VERSION ""

NS_ :

BS_:

BU_: MDC PAS

BO_ 773 Mdc_Sensor_Version: 8 MDC
 SG_ sensorVersion : 2|8@0+ (1,0) [0|8] "bit"  PAS

BO_ 1694 P2_ZPY2_CANFD_14: 64 PAS
 SG_ P2_ZPY2_CANFD_14 : 7|512@0+ (1,0) [0|0] ""  MDC

BO_ 1693 P2_ZPY2_CANFD_13: 64 PAS
 SG_ P2_ZPY2_CANFD_13 : 7|512@0+ (1,0) [0|0] ""  MDC

BO_ 1692 P2_ZPY2_CANFD_12: 64 PAS
 SG_ P2_ZPY2_CANFD_12 : 7|512@0+ (1,0) [0|0] ""  MDC

BO_ 1691 P2_ZPY2_CANFD_11: 64 PAS
 SG_ P2_ZPY2_CANFD_11 : 7|512@0+ (1,0) [0|0] ""  MDC

BO_ 1690 P2_ZPY2_CANFD_10: 64 PAS
 SG_ P2_ZPY2_CANFD_10 : 7|512@0+ (1,0) [0|0] ""  MDC

BO_ 1689 P2_ZPY2_CANFD_9: 64 PAS
 SG_ P2_ZPY2_CANFD_9 : 7|512@0+ (1,0) [0|0] ""  MDC

BO_ 1688 P2_ZPY2_CANFD_8: 64 PAS
 SG_ P2_ZPY2_CANFD_8 : 7|512@0+ (1,0) [0|0] ""  MDC

BO_ 1687 P2_ZPY2_CANFD_7: 64 PAS
 SG_ P2_ZPY2_CANFD_7 : 7|512@0+ (1,0) [0|0] ""  MDC

BO_ 1686 P2_ZPY2_CANFD_6: 64 PAS
 SG_ P2_ZPY2_CANFD_6 : 7|512@0+ (1,0) [0|0] ""  MDC

BO_ 1685 P2_ZPY2_CANFD_5: 64 PAS
 SG_ P2_ZPY2_CANFD_5 : 7|512@0+ (1,0) [0|0] ""  MDC

BO_ 1684 P2_ZPY2_CANFD_4: 64 PAS
 SG_ P2_ZPY2_CANFD_4 : 7|512@0+ (1,0) [0|0] ""  MDC

BO_ 1683 P2_ZPY2_CANFD_3: 64 PAS
 SG_ P2_ZPY2_CANFD_3 : 7|512@0+ (1,0) [0|0] ""  MDC

BO_ 1682 P2_ZPY2_CANFD_2: 64 PAS
 SG_ P2_ZPY2_CANFD_2 : 7|512@0+ (1,0) [0|0] ""  MDC

BO_ 1681 P2_ZPY2_CANFD_1: 64 PAS
 SG_ P2_ZPY2_CANFD_1 : 7|512@0+ (1,0) [0|0] ""  MDC

BO_ 1680 P2_ZPY2_CANFD_0: 64 PAS
 SG_ P2_ZPY2_CANFD_0 : 7|512@0+ (1,0) [0|0] ""  MDC

BO_ 2024 Diag_PDC_RES: 8 PAS
 SG_ Diag_PDC_RES : 7|64@0+ (1,0) [0|0] ""  MDC

BO_ 2016 Diag_PDC_REQ: 8 MDC
 SG_ Diag_PDC_REQ : 7|64@0+ (1,0) [0|0] ""  PAS

BO_ 2015 DIAG_OBD_REQ_Broadcast: 8 MDC
 SG_ Diag_Functional_REQ : 7|64@0+ (1,0) [0|0] ""  PAS

BO_ 513 PAS_Distance_Front: 64 PAS
 SG_ PAS_sonar1_DISTANCE : 455|10@0+ (1,0) [0|1023] "cm"  MDC
 SG_ PASsonar1DISTANCETime : 263|12@0+ (0.5,0) [0|1000] "ms"  MDC
 SG_ PAS_sonar1_Blind : 35|4@0+ (1,0) [0|1] "bit"  MDC
 SG_ PAS_sonar1_crossDistanceLeft : 3|10@0+ (1,0) [0|1023] "cm"  MDC
 SG_ PAS_sonar1_crossDistanceRight : 9|10@0+ (1,0) [0|1023] "cm"  MDC
 SG_ PASsonar1crossDistanceLeftTime : 267|12@0+ (0.5,0) [0|1000] "ms"  MDC
 SG_ PASsonar1crossDistanceRightTime : 287|12@0+ (0.5,0) [0|1000] "ms"  MDC
 SG_ PAS_sonar1_confidence : 31|8@0+ (1,0) [0|100] "%"  MDC
 SG_ Msg201_PAS_sonar1_Counter : 39|4@0+ (1,0) [0|15] "bit"  MDC
 SG_ PAS_sonar2_DISTANCE : 461|10@0+ (1,0) [0|1023] "cm"  MDC
 SG_ PASsonar2DISTANCETime : 291|12@0+ (0.5,0) [0|1000] "ms"  MDC
 SG_ PAS_sonar2_Blind : 75|4@0+ (1,0) [0|1] "bit"  MDC
 SG_ PAS_sonar2_crossDistanceLeft : 43|10@0+ (1,0) [0|1023] "cm"  MDC
 SG_ PAS_sonar2_crossDistanceRight : 49|10@0+ (1,0) [0|1023] "cm"  MDC
 SG_ PASsonar2crossDistanceLeftTime : 311|12@0+ (0.5,0) [0|1000] "ms"  MDC
 SG_ PASsonar2crossDistanceRightTime : 315|12@0+ (0.5,0) [0|1000] "ms"  MDC
 SG_ PAS_sonar2_confidence : 71|8@0+ (1,0) [0|100] "%"  MDC
 SG_ Msg201_PAS_sonar2_Counter : 79|4@0+ (1,0) [0|15] "bit"  MDC
 SG_ PAS_sonar3_DISTANCE : 467|10@0+ (1,0) [0|1023] "cm"  MDC
 SG_ PASsonar3DISTANCETime : 335|12@0+ (0.5,0) [0|1000] "ms"  MDC
 SG_ PAS_sonar3_Blind : 115|4@0+ (1,0) [0|1] "bit"  MDC
 SG_ PAS_sonar3_crossDistanceLeft : 83|10@0+ (1,0) [0|1023] "cm"  MDC
 SG_ PAS_sonar3_crossDistanceRight : 89|10@0+ (1,0) [0|1023] "cm"  MDC
 SG_ PASsonar3crossDistanceLeftTime : 339|12@0+ (0.5,0) [0|1000] "ms"  MDC
 SG_ PASsonar3crossDistanceRightTime : 359|12@0+ (0.5,0) [0|1000] "ms"  MDC
 SG_ PAS_sonar3_confidence : 111|8@0+ (1,0) [0|100] "%"  MDC
 SG_ Msg201_PAS_sonar3_Counter : 119|4@0+ (1,0) [0|15] "bit"  MDC
 SG_ PAS_sonar4_DISTANCE : 473|10@0+ (1,0) [0|1023] "cm"  MDC
 SG_ PASsonar4DISTANCETime : 363|12@0+ (0.5,0) [0|1000] "ms"  MDC
 SG_ PAS_sonar4_Blind : 155|4@0+ (1,0) [0|1] "bit"  MDC
 SG_ PAS_sonar4_crossDistanceLeft : 123|10@0+ (1,0) [0|1023] "cm"  MDC
 SG_ PAS_sonar4_crossDistanceRight : 129|10@0+ (1,0) [0|1023] "cm"  MDC
 SG_ PASsonar4crossDistanceLeftTime : 383|12@0+ (0.5,0) [0|1000] "ms"  MDC
 SG_ PASsonar4crossDistanceRightTime : 387|12@0+ (0.5,0) [0|1000] "ms"  MDC
 SG_ PAS_sonar4_confidence : 151|8@0+ (1,0) [0|100] "%"  MDC
 SG_ Msg201_PAS_sonar4_Counter : 159|4@0+ (1,0) [0|15] "bit"  MDC
 SG_ PAS_sonar0_DISTANCE : 167|10@0+ (1,0) [0|1023] "cm"  MDC
 SG_ PASsonar0DISTANCETime : 407|12@0+ (0.5,0) [0|1000] "ms"  MDC
 SG_ PAS_sonar0_Blind : 235|4@0+ (1,0) [0|1] "bit"  MDC
 SG_ PAS_sonar0_crossDistanceLeft : 173|10@0+ (1,0) [0|1023] "cm"  MDC
 SG_ PAS_sonar0_crossDistanceRight : 179|10@0+ (1,0) [0|1023] "cm"  MDC
 SG_ PASsonar0crossDistanceRightTime : 411|12@0+ (0.5,0) [0|1000] "ms"  MDC
 SG_ PAS_sonar0_confidence : 231|8@0+ (1,0) [0|100] "%"  MDC
 SG_ Msg201_PAS_sonar0_Counter : 239|4@0+ (1,0) [0|15] "bit"  MDC
 SG_ PAS_sonar5_DISTANCE : 185|10@0+ (1,0) [0|1023] "cm"  MDC
 SG_ PASsonar5DISTANCETime : 431|12@0+ (0.5,0) [0|1000] "ms"  MDC
 SG_ PAS_sonar5_Blind : 251|4@0+ (1,0) [0|1] "bit"  MDC
 SG_ PAS_sonar5_crossDistanceLeft : 207|10@0+ (1,0) [0|1023] "cm"  MDC
 SG_ PAS_sonar5_crossDistanceRight : 213|10@0+ (1,0) [0|1023] "cm"  MDC
 SG_ PASsonar5crossDistanceLeftTime : 435|12@0+ (0.5,0) [0|1000] "ms"  MDC
 SG_ PAS_sonar5_confidence : 247|8@0+ (1,0) [0|100] "%"  MDC
 SG_ Msg201_PAS_sonar5_Counter : 255|4@0+ (1,0) [0|15] "bit"  MDC
 SG_ PASDistanceFrontRollingCounter : 511|4@0+ (1,0) [0|14] "bit"  MDC
 SG_ PAS_Distance_Front_Checksum : 503|8@0+ (1,0) [0|255] "bit"  MDC
 SG_ MSG201_Fill4bit : 507|4@0+ (1,0) [0|15] "bit"  MDC

BO_ 514 PAS_Distance_Rear: 64 PAS
 SG_ PAS_sonar7_DISTANCE : 455|10@0+ (1,0) [0|1023] "cm"  MDC
 SG_ PASsonar7DISTANCETime : 263|12@0+ (0.5,0) [0|1000] "ms"  MDC
 SG_ PAS_sonar7_Blind : 35|4@0+ (1,0) [0|1] "bit"  MDC
 SG_ PAS_sonar7_crossDistanceLeft : 3|10@0+ (1,0) [0|1023] "cm"  MDC
 SG_ PAS_sonar7_crossDistanceRight : 9|10@0+ (1,0) [0|1023] "cm"  MDC
 SG_ PASsonar7crossDistanceLeftTime : 267|12@0+ (0.5,0) [0|1000] "ms"  MDC
 SG_ PASsonar7crossDistanceRightTime : 287|12@0+ (0.5,0) [0|1000] "ms"  MDC
 SG_ PAS_sonar7_confidence : 31|8@0+ (1,0) [0|100] "%"  MDC
 SG_ Msg202_PAS_sonar7_Counter : 39|4@0+ (1,0) [0|15] "bit"  MDC
 SG_ PAS_sonar8_DISTANCE : 461|10@0+ (1,0) [0|1023] "cm"  MDC
 SG_ PASsonar8DISTANCETime : 291|12@0+ (0.5,0) [0|1000] "ms"  MDC
 SG_ PAS_sonar8_Blind : 75|4@0+ (1,0) [0|1] "bit"  MDC
 SG_ PAS_sonar8_crossDistanceLeft : 43|10@0+ (1,0) [0|1023] "cm"  MDC
 SG_ PAS_sonar8_crossDistanceRight : 49|10@0+ (1,0) [0|1023] "cm"  MDC
 SG_ PASsonar8crossDistanceLeftTime : 311|12@0+ (0.5,0) [0|1000] "ms"  MDC
 SG_ PASsonar8crossDistanceRightTime : 315|12@0+ (0.5,0) [0|1000] "ms"  MDC
 SG_ PAS_sonar8_confidence : 71|8@0+ (1,0) [0|100] "%"  MDC
 SG_ Msg202_PAS_sonar8_Counter : 79|4@0+ (1,0) [0|15] "bit"  MDC
 SG_ PAS_sonar9_DISTANCE : 467|10@0+ (1,0) [0|1023] "cm"  MDC
 SG_ PASsonar9DISTANCETime : 335|12@0+ (0.5,0) [0|1000] "ms"  MDC
 SG_ PAS_sonar9_Blind : 115|4@0+ (1,0) [0|1] "bit"  MDC
 SG_ PAS_sonar9_crossDistanceLeft : 83|10@0+ (1,0) [0|1023] "cm"  MDC
 SG_ PAS_sonar9_crossDistanceRight : 89|10@0+ (1,0) [0|1023] "cm"  MDC
 SG_ PASsonar9crossDistanceLeftTime : 339|12@0+ (0.5,0) [0|1000] "ms"  MDC
 SG_ PASsonar9crossDistanceRightTime : 359|12@0+ (0.5,0) [0|1000] "ms"  MDC
 SG_ PAS_sonar9_confidence : 111|8@0+ (1,0) [0|100] "%"  MDC
 SG_ Msg202_PAS_sonar9_Counter : 119|4@0+ (1,0) [0|15] "bit"  MDC
 SG_ PAS_sonar10_DISTANCE : 473|10@0+ (1,0) [0|1023] "cm"  MDC
 SG_ PASsonar10DISTANCETime : 363|12@0+ (0.5,0) [0|1000] "ms"  MDC
 SG_ PAS_sonar10_Blind : 155|4@0+ (1,0) [0|1] "bit"  MDC
 SG_ PAS_sonar10_crossDistanceLeft : 123|10@0+ (1,0) [0|1023] "cm"  MDC
 SG_ PAS_sonar10_crossDistanceRight : 129|10@0+ (1,0) [0|1023] "cm"  MDC
 SG_ PASsonar10crossDistanceLeftTime : 383|12@0+ (0.5,0) [0|1000] "ms"  MDC
 SG_ PASsonar10crossDistanceRightTime : 387|12@0+ (0.5,0) [0|1000] "ms"  MDC
 SG_ PAS_sonar10_confidence : 151|8@0+ (1,0) [0|100] "%"  MDC
 SG_ Msg202_PAS_sonar10_Counter : 159|4@0+ (1,0) [0|15] "bit"  MDC
 SG_ PAS_sonar6_DISTANCE : 167|10@0+ (1,0) [0|1023] "cm"  MDC
 SG_ PASsonar6DISTANCETime : 407|12@0+ (0.5,0) [0|1000] "ms"  MDC
 SG_ PAS_sonar6_Blind : 235|4@0+ (1,0) [0|1] "bit"  MDC
 SG_ PAS_sonar6_crossDistanceLeft : 173|10@0+ (1,0) [0|1023] "cm"  MDC
 SG_ PAS_sonar6_crossDistanceRight : 179|10@0+ (1,0) [0|1023] "cm"  MDC
 SG_ PASsonar6crossDistanceRightTime : 411|12@0+ (0.5,0) [0|1000] "ms"  MDC
 SG_ PAS_sonar6_confidence : 231|8@0+ (1,0) [0|100] "%"  MDC
 SG_ Msg202_PAS_sonar6_Counter : 239|4@0+ (1,0) [0|15] "bit"  MDC
 SG_ PAS_sonar11_DISTANCE : 185|10@0+ (1,0) [0|1023] "cm"  MDC
 SG_ PASsonar11DISTANCETime : 431|12@0+ (0.5,0) [0|1000] "ms"  MDC
 SG_ PAS_sonar11_Blind : 251|4@0+ (1,0) [0|1] "bit"  MDC
 SG_ PAS_sonar11_crossDistanceLeft : 207|10@0+ (1,0) [0|1023] "cm"  MDC
 SG_ PAS_sonar11_crossDistanceRight : 213|10@0+ (1,0) [0|1023] "cm"  MDC
 SG_ PASsonar11crossDistanceLeftTime : 435|12@0+ (0.5,0) [0|1000] "ms"  MDC
 SG_ PAS_sonar11_confidence : 247|8@0+ (1,0) [0|100] "%"  MDC
 SG_ Msg202_PAS_sonar11_Counter : 255|4@0+ (1,0) [0|15] "bit"  MDC
 SG_ PAS_Distance_Rear_RollingCounter : 511|4@0+ (1,0) [0|14] "bit"  MDC
 SG_ PAS_Distance_Rear_Checksum : 503|8@0+ (1,0) [0|255] "bit"  MDC
 SG_ MSG202_Fill4bit : 507|4@0+ (1,0) [0|15] "bit"  MDC

BO_ 515 PAS_SonarInfo_Front: 64 PAS
 SG_ PAS_Sonar0_Echo_TOF1 : 7|16@0+ (1,0) [0|65535] "us"  MDC
 SG_ PAS_Sonar0_Echo_Width1 : 23|8@0+ (16,0) [0|4080] "us"  MDC
 SG_ PAS_Sonar0_Echo_TOF2 : 31|16@0+ (1,0) [0|65535] "us"  MDC
 SG_ PAS_Sonar0_Echo_Width2 : 47|8@0+ (16,0) [0|4080] "us"  MDC
 SG_ PAS_Sonar0_Echo_Peak1 : 391|6@0+ (1,0) [0|63] ""  MDC
 SG_ PAS_Sonar0_Echo_Peak2 : 385|6@0+ (1,0) [0|63] ""  MDC
 SG_ PAS_Sonar0_Emit : 457|2@0+ (1,0) [0|2] "bit"  MDC
 SG_ PAS_Sonar0_RingingTime : 55|16@0+ (0.0412,300) [300|3000] "us"  MDC
 SG_ Msg203_PAS_Sonar0_Counter : 471|4@0+ (1,0) [0|15] "bit"  MDC
 SG_ PAS_Sonar1_Echo_TOF1 : 71|16@0+ (1,0) [0|65535] "us"  MDC
 SG_ PAS_Sonar1_Echo_Width1 : 87|8@0+ (16,0) [0|4080] "us"  MDC
 SG_ PAS_Sonar1_Echo_TOF2 : 95|16@0+ (1,0) [0|65535] "us"  MDC
 SG_ PAS_Sonar1_Echo_Width2 : 111|8@0+ (16,0) [0|4080] "us"  MDC
 SG_ PAS_Sonar1_Echo_Peak1 : 395|6@0+ (1,0) [0|63] ""  MDC
 SG_ PAS_Sonar1_Echo_Peak2 : 405|6@0+ (1,0) [0|63] ""  MDC
 SG_ PAS_Sonar1_Emit : 459|2@0+ (1,0) [0|2] "bit"  MDC
 SG_ PAS_Sonar1_RingingTime : 119|16@0+ (0.0412,300) [300|3000] "us"  MDC
 SG_ Msg203_PAS_Sonar1_Counter : 475|4@0+ (1,0) [0|15] "bit"  MDC
 SG_ PAS_Sonar2_Echo_TOF1 : 135|16@0+ (1,0) [0|65535] "us"  MDC
 SG_ PAS_Sonar2_Echo_Width1 : 151|8@0+ (16,0) [0|4080] "us"  MDC
 SG_ PAS_Sonar2_Echo_TOF2 : 159|16@0+ (1,0) [0|65535] "us"  MDC
 SG_ PAS_Sonar2_Echo_Width2 : 175|8@0+ (16,0) [0|4080] "us"  MDC
 SG_ PAS_Sonar2_Echo_Peak1 : 415|6@0+ (1,0) [0|63] ""  MDC
 SG_ PAS_Sonar2_Echo_Peak2 : 409|6@0+ (1,0) [0|63] ""  MDC
 SG_ PAS_Sonar2_Emit : 461|2@0+ (1,0) [0|2] "bit"  MDC
 SG_ PAS_Sonar2_RingingTime : 183|16@0+ (0.0412,300) [300|3000] "us"  MDC
 SG_ Msg203_PAS_Sonar2_Counter : 479|4@0+ (1,0) [0|15] "bit"  MDC
 SG_ PAS_Sonar3_Echo_TOF1 : 199|16@0+ (1,0) [0|65535] "us"  MDC
 SG_ PAS_Sonar3_Echo_Width1 : 215|8@0+ (16,0) [0|4080] "us"  MDC
 SG_ PAS_Sonar3_Echo_TOF2 : 223|16@0+ (1,0) [0|65535] "us"  MDC
 SG_ PAS_Sonar3_Echo_Width2 : 239|8@0+ (16,0) [0|4080] "us"  MDC
 SG_ PAS_Sonar3_Echo_Peak1 : 419|6@0+ (1,0) [0|63] ""  MDC
 SG_ PAS_Sonar3_Echo_Peak2 : 429|6@0+ (1,0) [0|63] ""  MDC
 SG_ PAS_Sonar3_Emit : 463|2@0+ (1,0) [0|2] "bit"  MDC
 SG_ PAS_Sonar3_RingingTime : 247|16@0+ (0.0412,300) [300|3000] "us"  MDC
 SG_ Msg203_PAS_Sonar3_Counter : 483|4@0+ (1,0) [0|15] "bit"  MDC
 SG_ PAS_Sonar4_Echo_TOF1 : 263|16@0+ (1,0) [0|65535] "us"  MDC
 SG_ PAS_Sonar4_Echo_Width1 : 279|8@0+ (16,0) [0|4080] "us"  MDC
 SG_ PAS_Sonar4_Echo_TOF2 : 287|16@0+ (1,0) [0|65535] "us"  MDC
 SG_ PAS_Sonar4_Echo_Width2 : 303|8@0+ (16,0) [0|4080] "us"  MDC
 SG_ PAS_Sonar4_Echo_Peak1 : 439|6@0+ (1,0) [0|63] ""  MDC
 SG_ PAS_Sonar4_Echo_Peak2 : 433|6@0+ (1,0) [0|63] ""  MDC
 SG_ PAS_Sonar4_Emit : 465|2@0+ (1,0) [0|2] "bit"  MDC
 SG_ PAS_Sonar4_RingingTime : 311|16@0+ (0.0412,300) [300|3000] "us"  MDC
 SG_ Msg203_PAS_Sonar4_Counter : 487|4@0+ (1,0) [0|15] "bit"  MDC
 SG_ PAS_Sonar5_Echo_TOF1 : 327|16@0+ (1,0) [0|65535] "us"  MDC
 SG_ PAS_Sonar5_Echo_Width1 : 343|8@0+ (16,0) [0|4080] "us"  MDC
 SG_ PAS_Sonar5_Echo_TOF2 : 351|16@0+ (1,0) [0|65535] "us"  MDC
 SG_ PAS_Sonar5_Echo_Width2 : 367|8@0+ (16,0) [0|4080] "us"  MDC
 SG_ PAS_Sonar5_Echo_Peak1 : 443|6@0+ (1,0) [0|63] ""  MDC
 SG_ PAS_Sonar5_Echo_Peak2 : 453|6@0+ (1,0) [0|63] ""  MDC
 SG_ PAS_Sonar5_Emit : 467|2@0+ (1,0) [0|2] "bit"  MDC
 SG_ PAS_Sonar5_RingingTime : 375|16@0+ (0.0412,300) [300|3000] "us"  MDC
 SG_ Msg203_PAS_Sonar5_Counter : 491|4@0+ (1,0) [0|15] "bit"  MDC
 SG_ PASSonarInfoFrontRollingCounter : 507|4@0+ (1,0) [0|14] "bit"  MDC
 SG_ PAS_SonarInfo_Front_Checksum : 503|8@0+ (1,0) [0|255] "bit"  MDC
 SG_ MSG203_Fill4bit : 511|4@0+ (1,0) [0|15] "bit"  MDC

BO_ 517 PAS_SonarInfo_Rear: 64 PAS
 SG_ PAS_Sonar6_Echo_TOF1 : 7|16@0+ (1,0) [0|65535] "us"  MDC
 SG_ PAS_Sonar6_Echo_Width1 : 23|8@0+ (16,0) [0|4080] "us"  MDC
 SG_ PAS_Sonar6_Echo_TOF2 : 31|16@0+ (1,0) [0|65535] "us"  MDC
 SG_ PAS_Sonar6_Echo_Width2 : 47|8@0+ (16,0) [0|4080] "us"  MDC
 SG_ PAS_Sonar6_Echo_Peak1 : 391|6@0+ (1,0) [0|63] ""  MDC
 SG_ PAS_Sonar6_Echo_Peak2 : 385|6@0+ (1,0) [0|63] ""  MDC
 SG_ PAS_Sonar6_Emit : 457|2@0+ (1,0) [0|2] "bit"  MDC
 SG_ PAS_Sonar6_RingingTime : 55|16@0+ (0.0412,300) [300|3000] "us"  MDC
 SG_ Msg205_PAS_Sonar6_Counter : 471|4@0+ (1,0) [0|15] "bit"  MDC
 SG_ PAS_Sonar7_Echo_TOF1 : 71|16@0+ (1,0) [0|65535] "us"  MDC
 SG_ PAS_Sonar7_Echo_Width1 : 87|8@0+ (16,0) [0|4080] "us"  MDC
 SG_ PAS_Sonar7_Echo_TOF2 : 95|16@0+ (1,0) [0|65535] "us"  MDC
 SG_ PAS_Sonar7_Echo_Width2 : 111|8@0+ (16,0) [0|4080] "us"  MDC
 SG_ PAS_Sonar7_Echo_Peak1 : 395|6@0+ (1,0) [0|63] ""  MDC
 SG_ PAS_Sonar7_Echo_Peak2 : 405|6@0+ (1,0) [0|63] ""  MDC
 SG_ PAS_Sonar7_Emit : 459|2@0+ (1,0) [0|2] "bit"  MDC
 SG_ PAS_Sonar7_RingingTime : 119|16@0+ (0.0412,300) [300|3000] "us"  MDC
 SG_ Msg205_PAS_Sonar7_Counter : 475|4@0+ (1,0) [0|15] "bit"  MDC
 SG_ PAS_Sonar8_Echo_TOF1 : 135|16@0+ (1,0) [0|65535] "us"  MDC
 SG_ PAS_Sonar8_Echo_Width1 : 151|8@0+ (16,0) [0|4080] "us"  MDC
 SG_ PAS_Sonar8_Echo_TOF2 : 159|16@0+ (1,0) [0|65535] "us"  MDC
 SG_ PAS_Sonar8_Echo_Width2 : 175|8@0+ (16,0) [0|4080] "us"  MDC
 SG_ PAS_Sonar8_Echo_Peak1 : 415|6@0+ (1,0) [0|63] ""  MDC
 SG_ PAS_Sonar8_Echo_Peak2 : 409|6@0+ (1,0) [0|63] ""  MDC
 SG_ PAS_Sonar8_Emit : 461|2@0+ (1,0) [0|2] "bit"  MDC
 SG_ PAS_Sonar8_RingingTime : 183|16@0+ (0.0412,300) [300|3000] "us"  MDC
 SG_ Msg205_PAS_Sonar8_Counter : 479|4@0+ (1,0) [0|15] "bit"  MDC
 SG_ PAS_Sonar9_Echo_TOF1 : 199|16@0+ (1,0) [0|65535] "us"  MDC
 SG_ PAS_Sonar9_Echo_Width1 : 215|8@0+ (16,0) [0|4080] "us"  MDC
 SG_ PAS_Sonar9_Echo_TOF2 : 223|16@0+ (1,0) [0|65535] "us"  MDC
 SG_ PAS_Sonar9_Echo_Width2 : 239|8@0+ (16,0) [0|4080] "us"  MDC
 SG_ PAS_Sonar9_Echo_Peak1 : 419|6@0+ (1,0) [0|63] ""  MDC
 SG_ PAS_Sonar9_Echo_Peak2 : 429|6@0+ (1,0) [0|63] ""  MDC
 SG_ PAS_Sonar9_Emit : 463|2@0+ (1,0) [0|2] "bit"  MDC
 SG_ PAS_Sonar9_RingingTime : 247|16@0+ (0.0412,300) [300|3000] "us"  MDC
 SG_ Msg205_PAS_Sonar9_Counter : 483|4@0+ (1,0) [0|15] "bit"  MDC
 SG_ PAS_Sonar10_Echo_TOF1 : 263|16@0+ (1,0) [0|65535] "us"  MDC
 SG_ PAS_Sonar10_Echo_Width1 : 279|8@0+ (16,0) [0|4080] "us"  MDC
 SG_ PAS_Sonar10_Echo_TOF2 : 287|16@0+ (1,0) [0|65535] "us"  MDC
 SG_ PAS_Sonar10_Echo_Width2 : 303|8@0+ (16,0) [0|4080] "us"  MDC
 SG_ PAS_Sonar10_Echo_Peak1 : 439|6@0+ (1,0) [0|63] ""  MDC
 SG_ PAS_Sonar10_Echo_Peak2 : 433|6@0+ (1,0) [0|63] ""  MDC
 SG_ PAS_Sonar10_Emit : 465|2@0+ (1,0) [0|2] "bit"  MDC
 SG_ PAS_Sonar10_RingingTime : 311|16@0+ (0.0412,300) [300|3000] "us"  MDC
 SG_ Msg205_PAS_Sonar10_Counter : 487|4@0+ (1,0) [0|15] "bit"  MDC
 SG_ PAS_Sonar11_Echo_TOF1 : 327|16@0+ (1,0) [0|65535] "us"  MDC
 SG_ PAS_Sonar11_Echo_Width1 : 343|8@0+ (16,0) [0|4080] "us"  MDC
 SG_ PAS_Sonar11_Echo_TOF2 : 351|16@0+ (1,0) [0|65535] "us"  MDC
 SG_ PAS_Sonar11_Echo_Width2 : 367|8@0+ (16,0) [0|4080] "us"  MDC
 SG_ PAS_Sonar11_Echo_Peak1 : 443|6@0+ (1,0) [0|63] ""  MDC
 SG_ PAS_Sonar11_Echo_Peak2 : 453|6@0+ (1,0) [0|63] ""  MDC
 SG_ PAS_Sonar11_Emit : 467|2@0+ (1,0) [0|2] "bit"  MDC
 SG_ PAS_Sonar11_RingingTime : 375|16@0+ (0.0412,300) [300|3000] "us"  MDC
 SG_ MSG205_PAS_Sonar11_Counter : 491|4@0+ (1,0) [0|15] "bit"  MDC
 SG_ PASSonarInfoRearRollingCounter : 507|4@0+ (1,0) [0|14] "bit"  MDC
 SG_ PAS_SonarInfo_Rear_Checksum : 503|8@0+ (1,0) [0|255] "bit"  MDC
 SG_ MSG205_Fill4bit : 511|4@0+ (1,0) [0|15] "bit"  MDC

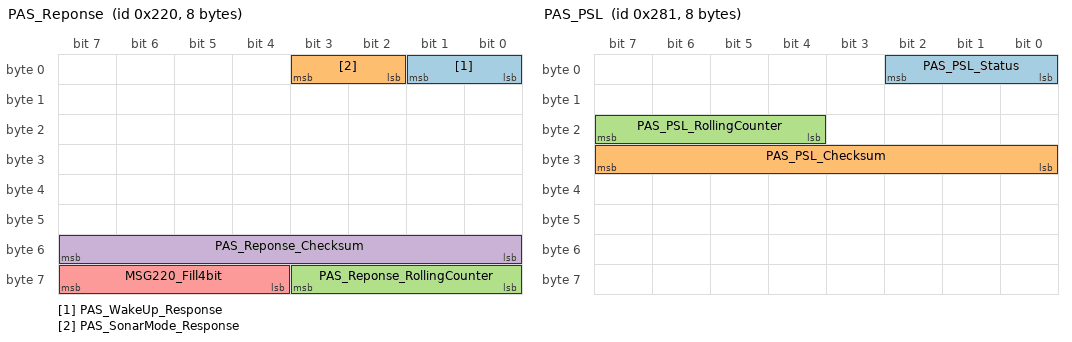
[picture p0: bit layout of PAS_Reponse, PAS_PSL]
BO_ 544 PAS_Reponse: 8 PAS
 SG_ PAS_WakeUp_Response : 1|2@0+ (1,0) [0|1] "bit"  MDC
 SG_ PAS_SonarMode_Response : 3|2@0+ (1,0) [0|1] "bit"  MDC
 SG_ PAS_Reponse_RollingCounter : 59|4@0+ (1,0) [0|14] "bit"  MDC
 SG_ PAS_Reponse_Checksum : 55|8@0+ (1,0) [0|255] "bit"  MDC
 SG_ MSG220_Fill4bit : 63|4@0+ (1,0) [0|15] "bit"  MDC

BO_ 560 PAS_SensorStatus: 8 PAS
 SG_ sensorVersion_Status : 33|2@0+ (1,0) [0|1] "bit"  MDC
 SG_ PAS_SensorStsLR_FLS : 1|2@0+ (1,0) [0|1] "bit"  MDC
 SG_ PAS_SensorStsLR_FRS : 3|2@0+ (1,0) [0|1] "bit"  MDC
 SG_ PAS_SensorStsSR_FL : 5|2@0+ (1,0) [0|1] "bit"  MDC
 SG_ PAS_SensorStsSR_FML : 7|2@0+ (1,0) [0|1] "bit"  MDC
 SG_ PAS_SensorStsSR_FMR : 9|2@0+ (1,0) [0|1] "bit"  MDC
 SG_ PAS_SensorStsSR_FR : 11|2@0+ (1,0) [0|1] "bit"  MDC
 SG_ PAS_SensorStsLR_RLS : 13|2@0+ (1,0) [0|1] "bit"  MDC
 SG_ PAS_SensorStsLR_RRS : 15|2@0+ (1,0) [0|1] "bit"  MDC
 SG_ PAS_SensorStsSR_RL : 17|2@0+ (1,0) [0|1] "bit"  MDC
 SG_ PAS_SensorStsSR_RML : 19|2@0+ (1,0) [0|1] "bit"  MDC
 SG_ PAS_SensorStsSR_RMR : 21|2@0+ (1,0) [0|1] "bit"  MDC
 SG_ PAS_SensorStsSR_RR : 23|2@0+ (1,0) [0|1] "bit"  MDC
 SG_ PAS_ECU_Status : 25|2@0+ (1,0) [0|1] "bit"  MDC
 SG_ PAS_ECU_VehStatus_Reponse : 27|2@0+ (1,0) [0|1] "bit"  MDC
 SG_ PAS_SensorStatus_RollingCounter : 59|4@0+ (1,0) [0|14] "bit"  MDC
 SG_ PAS_SensorStatus_Checksum : 55|8@0+ (1,0) [0|255] "bit"  MDC
 SG_ MSG230_Fill4bit : 63|4@0+ (1,0) [0|15] "bit"  MDC

BO_ 576 PAS_ECU_Version: 12 PAS
 SG_ PAS_ECU_Information_Ver_Hard : 7|8@0+ (1,0) [0|255] "bit"  MDC
 SG_ PAS_ECU_Information_Ver_Soft : 15|8@0+ (1,0) [0|255] "bit"  MDC
 SG_ PAS_ECU_Information_Ver_Boot : 23|8@0+ (1,0) [0|255] "bit"  MDC
 SG_ PAS_ECU_Information_Date_Year : 31|16@0+ (1,0) [0|65535] "bit"  MDC
 SG_ PAS_ECU_Information_Date_Month : 47|8@0+ (1,0) [0|255] "bit"  MDC
 SG_ PAS_ECU_Information_Date_Day : 55|8@0+ (1,0) [0|255] "bit"  MDC
 SG_ PAS_ECU_Version_Checksum : 87|8@0+ (1,0) [0|255] "bit"  MDC
 SG_ PAS_ECUInfo_RollingCounter : 91|4@0+ (1,0) [0|14] "bit"  MDC
 SG_ MSG240_Fill4bit : 95|4@0+ (1,0) [0|15] "bit"  MDC

BO_ 592 PAS_RptAlarm: 12 PAS
 SG_ Rpt_Alarm_Id : 7|8@0+ (1,0) [0|64] "bit"  MDC
 SG_ Rpt_Alarm_State : 8|1@0+ (1,0) [0|1] "bit"  MDC
 SG_ Rpt_Alarm_Level : 11|2@0+ (1,0) [0|2] "bit"  MDC
 SG_ Rpt_Transaction_Id : 15|4@0+ (1,0) [0|15] "bit"  MDC
 SG_ Rpt_Alarm_Para1 : 23|16@0+ (1,0) [0|65535] "bit"  MDC
 SG_ Rpt_Alarm_Para2 : 39|16@0+ (1,0) [0|65535] "bit"  MDC
 SG_ Rpt_Alarm_Para3 : 55|16@0+ (1,0) [0|65535] "bit"  MDC
 SG_ Rpt_Alarm_Checksum : 87|8@0+ (1,0) [0|255] "bit"  MDC
 SG_ Rpt_Alarm_RollingCounter : 91|4@0+ (1,0) [0|14] "bit"  MDC
 SG_ MSG250_Fill4bit : 95|4@0+ (1,0) [0|15] "bit"  MDC

BO_ 593 PAS_DiagnosisInfo: 16 PAS
 SG_ USS_Front_ShortToGND : 61|1@0+ (1,0) [0|1] "bit"  MDC
 SG_ USS_Front_ShortToUbat : 62|1@0+ (1,0) [0|1] "bit"  MDC
 SG_ USS_Rear_ShortToGND : 63|1@0+ (1,0) [0|1] "bit"  MDC
 SG_ USS_Rear_ShortToUbat : 69|1@0+ (1,0) [0|1] "bit"  MDC
 SG_ VHM_Error : 70|1@0+ (1,0) [0|1] "bit"  MDC
 SG_ Sensor_Version_Fail : 71|1@0+ (1,0) [0|1] "bit"  MDC
 SG_ PAS_Sonar0_Internal_failure : 29|1@0+ (1,0) [0|1] "bit"  MDC
 SG_ PAS_Sonar1_Internal_failure : 30|1@0+ (1,0) [0|1] "bit"  MDC
 SG_ PAS_Sonar2_Internal_failure : 31|1@0+ (1,0) [0|1] "bit"  MDC
 SG_ PAS_Sonar3_Internal_failure : 37|1@0+ (1,0) [0|1] "bit"  MDC
 SG_ PAS_Sonar4_Internal_failure : 38|1@0+ (1,0) [0|1] "bit"  MDC
 SG_ PAS_Sonar5_Internal_failure : 39|1@0+ (1,0) [0|1] "bit"  MDC
 SG_ PAS_Sonar6_Internal_failure : 45|1@0+ (1,0) [0|1] "bit"  MDC
 SG_ PAS_Sonar7_Internal_failure : 46|1@0+ (1,0) [0|1] "bit"  MDC
 SG_ PAS_Sonar8_Internal_failure : 47|1@0+ (1,0) [0|1] "bit"  MDC
 SG_ PAS_Sonar9_Internal_failure : 53|1@0+ (1,0) [0|1] "bit"  MDC
 SG_ PAS_Sonar10_Internal_failure : 54|1@0+ (1,0) [0|1] "bit"  MDC
 SG_ PAS_Sonar11_Internal_failure : 55|1@0+ (1,0) [0|1] "bit"  MDC
 SG_ PAS_AUTHEN_ERROR : 108|1@0+ (1,0) [0|1] "bit"  MDC
 SG_ PAS_KEYLEARN_ERROR : 107|1@0+ (1,0) [0|1] "bit"  MDC
 SG_ PAS_TIMESYNC_ERROR : 106|1@0+ (1,0) [0|1] "bit"  MDC
 SG_ PAS_ECU_INTERNAL_ERROR : 105|1@0+ (1,0) [0|1] "bit"  MDC
 SG_ PAS_MDCSIGNAL_ERROR : 109|1@0+ (1,0) [0|1] "bit"  MDC
 SG_ PAS_Sonar1_ControlBusFailure : 0|1@0+ (1,0) [0|1] "bit"  MDC
 SG_ PAS_Sonar1_RingingTimeFailure : 1|1@0+ (1,0) [0|1] "bit"  MDC
 SG_ PAS_Sonar1_ShortToGND : 2|1@0+ (1,0) [0|1] "bit"  MDC
 SG_ PAS_Sonar1_ShortToPositivePole : 3|1@0+ (1,0) [0|1] "bit"  MDC
 SG_ PAS_Sonar1_TypeMismatch : 4|1@0+ (1,0) [0|1] "bit"  MDC
 SG_ PAS_Sonar2_ControlBusFailure : 8|1@0+ (1,0) [0|1] "bit"  MDC
 SG_ PAS_Sonar2_RingingTimeFailure : 9|1@0+ (1,0) [0|1] "bit"  MDC
 SG_ PAS_Sonar2_ShortToGND : 10|1@0+ (1,0) [0|1] "bit"  MDC
 SG_ PAS_Sonar2_ShortToPositivePole : 11|1@0+ (1,0) [0|1] "bit"  MDC
 SG_ PAS_Sonar2_TypeMismatch : 12|1@0+ (1,0) [0|1] "bit"  MDC
 SG_ PAS_Sonar3_ControlBusFailure : 16|1@0+ (1,0) [0|1] "bit"  MDC
 SG_ PAS_Sonar3_RingingTimeFailure : 17|1@0+ (1,0) [0|1] "bit"  MDC
 SG_ PAS_Sonar3_ShortToGND : 18|1@0+ (1,0) [0|1] "bit"  MDC
 SG_ PAS_Sonar3_ShortToPositivePole : 19|1@0+ (1,0) [0|1] "bit"  MDC
 SG_ PAS_Sonar3_TypeMismatch : 20|1@0+ (1,0) [0|1] "bit"  MDC
 SG_ PAS_Sonar3_PowerVoltage_Low : 21|1@0+ (1,0) [0|1] "bit"  MDC
 SG_ PAS_Sonar3_PowerVoltage_High : 22|1@0+ (1,0) [0|1] "bit"  MDC
 SG_ PAS_Sonar4_ControlBusFailure : 24|1@0+ (1,0) [0|1] "bit"  MDC
 SG_ PAS_Sonar4_RingingTimeFailure : 25|1@0+ (1,0) [0|1] "bit"  MDC
 SG_ PAS_Sonar4_ShortToGND : 26|1@0+ (1,0) [0|1] "bit"  MDC
 SG_ PAS_Sonar4_ShortToPositivePole : 27|1@0+ (1,0) [0|1] "bit"  MDC
 SG_ PAS_Sonar4_TypeMismatch : 28|1@0+ (1,0) [0|1] "bit"  MDC
 SG_ PAS_Sonar7_ControlBusFailure : 32|1@0+ (1,0) [0|1] "bit"  MDC
 SG_ PAS_Sonar7_RingingTimeFailure : 33|1@0+ (1,0) [0|1] "bit"  MDC
 SG_ PAS_Sonar7_ShortToGND : 34|1@0+ (1,0) [0|1] "bit"  MDC
 SG_ PAS_Sonar7_ShortToPositivePole : 35|1@0+ (1,0) [0|1] "bit"  MDC
 SG_ PAS_Sonar7_TypeMismatch : 36|1@0+ (1,0) [0|1] "bit"  MDC
 SG_ PAS_Sonar8_ControlBusFailure : 40|1@0+ (1,0) [0|1] "bit"  MDC
 SG_ PAS_Sonar8_RingingTimeFailure : 41|1@0+ (1,0) [0|1] "bit"  MDC
 SG_ PAS_Sonar8_ShortToGND : 42|1@0+ (1,0) [0|1] "bit"  MDC
 SG_ PAS_Sonar8_ShortToPositivePole : 43|1@0+ (1,0) [0|1] "bit"  MDC
 SG_ PAS_Sonar8_TypeMismatch : 44|1@0+ (1,0) [0|1] "bit"  MDC
 SG_ PAS_Sonar9_ControlBusFailure : 48|1@0+ (1,0) [0|1] "bit"  MDC
 SG_ PAS_Sonar9_RingingTimeFailure : 49|1@0+ (1,0) [0|1] "bit"  MDC
 SG_ PAS_Sonar9_ShortToGND : 50|1@0+ (1,0) [0|1] "bit"  MDC
 SG_ PAS_Sonar9_ShortToPositivePole : 51|1@0+ (1,0) [0|1] "bit"  MDC
 SG_ PAS_Sonar9_TypeMismatch : 52|1@0+ (1,0) [0|1] "bit"  MDC
 SG_ PAS_Sonar10_ControlBusFailure : 56|1@0+ (1,0) [0|1] "bit"  MDC
 SG_ PAS_Sonar10_RingingTimeFailure : 57|1@0+ (1,0) [0|1] "bit"  MDC
 SG_ PAS_Sonar10_ShortToGND : 58|1@0+ (1,0) [0|1] "bit"  MDC
 SG_ PAS_Sonar10_ShortToPositivePole : 59|1@0+ (1,0) [0|1] "bit"  MDC
 SG_ PAS_Sonar10_TypeMismatch : 60|1@0+ (1,0) [0|1] "bit"  MDC
 SG_ PAS_Sonar0_ControlBusFailure : 64|1@0+ (1,0) [0|1] "bit"  MDC
 SG_ PAS_Sonar0_RingingTimeFailure : 65|1@0+ (1,0) [0|1] "bit"  MDC
 SG_ PAS_Sonar0_ShortToGND : 66|1@0+ (1,0) [0|1] "bit"  MDC
 SG_ PAS_Sonar0_ShortToPositivePole : 67|1@0+ (1,0) [0|1] "bit"  MDC
 SG_ PAS_Sonar0_TypeMismatch : 68|1@0+ (1,0) [0|1] "bit"  MDC
 SG_ PAS_Sonar5_ControlBusFailure : 72|1@0+ (1,0) [0|1] "bit"  MDC
 SG_ PAS_Sonar5_RingingTimeFailure : 73|1@0+ (1,0) [0|1] "bit"  MDC
 SG_ PAS_Sonar5_ShortToGND : 74|1@0+ (1,0) [0|1] "bit"  MDC
 SG_ PAS_Sonar5_ShortToPositivePole : 75|1@0+ (1,0) [0|1] "bit"  MDC
 SG_ PAS_Sonar5_TypeMismatch : 76|1@0+ (1,0) [0|1] "bit"  MDC
 SG_ PAS_Sonar6_ControlBusFailure : 80|1@0+ (1,0) [0|1] "bit"  MDC
 SG_ PAS_Sonar6_RingingTimeFailure : 81|1@0+ (1,0) [0|1] "bit"  MDC
 SG_ PAS_Sonar6_ShortToGND : 82|1@0+ (1,0) [0|1] "bit"  MDC
 SG_ PAS_Sonar6_ShortToPositivePole : 83|1@0+ (1,0) [0|1] "bit"  MDC
 SG_ PAS_Sonar6_TypeMismatch : 84|1@0+ (1,0) [0|1] "bit"  MDC
 SG_ PAS_Sonar11_ControlBusFailure : 88|1@0+ (1,0) [0|1] "bit"  MDC
 SG_ PAS_Sonar11_RingingTimeFailure : 89|1@0+ (1,0) [0|1] "bit"  MDC
 SG_ PAS_Sonar11_ShortToGND : 90|1@0+ (1,0) [0|1] "bit"  MDC
 SG_ PAS_Sonar11_ShortToPositivePole : 91|1@0+ (1,0) [0|1] "bit"  MDC
 SG_ PAS_Sonar11_TypeMismatch : 92|1@0+ (1,0) [0|1] "bit"  MDC
 SG_ PAS_ECU_OverVoltage : 96|1@0+ (1,0) [0|1] "bit"  MDC
 SG_ PAS_ECU_UnderVoltage : 97|1@0+ (1,0) [0|1] "bit"  MDC
 SG_ PAS_ECU_BusOff_ERROR : 98|1@0+ (1,0) [0|1] "bit"  MDC
 SG_ PAS_MDC_COMMU_ERROR : 99|1@0+ (1,0) [0|1] "bit"  MDC
 SG_ PAS_ECU_EEPROM_ERROR : 100|1@0+ (1,0) [0|1] "bit"  MDC
 SG_ PAS_DiagnosisInfo_RollingCounter : 123|4@0+ (1,0) [0|14] "bit"  MDC
 SG_ PAS_DiagnosisInfo_Checksum : 119|8@0+ (1,0) [0|255] "bit"  MDC
 SG_ MSG251_Fill4bit : 127|4@0+ (1,0) [0|15] "bit"  MDC

BO_ 672 PAS_DeviceVertifyReq: 8 PAS
 SG_ PAS_Device_Vertify_Times : 7|8@0+ (1,0) [0|255] ""  MDC
 SG_ PAS_Device_Vertify_Status : 15|8@0+ (1,0) [0|0] ""  MDC

BO_ 673 PAS_Challenge_K1: 12 PAS
 SG_ PAS_RandomByte1 : 7|8@0+ (1,0) [0|255] "bit"  MDC
 SG_ PAS_RandomByte2 : 15|8@0+ (1,0) [0|255] "bit"  MDC
 SG_ PAS_RandomByte3 : 23|8@0+ (1,0) [0|255] "bit"  MDC
 SG_ PAS_RandomByte4 : 31|8@0+ (1,0) [0|255] "bit"  MDC
 SG_ PAS_RandomByte5 : 39|8@0+ (1,0) [0|255] "bit"  MDC
 SG_ PAS_RandomByte6 : 47|8@0+ (1,0) [0|255] "bit"  MDC
 SG_ PAS_RandomByte7 : 55|8@0+ (1,0) [0|255] "bit"  MDC
 SG_ PAS_RandomByte8 : 63|8@0+ (1,0) [0|255] "bit"  MDC
 SG_ PAS_SessionID : 71|8@0+ (1,0) [0|255] "bit"  MDC

BO_ 674 PAS_Response_K2: 12 PAS
 SG_ PAS_Verification_Result : 2|3@0+ (1,0) [0|1] ""  MDC
 SG_ PAS_SessionID : 15|8@0+ (1,0) [0|255] ""  MDC
 SG_ PAS_CMACByte1 : 23|8@0+ (1,0) [0|255] "bit"  MDC
 SG_ PAS_CMACByte2 : 31|8@0+ (1,0) [0|255] "bit"  MDC
 SG_ PAS_CMACByte3 : 39|8@0+ (1,0) [0|255] "bit"  MDC
 SG_ PAS_CMACByte4 : 47|8@0+ (1,0) [0|255] "bit"  MDC
 SG_ PAS_CMACByte5 : 55|8@0+ (1,0) [0|255] "bit"  MDC
 SG_ PAS_CMACByte6 : 63|8@0+ (1,0) [0|255] "bit"  MDC
 SG_ PAS_CMACByte7 : 71|8@0+ (1,0) [0|255] "bit"  MDC
 SG_ PAS_CMACByte8 : 79|8@0+ (1,0) [0|255] "bit"  MDC

BO_ 706 PAS_Key_Learn_Status: 64 PAS
 SG_ PAS_Key_Learn_SubID : 7|8@0+ (1,0) [0|7] ""  MDC
 SG_ PAS_Key_Learn_Numbers : 15|8@0+ (1,0) [1|12] ""  MDC
 SG_ PAS_SKID1 : 23|8@0+ (1,0) [1|12] ""  MDC
 SG_ PAS_SK_Learn_Status1 : 31|8@0+ (1,0) [0|1] ""  MDC
 SG_ PAS_SKID2 : 39|8@0+ (1,0) [1|12] ""  MDC
 SG_ PAS_SK_Learn_Status2 : 47|8@0+ (1,0) [0|1] ""  MDC
 SG_ PAS_SKID3 : 55|8@0+ (1,0) [1|12] ""  MDC
 SG_ PAS_SK_Learn_Status3 : 63|8@0+ (1,0) [0|1] ""  MDC
 SG_ PAS_SKID4 : 71|8@0+ (1,0) [1|12] ""  MDC
 SG_ PAS_SK_Learn_Status4 : 79|8@0+ (1,0) [0|1] ""  MDC
 SG_ PAS_SKID5 : 87|8@0+ (1,0) [1|12] ""  MDC
 SG_ PAS_SK_Learn_Status5 : 95|8@0+ (1,0) [0|1] ""  MDC
 SG_ PAS_SKID6 : 103|8@0+ (1,0) [1|12] ""  MDC
 SG_ PAS_SK_Learn_Status6 : 111|8@0+ (1,0) [0|1] ""  MDC
 SG_ PAS_SKID7 : 119|8@0+ (1,0) [1|12] ""  MDC
 SG_ PAS_SK_Learn_Status7 : 127|8@0+ (1,0) [0|1] ""  MDC
 SG_ PAS_SKID8 : 135|8@0+ (1,0) [1|12] ""  MDC
 SG_ PAS_SK_Learn_Status8 : 143|8@0+ (1,0) [0|1] ""  MDC
 SG_ PAS_SKID9 : 151|8@0+ (1,0) [1|12] ""  MDC
 SG_ PAS_SK_Learn_Status9 : 159|8@0+ (1,0) [0|1] ""  MDC
 SG_ PAS_SKID10 : 167|8@0+ (1,0) [1|12] ""  MDC
 SG_ PAS_SK_Learn_Status10 : 175|8@0+ (1,0) [0|1] ""  MDC
 SG_ PAS_SKID11 : 183|8@0+ (1,0) [1|12] ""  MDC
 SG_ PAS_SK_Learn_Status11 : 191|8@0+ (1,0) [0|1] ""  MDC
 SG_ PAS_SKID12 : 199|8@0+ (1,0) [1|12] ""  MDC
 SG_ PAS_SK_Learn_Status12 : 207|8@0+ (1,0) [0|1] ""  MDC

BO_ 708 PAS_SK_Setting_Status: 64 PAS
 SG_ PASKeyLearnSubIDSettingResponse : 7|8@0+ (1,0) [0|7] ""  MDC
 SG_ PAS_SK_Setting_Response : 15|8@0+ (1,0) [1|12] ""  MDC
 SG_ PAS_SK_Setting_Status : 23|8@0+ (1,0) [0|1] ""  MDC

BO_ 707 PAS_SK_Verify_Result: 64 PAS
 SG_ PAS_VerifySubID : 7|8@0+ (1,0) [0|6] ""  MDC
 SG_ PAS_Verify_SKID : 15|8@0+ (1,0) [1|12] ""  MDC
 SG_ PAS_Verify_AES_Result : 23|32@0+ (1,0) [0|255] ""  MDC
 SG_ PAS_Verify_MACbyte1 : 55|8@0+ (1,0) [0|255] ""  MDC
 SG_ PAS_Verify_MACbyte2 : 63|8@0+ (1,0) [0|255] ""  MDC
 SG_ PAS_Verify_MACbyte3 : 71|8@0+ (1,0) [0|255] ""  MDC
 SG_ PAS_Verify_MACbyte4 : 79|8@0+ (1,0) [0|255] ""  MDC
 SG_ PAS_Verify_MACbyte5 : 87|8@0+ (1,0) [0|255] ""  MDC
 SG_ PAS_Verify_MACbyte6 : 95|8@0+ (1,0) [0|255] ""  MDC
 SG_ PAS_Verify_MACbyte7 : 103|8@0+ (1,0) [0|255] ""  MDC
 SG_ PAS_Verify_MACbyte8 : 111|8@0+ (1,0) [0|255] ""  MDC
 SG_ PAS_Verify_MACbyte9 : 119|8@0+ (1,0) [0|255] ""  MDC
 SG_ PAS_Verify_MACbyte10 : 127|8@0+ (1,0) [0|255] ""  MDC
 SG_ PAS_Verify_MACbyte11 : 135|8@0+ (1,0) [0|255] ""  MDC
 SG_ PAS_Verify_MACbyte12 : 143|8@0+ (1,0) [0|255] ""  MDC
 SG_ PAS_Verify_MACbyte13 : 151|8@0+ (1,0) [0|255] ""  MDC
 SG_ PAS_Verify_MACbyte14 : 159|8@0+ (1,0) [0|255] ""  MDC
 SG_ PAS_Verify_MACbyte15 : 167|8@0+ (1,0) [0|255] ""  MDC
 SG_ PAS_Verify_MACbyte16 : 175|8@0+ (1,0) [0|255] ""  MDC
 SG_ PAS_Verify_IVByte1 : 183|8@0+ (1,0) [0|255] ""  MDC
 SG_ PAS_Verify_IVByte2 : 191|8@0+ (1,0) [0|255] ""  MDC
 SG_ PAS_Verify_IVByte3 : 199|8@0+ (1,0) [0|255] ""  MDC
 SG_ PAS_Verify_IVByte4 : 207|8@0+ (1,0) [0|255] ""  MDC
 SG_ PAS_Verify_IVByte5 : 215|8@0+ (1,0) [0|255] ""  MDC
 SG_ PAS_Verify_IVByte6 : 223|8@0+ (1,0) [0|255] ""  MDC
 SG_ PAS_Verify_IVByte7 : 231|8@0+ (1,0) [0|255] ""  MDC
 SG_ PAS_Verify_IVByte8 : 239|8@0+ (1,0) [0|255] ""  MDC
 SG_ PAS_Verify_IVByte9 : 247|8@0+ (1,0) [0|255] ""  MDC
 SG_ PAS_Verify_IVByte10 : 255|8@0+ (1,0) [0|255] ""  MDC
 SG_ PAS_Verify_IVByte11 : 263|8@0+ (1,0) [0|255] ""  MDC
 SG_ PAS_Verify_IVByte12 : 271|8@0+ (1,0) [0|255] ""  MDC

BO_ 640 UPC_VehiclePosition: 24 PAS
 SG_ UPC_VehiclePosition_X : 7|16@0+ (0.01,-327.68) [-327.68|327.67] "m"  MDC
 SG_ UPC_VehiclePosition_Y : 23|16@0+ (0.01,-327.68) [-327.68|327.67] "m"  MDC
 SG_ UPCVehiclePositionUpdateTime : 39|12@0+ (0.5,0) [0|1000] "ms"  MDC
 SG_ UPC_VehiclePosition_Curvature : 43|17@0+ (6.103515625E-005,-2) [-2|2] "1/m"  MDC
 SG_ UPC_VehiclePosition_YawAngle : 71|16@0+ (0.000244140625,-3.1415926536) [-3.1415926536|3.1415926536] "rad"  MDC
 SG_ UPCVehiclePositionDriveDistance : 87|16@0+ (0.01,-327.68) [-327.68|327.67] "m"  MDC
 SG_ PAS_VehPos_Checksum : 175|8@0+ (1,0) [0|255] "bit"  MDC
 SG_ PAS_VehPos_RollingCounter : 167|4@0+ (1,0) [0|14] "bit"  MDC

BO_ 641 PAS_PSL: 8 PAS
 SG_ PAS_PSL_Status : 2|3@0+ (1,0) [0|7] ""  MDC
 SG_ PAS_PSL_Checksum : 31|8@0+ (1,0) [0|255] "bit"  MDC
 SG_ PAS_PSL_RollingCounter : 23|4@0+ (1,0) [0|14] "bit"  MDC

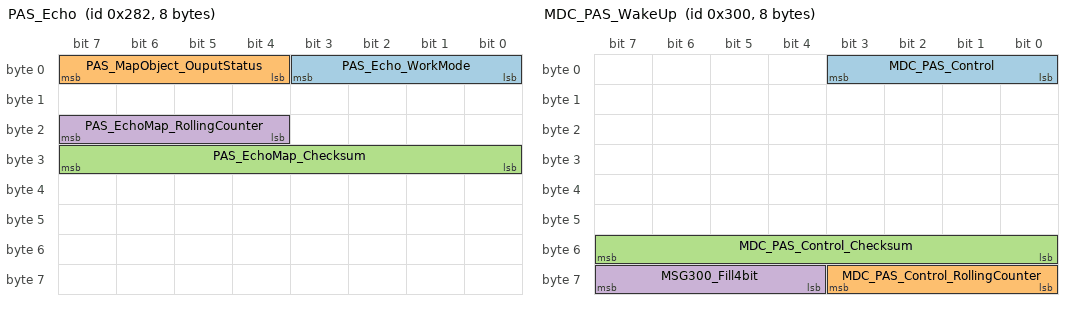
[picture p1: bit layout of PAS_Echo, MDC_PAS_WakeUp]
BO_ 642 PAS_Echo: 8 PAS
 SG_ PAS_Echo_WorkMode : 3|4@0+ (1,0) [0|15] ""  MDC
 SG_ PAS_MapObject_OuputStatus : 7|4@0+ (1,0) [0|15] ""  MDC
 SG_ PAS_EchoMap_Checksum : 31|8@0+ (1,0) [0|255] "bit"  MDC
 SG_ PAS_EchoMap_RollingCounter : 23|4@0+ (1,0) [0|14] "bit"  MDC

BO_ 768 MDC_PAS_WakeUp: 8 MDC
 SG_ MDC_PAS_Control : 3|4@0+ (1,0) [0|3] ""  PAS
 SG_ MDC_PAS_Control_RollingCounter : 59|4@0+ (1,0) [0|15] ""  PAS
 SG_ MDC_PAS_Control_Checksum : 55|8@0+ (1,0) [0|255] "bit"  PAS
 SG_ MSG300_Fill4bit : 63|4@0+ (1,0) [0|15] "bit"  PAS

BO_ 769 MDC_VehStatus: 48 MDC
 SG_ MDC_ESC_VehicleSpeed : 87|14@0+ (0.1,-100) [-100|500] "KPH"  PAS
 SG_ MDC_ESC_VehicleSpeed_Valid : 108|1@0+ (1,0) [0|1] "bit"  PAS
 SG_ MDC_SAS_SteerWheelAngle : 55|16@0+ (0.1,-780) [-780|780] "°"  PAS
 SG_ MDC_SAS_SteerWheelAngle_Valid : 106|1@0+ (1,0) [0|1] "bit"  PAS
 SG_ MDC_BCM_OutTemp : 71|16@0+ (1,-45) [-45|80] "℃"  PAS
 SG_ MDC_BCM_OutTemp_Valid : 107|1@0+ (1,0) [0|1] "bit"  PAS
 SG_ MDC_VCU_GearStatus : 119|4@0+ (1,0) [0|3] "bit"  PAS
 SG_ MDC_VCU_GearStatus_Valid : 120|1@0+ (1,0) [0|1] "bit"  PAS
 SG_ MDC_ESC_FLWheelSpeedRC : 7|12@0+ (1,0) [0|4095] "bit"  PAS
 SG_ MDC_ESC_FLWheelSpeedRC_Valid : 102|1@0+ (1,0) [0|1] "bit"  PAS
 SG_ MDC_ESC_FRWheelSpeedRC : 11|12@0+ (1,0) [0|4095] "bit"  PAS
 SG_ MDC_ESC_FRWheelSpeedRC_Valid : 103|1@0+ (1,0) [0|1] "bit"  PAS
 SG_ MDC_ESC_RLWheelSpeedRC : 31|12@0+ (1,0) [0|4095] "bit"  PAS
 SG_ MDC_ESC_RLWheelSpeedRC_Valid : 104|1@0+ (1,0) [0|1] "bit"  PAS
 SG_ MDC_ESC_RRWheelSpeedRC : 35|12@0+ (1,0) [0|4095] "bit"  PAS
 SG_ MDC_ESC_RRWheelSpeedRC_Valid : 105|1@0+ (1,0) [0|1] "bit"  PAS
 SG_ MDC_ESC_FLWheelDirection : 89|2@0+ (1,0) [0|3] "bit"  PAS
 SG_ MDC_ESC_FLWheelDirection_Valid : 109|1@0+ (1,0) [0|1] "bit"  PAS
 SG_ MDC_ESC_FRWheelDirection : 97|2@0+ (1,0) [0|3] "bit"  PAS
 SG_ MDC_ESC_FRWheelDirection_Valid : 110|1@0+ (1,0) [0|1] "bit"  PAS
 SG_ MDC_ESC_RLWheelDirection : 99|2@0+ (1,0) [0|3] "bit"  PAS
 SG_ MDC_ESC_RLWheelDirection_Valid : 111|1@0+ (1,0) [0|1] "bit"  PAS
 SG_ MDC_ESC_RRWheelDirection : 101|2@0+ (1,0) [0|3] "bit"  PAS
 SG_ MDC_ESC_RRWheelDirection_Valid : 121|1@0+ (1,0) [0|1] "bit"  PAS
 SG_ MDC_VehStatus_RollingCounter : 155|4@0+ (1,0) [0|15] ""  PAS
 SG_ MDC_VehStatus_Checksum : 151|8@0+ (1,0) [0|255] "bit"  PAS
 SG_ YawRate : 135|16@0+ (0.01,-300) [-300|300] "°/s"  PAS
 SG_ YawRateSensor_St : 122|1@0+ (1,0) [0|1] ""  PAS
 SG_ wheelspeedValid : 167|1@0+ (1,0) [0|1] ""  PAS
 SG_ wheelspeedFl : 166|15@0+ (0.01,-100) [-100|100] "m/s"  PAS
 SG_ wheelspeedFr : 182|15@0+ (0.01,-100) [-100|100] "m/s"  PAS
 SG_ wheelspeedRr : 198|15@0+ (0.01,-100) [-100|100] "m/s"  PAS
 SG_ wheelspeedRl : 214|15@0+ (0.01,-100) [-100|100] "m/s"  PAS
 SG_ ecasVehiclePositionState : 226|3@0+ (1,0) [0|7] "bit" PAS
 SG_ ecasVehicleUpDownState : 230|3@0+ (1,0) [0|7] "bit" PAS
 SG_ VehiclePositionStateValid : 227|1@0+ (1,0) [0|1] "bit" PAS
 SG_ VehicleUpDownStateValid : 231|1@0+ (1,0) [0|1] "bit" PAS

BO_ 770 PAS_SonarMode_Req: 12 MDC
 SG_ PAS_Sonar1_Req : 7|2@0+ (1,0) [0|2] ""  PAS
 SG_ PAS_Sonar1_Req_counter : 5|4@0+ (1,0) [0|15] ""  PAS
 SG_ PAS_Sonar2_Req : 1|2@0+ (1,0) [0|2] ""  PAS
 SG_ PAS_Sonar2_Req_counter : 15|4@0+ (1,0) [0|15] ""  PAS
 SG_ PAS_Sonar3_Req : 11|2@0+ (1,0) [0|2] ""  PAS
 SG_ PAS_Sonar3_Req_counter : 9|4@0+ (1,0) [0|15] ""  PAS
 SG_ PAS_Sonar4_Req : 21|2@0+ (1,0) [0|2] ""  PAS
 SG_ PAS_Sonar4_Req_counter : 19|4@0+ (1,0) [0|15] ""  PAS
 SG_ PAS_Sonar7_Req : 31|2@0+ (1,0) [0|2] ""  PAS
 SG_ PAS_Sonar7_Req_counter : 29|4@0+ (1,0) [0|15] ""  PAS
 SG_ PAS_Sonar8_Req : 25|2@0+ (1,0) [0|2] ""  PAS
 SG_ PAS_Sonar8_Req_counter : 39|4@0+ (1,0) [0|15] ""  PAS
 SG_ PAS_Sonar9_Req : 35|2@0+ (1,0) [0|2] ""  PAS
 SG_ PAS_Sonar9_Req_counter : 33|4@0+ (1,0) [0|15] ""  PAS
 SG_ PAS_Sonar10_Req : 45|2@0+ (1,0) [0|2] ""  PAS
 SG_ PAS_Sonar10_Req_counter : 43|4@0+ (1,0) [0|15] ""  PAS
 SG_ PAS_Sonar0_Req : 55|2@0+ (1,0) [0|2] ""  PAS
 SG_ PAS_Sonar0_Req_counter : 53|4@0+ (1,0) [0|15] ""  PAS
 SG_ PAS_Sonar5_Req : 49|2@0+ (1,0) [0|2] ""  PAS
 SG_ PAS_Sonar5_Req_counter : 63|4@0+ (1,0) [0|15] ""  PAS
 SG_ PAS_Sonar6_Req : 59|2@0+ (1,0) [0|2] ""  PAS
 SG_ PAS_Sonar6_Req_counter : 57|4@0+ (1,0) [0|15] ""  PAS
 SG_ PAS_Sonar11_Req : 69|2@0+ (1,0) [0|2] ""  PAS
 SG_ PAS_Sonar11_Req_counter : 67|4@0+ (1,0) [0|15] ""  PAS
 SG_ Sonar_Req_RollingCounter : 91|4@0+ (1,0) [0|15] ""  PAS
 SG_ Sonar_Req_Checksum : 87|8@0+ (1,0) [0|255] "bit"  PAS
 SG_ MSG302_Fill4bit : 95|4@0+ (1,0) [0|15] "bit"  PAS
 SG_ PAS_Function_Req : 74|3@0+ (1,0) [0|7] "bit"  PAS

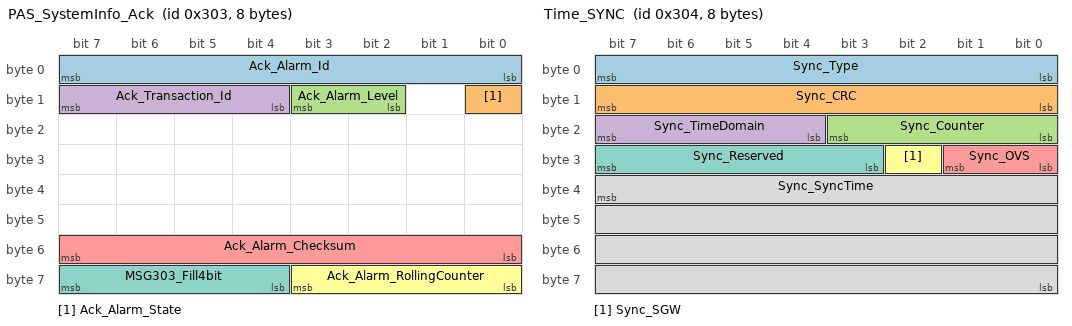
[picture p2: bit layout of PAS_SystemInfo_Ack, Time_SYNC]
BO_ 771 PAS_SystemInfo_Ack: 8 MDC
 SG_ Ack_Alarm_Id : 7|8@0+ (1,0) [0|255] "bit"  PAS
 SG_ Ack_Alarm_State : 8|1@0+ (1,0) [0|1] "bit"  PAS
 SG_ Ack_Alarm_Level : 11|2@0+ (1,0) [0|2] "bit"  PAS
 SG_ Ack_Transaction_Id : 15|4@0+ (1,0) [0|15] "bit"  PAS
 SG_ Ack_Alarm_Checksum : 55|8@0+ (1,0) [0|255] "bit"  PAS
 SG_ Ack_Alarm_RollingCounter : 59|4@0+ (1,0) [0|15] "bit"  PAS
 SG_ MSG303_Fill4bit : 63|4@0+ (1,0) [0|15] "bit"  PAS

BO_ 772 Time_SYNC: 8 MDC
 SG_ Sync_Type : 7|8@0+ (1,0) [0|255] ""  PAS
 SG_ Sync_CRC : 15|8@0+ (1,0) [0|255] ""  PAS
 SG_ Sync_Counter : 19|4@0+ (1,0) [0|15] ""  PAS
 SG_ Sync_TimeDomain : 23|4@0+ (1,0) [0|15] ""  PAS
 SG_ Sync_OVS : 25|2@0+ (1,0) [0|3] ""  PAS
 SG_ Sync_SGW : 26|1@0+ (1,0) [0|1] ""  PAS
 SG_ Sync_Reserved : 31|5@0+ (1,0) [0|31] ""  PAS
 SG_ Sync_SyncTime : 39|32@0+ (1,0) [0|4294967295] ""  PAS

BO_ 928 MDC_Challenge_M1: 12 MDC
 SG_ MDC_RandomByte1 : 7|8@0+ (1,0) [0|255] ""  PAS
 SG_ MDC_RandomByte2 : 15|8@0+ (1,0) [0|255] ""  PAS
 SG_ MDC_RandomByte3 : 23|8@0+ (1,0) [0|255] ""  PAS
 SG_ MDC_RandomByte4 : 31|8@0+ (1,0) [0|255] ""  PAS
 SG_ MDC_RandomByte5 : 39|8@0+ (1,0) [0|255] ""  PAS
 SG_ MDC_RandomByte6 : 47|8@0+ (1,0) [0|255] ""  PAS
 SG_ MDC_RandomByte7 : 55|8@0+ (1,0) [0|255] ""  PAS
 SG_ MDC_RandomByte8 : 63|8@0+ (1,0) [0|255] ""  PAS
 SG_ MDC_SessionID : 71|8@0+ (1,0) [0|255] ""  PAS

BO_ 929 MDC_Response_CMAC_M2: 12 MDC
 SG_ MDC_Response_Result : 2|3@0+ (1,0) [0|1] ""  PAS
 SG_ MDC_Response_SessionID : 15|8@0+ (1,0) [0|255] ""  PAS
 SG_ MDC_Response_CMACByte1 : 23|8@0+ (1,0) [0|255] ""  PAS
 SG_ MDC_Response_CMACByte2 : 31|8@0+ (1,0) [0|255] ""  PAS
 SG_ MDC_Response_CMACByte3 : 39|8@0+ (1,0) [0|255] ""  PAS
 SG_ MDC_Response_CMACByte4 : 47|8@0+ (1,0) [0|255] ""  PAS
 SG_ MDC_Response_CMACByte5 : 55|8@0+ (1,0) [0|255] ""  PAS
 SG_ MDC_Response_CMACByte6 : 63|8@0+ (1,0) [0|255] ""  PAS
 SG_ MDC_Response_CMACByte7 : 71|8@0+ (1,0) [0|255] ""  PAS
 SG_ MDC_Response_CMACByte8 : 79|8@0+ (1,0) [0|255] ""  PAS

BO_ 960 Mdc_KeyLearn_Status: 64 MDC
 SG_ Mdc_KeyLearnSubID : 7|8@0+ (1,0) [0|7] ""  PAS
 SG_ Mdc_KeyLearn_Numbers : 15|8@0+ (1,0) [1|12] ""  PAS
 SG_ Mdc_KeyLearn_SKID1 : 23|8@0+ (1,0) [1|12] ""  PAS
 SG_ Mdc_KeyLearn_SKID2 : 31|8@0+ (1,0) [1|12] ""  PAS
 SG_ Mdc_KeyLearn_SKID3 : 39|8@0+ (1,0) [1|12] ""  PAS
 SG_ Mdc_KeyLearn_SKID4 : 47|8@0+ (1,0) [1|12] ""  PAS
 SG_ Mdc_KeyLearn_SKID5 : 55|8@0+ (1,0) [1|12] ""  PAS
 SG_ Mdc_KeyLearn_SKID6 : 63|8@0+ (1,0) [1|12] ""  PAS
 SG_ Mdc_KeyLearn_SKID7 : 71|8@0+ (1,0) [1|12] ""  PAS
 SG_ Mdc_KeyLearn_SKID8 : 79|8@0+ (1,0) [1|12] ""  PAS
 SG_ Mdc_KeyLearn_SKID9 : 87|8@0+ (1,0) [1|12] ""  PAS
 SG_ Mdc_KeyLearn_SKID10 : 95|8@0+ (1,0) [1|12] ""  PAS
 SG_ Mdc_KeyLearn_SKID11 : 103|8@0+ (1,0) [1|12] ""  PAS
 SG_ Mdc_KeyLearn_SKID12 : 111|8@0+ (1,0) [1|12] ""  PAS

BO_ 962 Mdc_KeyLearn_SendSKCSC: 64 MDC
 SG_ Mdc_KeyLearnSubID_Send : 7|8@0+ (1,0) [0|7] ""  PAS
 SG_ Mdc_KeyLearn_transmit_SKID : 15|8@0+ (1,0) [1|12] ""  PAS
 SG_ Mdc_KeyLearn_update_SKID : 23|8@0+ (1,0) [1|12] ""  PAS
 SG_ Mdc_KeyLearn_SKCByte1 : 31|8@0+ (1,0) [0|255] ""  PAS
 SG_ Mdc_KeyLearn_SKCByte2 : 39|8@0+ (1,0) [0|255] ""  PAS
 SG_ Mdc_KeyLearn_SKCByte3 : 47|8@0+ (1,0) [0|255] ""  PAS
 SG_ Mdc_KeyLearn_SKCByte4 : 55|8@0+ (1,0) [0|255] ""  PAS
 SG_ Mdc_KeyLearn_SKCByte5 : 63|8@0+ (1,0) [0|255] ""  PAS
 SG_ Mdc_KeyLearn_SKCByte6 : 71|8@0+ (1,0) [0|255] ""  PAS
 SG_ Mdc_KeyLearn_SKCByte7 : 79|8@0+ (1,0) [0|255] ""  PAS
 SG_ Mdc_KeyLearn_SKCByte8 : 87|8@0+ (1,0) [0|255] ""  PAS
 SG_ Mdc_KeyLearn_SKCByte9 : 95|8@0+ (1,0) [0|255] ""  PAS
 SG_ Mdc_KeyLearn_SKCByte10 : 103|8@0+ (1,0) [0|255] ""  PAS
 SG_ Mdc_KeyLearn_SKCByte11 : 111|8@0+ (1,0) [0|255] ""  PAS
 SG_ Mdc_KeyLearn_SKCByte12 : 119|8@0+ (1,0) [0|255] ""  PAS
 SG_ Mdc_KeyLearn_SKCByte13 : 127|8@0+ (1,0) [0|255] ""  PAS
 SG_ Mdc_KeyLearn_SKCByte14 : 135|8@0+ (1,0) [0|255] ""  PAS
 SG_ Mdc_KeyLearn_SKCByte15 : 143|8@0+ (1,0) [0|255] ""  PAS
 SG_ Mdc_KeyLearn_SKCByte16 : 151|8@0+ (1,0) [0|255] ""  PAS
 SG_ Mdc_KeyLearn_MACByte1 : 159|8@0+ (1,0) [0|255] ""  PAS
 SG_ Mdc_KeyLearn_MACByte2 : 167|8@0+ (1,0) [0|255] ""  PAS
 SG_ Mdc_KeyLearn_MACByte3 : 175|8@0+ (1,0) [0|255] ""  PAS
 SG_ Mdc_KeyLearn_MACByte4 : 183|8@0+ (1,0) [0|255] ""  PAS
 SG_ Mdc_KeyLearn_MACByte5 : 191|8@0+ (1,0) [0|255] ""  PAS
 SG_ Mdc_KeyLearn_MACByte6 : 199|8@0+ (1,0) [0|255] ""  PAS
 SG_ Mdc_KeyLearn_MACByte7 : 207|8@0+ (1,0) [0|255] ""  PAS
 SG_ Mdc_KeyLearn_MACByte8 : 215|8@0+ (1,0) [0|255] ""  PAS
 SG_ Mdc_KeyLearn_MACByte9 : 223|8@0+ (1,0) [0|255] ""  PAS
 SG_ Mdc_KeyLearn_MACByte10 : 231|8@0+ (1,0) [0|255] ""  PAS
 SG_ Mdc_KeyLearn_MACByte11 : 239|8@0+ (1,0) [0|255] ""  PAS
 SG_ Mdc_KeyLearn_MACByte12 : 247|8@0+ (1,0) [0|255] ""  PAS
 SG_ Mdc_KeyLearn_MACByte13 : 255|8@0+ (1,0) [0|255] ""  PAS
 SG_ Mdc_KeyLearn_MACByte14 : 263|8@0+ (1,0) [0|255] ""  PAS
 SG_ Mdc_KeyLearn_MACByte15 : 271|8@0+ (1,0) [0|255] ""  PAS
 SG_ Mdc_KeyLearn_MACByte16 : 279|8@0+ (1,0) [0|255] ""  PAS
 SG_ Mdc_KeyLearn_IVByte1 : 287|8@0+ (1,0) [0|255] ""  PAS
 SG_ Mdc_KeyLearn_IVByte2 : 295|8@0+ (1,0) [0|255] ""  PAS
 SG_ Mdc_KeyLearn_IVByte3 : 303|8@0+ (1,0) [0|255] ""  PAS
 SG_ Mdc_KeyLearn_IVByte4 : 311|8@0+ (1,0) [0|255] ""  PAS
 SG_ Mdc_KeyLearn_IVByte5 : 319|8@0+ (1,0) [0|255] ""  PAS
 SG_ Mdc_KeyLearn_IVByte6 : 327|8@0+ (1,0) [0|255] ""  PAS
 SG_ Mdc_KeyLearn_IVByte7 : 335|8@0+ (1,0) [0|255] ""  PAS
 SG_ Mdc_KeyLearn_IVByte8 : 343|8@0+ (1,0) [0|255] ""  PAS
 SG_ Mdc_KeyLearn_IVByte9 : 351|8@0+ (1,0) [0|255] ""  PAS
 SG_ Mdc_KeyLearn_IVByte10 : 359|8@0+ (1,0) [0|255] ""  PAS
 SG_ Mdc_KeyLearn_IVByte11 : 367|8@0+ (1,0) [0|255] ""  PAS
 SG_ Mdc_KeyLearn_IVByte12 : 375|8@0+ (1,0) [0|255] ""  PAS
 SG_ Mdc_KeyLearn_SC : 383|24@0+ (1,0) [0|16777215] ""  PAS

BO_ 963 Mdc_KeyLearn_SKSetting: 64 MDC
 SG_ Mdc_KeyLearnSubID_SKSetting : 7|8@0+ (1,0) [0|7] ""  PAS
 SG_ Mdc_KeyLearn_SKID : 15|8@0+ (1,0) [1|12] ""  PAS

BO_ 964 Mdc_KeyLearn_Clean: 64 MDC
 SG_ Mdc_KeyLearnSubID_CleanID : 7|8@0+ (1,0) [0|7] ""  PAS
 SG_ Mdc_KeyLearn_Clean_SKID : 15|8@0+ (1,0) [1|12] ""  PAS
 SG_ Mdc_KeyLearn_Clean_SCByte1 : 23|8@0+ (1,0) [0|255] ""  PAS
 SG_ Mdc_KeyLearn_Clean_SCByte2 : 31|8@0+ (1,0) [0|255] ""  PAS
 SG_ Mdc_KeyLearn_Clean_SCByte3 : 39|8@0+ (1,0) [0|255] ""  PAS
 SG_ Mdc_KeyLearn_Clean_SCByte4 : 47|8@0+ (1,0) [0|255] ""  PAS
 SG_ Mdc_KeyLearn_Clean_SCByte5 : 55|8@0+ (1,0) [0|255] ""  PAS
 SG_ Mdc_KeyLearn_Clean_SCByte6 : 63|8@0+ (1,0) [0|255] ""  PAS
 SG_ Mdc_KeyLearn_Clean_SCByte7 : 71|8@0+ (1,0) [0|255] ""  PAS
 SG_ Mdc_KeyLearn_Clean_SCByte8 : 79|8@0+ (1,0) [0|255] ""  PAS
 SG_ Mdc_KeyLearn_Clean_SCByte9 : 87|8@0+ (1,0) [0|255] ""  PAS
 SG_ Mdc_KeyLearn_Clean_SCByte10 : 95|8@0+ (1,0) [0|255] ""  PAS
 SG_ Mdc_KeyLearn_Clean_SCByte11 : 103|8@0+ (1,0) [0|255] ""  PAS
 SG_ Mdc_KeyLearn_Clean_SCByte12 : 111|8@0+ (1,0) [0|255] ""  PAS
 SG_ Mdc_KeyLearn_Clean_SCByte13 : 119|8@0+ (1,0) [0|255] ""  PAS
 SG_ Mdc_KeyLearn_Clean_SCByte14 : 127|8@0+ (1,0) [0|255] ""  PAS
 SG_ Mdc_KeyLearn_Clean_SCByte15 : 135|8@0+ (1,0) [0|255] ""  PAS
 SG_ Mdc_KeyLearn_Clean_SCByte16 : 143|8@0+ (1,0) [0|255] ""  PAS
 SG_ Mdc_KeyLearn_Clean_MACByte1 : 151|8@0+ (1,0) [0|255] ""  PAS
 SG_ Mdc_KeyLearn_Clean_MACByte2 : 159|8@0+ (1,0) [0|255] ""  PAS
 SG_ Mdc_KeyLearn_Clean_MACByte3 : 167|8@0+ (1,0) [0|255] ""  PAS
 SG_ Mdc_KeyLearn_Clean_MACByte4 : 175|8@0+ (1,0) [0|255] ""  PAS
 SG_ Mdc_KeyLearn_Clean_MACByte5 : 183|8@0+ (1,0) [0|255] ""  PAS
 SG_ Mdc_KeyLearn_Clean_MACByte6 : 191|8@0+ (1,0) [0|255] ""  PAS
 SG_ Mdc_KeyLearn_Clean_MACByte7 : 199|8@0+ (1,0) [0|255] ""  PAS
 SG_ Mdc_KeyLearn_Clean_MACByte8 : 207|8@0+ (1,0) [0|255] ""  PAS
 SG_ Mdc_KeyLearn_Clean_MACByte9 : 215|8@0+ (1,0) [0|255] ""  PAS
 SG_ Mdc_KeyLearn_Clean_MACByte10 : 223|8@0+ (1,0) [0|255] ""  PAS
 SG_ Mdc_KeyLearn_Clean_MACByte11 : 231|8@0+ (1,0) [0|255] ""  PAS
 SG_ Mdc_KeyLearn_Clean_MACByte12 : 239|8@0+ (1,0) [0|255] ""  PAS
 SG_ Mdc_KeyLearn_Clean_MACByte13 : 247|8@0+ (1,0) [0|255] ""  PAS
 SG_ Mdc_KeyLearn_Clean_MACByte14 : 255|8@0+ (1,0) [0|255] ""  PAS
 SG_ Mdc_KeyLearn_Clean_MACByte15 : 263|8@0+ (1,0) [0|255] ""  PAS
 SG_ Mdc_KeyLearn_Clean_MACByte16 : 271|8@0+ (1,0) [0|255] ""  PAS
 SG_ Mdc_KeyLearn_Clean_IVByte1 : 279|8@0+ (1,0) [0|255] ""  PAS
 SG_ Mdc_KeyLearn_Clean_IVByte2 : 287|8@0+ (1,0) [0|255] ""  PAS
 SG_ Mdc_KeyLearn_Clean_IVByte3 : 295|8@0+ (1,0) [0|255] ""  PAS
 SG_ Mdc_KeyLearn_Clean_IVByte4 : 303|8@0+ (1,0) [0|255] ""  PAS
 SG_ Mdc_KeyLearn_Clean_IVByte5 : 311|8@0+ (1,0) [0|255] ""  PAS
 SG_ Mdc_KeyLearn_Clean_IVByte6 : 319|8@0+ (1,0) [0|255] ""  PAS
 SG_ Mdc_KeyLearn_Clean_IVByte7 : 327|8@0+ (1,0) [0|255] ""  PAS
 SG_ Mdc_KeyLearn_Clean_IVByte8 : 335|8@0+ (1,0) [0|255] ""  PAS
 SG_ Mdc_KeyLearn_Clean_IVByte9 : 343|8@0+ (1,0) [0|255] ""  PAS
 SG_ Mdc_KeyLearn_Clean_IVByte10 : 351|8@0+ (1,0) [0|255] ""  PAS
 SG_ Mdc_KeyLearn_Clean_IVByte11 : 359|8@0+ (1,0) [0|255] ""  PAS
 SG_ Mdc_KeyLearn_Clean_IVByte12 : 367|8@0+ (1,0) [0|255] ""  PAS

BO_ 961 Mdc_Verify_Random: 64 MDC
 SG_ Mdc_VerifySubID_Random : 7|8@0+ (1,0) [0|2] ""  PAS
 SG_ Mdc_Verify_SKID : 15|8@0+ (1,0) [1|12] ""  PAS
 SG_ Mdc_Verify_Random : 23|32@0+ (1,0) [0|4294967295] ""  PAS

BO_ 965 Mdc_Verify_Result: 64 MDC
 SG_ Mdc_Verify_ResultID : 7|8@0+ (1,0) [0|2] ""  PAS
 SG_ Mdc_Verify_Result_SKID : 15|8@0+ (1,0) [1|12] ""  PAS
 SG_ Mdc_Verify_Result_Status : 23|8@0+ (1,0) [0|1] ""  PAS

BO_ 656 PDC_Priv_0_6_Point: 64 PAS
 SG_ Point_Priv_0_6_Timestamp : 455|12@0+ (0.5,0) [0|1000] "ms"  MDC
 SG_ Point_00_ID : 7|8@0+ (1,0) [0|255] ""  MDC
 SG_ Point_00_Valid : 456|1@0+ (1,0) [0|1] ""  MDC
 SG_ Point_00_X : 15|12@0+ (1,-2000) [-2000|2000] "cm"  MDC
 SG_ Point_00_Y : 19|12@0+ (1,-2000) [-2000|2000] "cm"  MDC
 SG_ Point_00_ErrorA : 39|8@0+ (1,0) [0|254] "cm"  MDC
 SG_ Point_00_ErrorB : 47|8@0+ (1,0) [0|254] "cm"  MDC
 SG_ Point_00_ErrorTheta : 55|8@0+ (1.412,-180) [-180|180] "°"  MDC
 SG_ Point_00_High : 479|2@0+ (1,0) [0|1] ""  MDC
 SG_ Point_00_ExistProbability : 63|7@0+ (1,0) [0|100] "%"  MDC
 SG_ Point_01_ID : 71|8@0+ (1,0) [0|255] ""  MDC
 SG_ Point_01_Valid : 457|1@0+ (1,0) [0|1] ""  MDC
 SG_ Point_01_X : 79|12@0+ (1,-2000) [-2000|2000] "cm"  MDC
 SG_ Point_01_Y : 83|12@0+ (1,-2000) [-2000|2000] "cm"  MDC
 SG_ Point_01_ErrorA : 103|8@0+ (1,0) [0|254] "cm"  MDC
 SG_ Point_01_ErrorB : 111|8@0+ (1,0) [0|254] "cm"  MDC
 SG_ Point_01_ErrorTheta : 119|8@0+ (1.412,-180) [-180|180] "°"  MDC
 SG_ Point_01_High : 477|2@0+ (1,0) [0|1] ""  MDC
 SG_ Point_01_ExistProbability : 127|7@0+ (1,0) [0|100] "%"  MDC
 SG_ Point_02_ID : 135|8@0+ (1,0) [0|255] ""  MDC
 SG_ Point_02_Valid : 458|1@0+ (1,0) [0|1] ""  MDC
 SG_ Point_02_X : 143|12@0+ (1,-2000) [-2000|2000] "cm"  MDC
 SG_ Point_02_Y : 147|12@0+ (1,-2000) [-2000|2000] "cm"  MDC
 SG_ Point_02_ErrorA : 167|8@0+ (1,0) [0|254] "cm"  MDC
 SG_ Point_02_ErrorB : 175|8@0+ (1,0) [0|254] "cm"  MDC
 SG_ Point_02_ErrorTheta : 183|8@0+ (1.412,-180) [-180|180] "°"  MDC
 SG_ Point_02_High : 475|2@0+ (1,0) [0|1] ""  MDC
 SG_ Point_02_ExistProbability : 191|7@0+ (1,0) [0|100] "%"  MDC
 SG_ Point_03_ID : 199|8@0+ (1,0) [0|255] ""  MDC
 SG_ Point_03_Valid : 459|1@0+ (1,0) [0|1] ""  MDC
 SG_ Point_03_X : 207|12@0+ (1,-2000) [-2000|2000] "cm"  MDC
 SG_ Point_03_Y : 211|12@0+ (1,-2000) [-2000|2000] "cm"  MDC
 SG_ Point_03_ErrorA : 231|8@0+ (1,0) [0|254] "cm"  MDC
 SG_ Point_03_ErrorB : 239|8@0+ (1,0) [0|254] "cm"  MDC
 SG_ Point_03_ErrorTheta : 247|8@0+ (1.412,-180) [-180|180] "°"  MDC
 SG_ Point_03_High : 473|2@0+ (1,0) [0|1] ""  MDC
 SG_ Point_03_ExistProbability : 255|7@0+ (1,0) [0|100] "%"  MDC
 SG_ Point_04_ID : 263|8@0+ (1,0) [0|255] ""  MDC
 SG_ Point_04_Valid : 469|1@0+ (1,0) [0|1] ""  MDC
 SG_ Point_04_X : 271|12@0+ (1,-2000) [-2000|2000] "cm"  MDC
 SG_ Point_04_Y : 275|12@0+ (1,-2000) [-2000|2000] "cm"  MDC
 SG_ Point_04_ErrorA : 295|8@0+ (1,0) [0|254] "cm"  MDC
 SG_ Point_04_ErrorB : 303|8@0+ (1,0) [0|254] "cm"  MDC
 SG_ Point_04_ErrorTheta : 311|8@0+ (1.412,-180) [-180|180] "°"  MDC
 SG_ Point_04_High : 487|2@0+ (1,0) [0|1] ""  MDC
 SG_ Point_04_ExistProbability : 319|7@0+ (1,0) [0|100] "%"  MDC
 SG_ Point_05_ID : 327|8@0+ (1,0) [0|255] ""  MDC
 SG_ Point_05_Valid : 470|1@0+ (1,0) [0|1] ""  MDC
 SG_ Point_05_X : 335|12@0+ (1,-2000) [-2000|2000] "cm"  MDC
 SG_ Point_05_Y : 339|12@0+ (1,-2000) [-2000|2000] "cm"  MDC
 SG_ Point_05_ErrorA : 359|8@0+ (1,0) [0|254] "cm"  MDC
 SG_ Point_05_ErrorB : 367|8@0+ (1,0) [0|254] "cm"  MDC
 SG_ Point_05_ErrorTheta : 375|8@0+ (1.412,-180) [-180|180] "°"  MDC
 SG_ Point_05_High : 485|2@0+ (1,0) [0|1] ""  MDC
 SG_ Point_05_ExistProbability : 383|7@0+ (1,0) [0|100] "%"  MDC
 SG_ Point_06_ID : 391|8@0+ (1,0) [0|255] ""  MDC
 SG_ Point_06_Valid : 471|1@0+ (1,0) [0|1] ""  MDC
 SG_ Point_06_X : 399|12@0+ (1,-2000) [-2000|2000] "cm"  MDC
 SG_ Point_06_Y : 403|12@0+ (1,-2000) [-2000|2000] "cm"  MDC
 SG_ Point_06_ErrorA : 423|8@0+ (1,0) [0|254] "cm"  MDC
 SG_ Point_06_ErrorB : 431|8@0+ (1,0) [0|254] "cm"  MDC
 SG_ Point_06_ErrorTheta : 439|8@0+ (1.412,-180) [-180|180] "°"  MDC
 SG_ Point_06_High : 483|2@0+ (1,0) [0|1] ""  MDC
 SG_ Point_06_ExistProbability : 447|7@0+ (1,0) [0|100] "%"  MDC

BO_ 657 PDC_Priv_7_13_Point: 64 PAS
 SG_ Point_Priv_7_13_Timestamp : 455|12@0+ (0.5,0) [0|1000] "ms"  MDC
 SG_ Point_07_ID : 7|8@0+ (1,0) [0|255] ""  MDC
 SG_ Point_07_Valid : 456|1@0+ (1,0) [0|1] ""  MDC
 SG_ Point_07_X : 15|12@0+ (1,-2000) [-2000|2000] "cm"  MDC
 SG_ Point_07_Y : 19|12@0+ (1,-2000) [-2000|2000] "cm"  MDC
 SG_ Point_07_ErrorA : 39|8@0+ (1,0) [0|254] "cm"  MDC
 SG_ Point_07_ErrorB : 47|8@0+ (1,0) [0|254] "cm"  MDC
 SG_ Point_07_ErrorTheta : 55|8@0+ (1.412,-180) [-180|180] "°"  MDC
 SG_ Point_07_High : 479|2@0+ (1,0) [0|1] ""  MDC
 SG_ Point_07_ExistProbability : 63|7@0+ (1,0) [0|100] "%"  MDC
 SG_ Point_08_ID : 71|8@0+ (1,0) [0|255] ""  MDC
 SG_ Point_08_Valid : 457|1@0+ (1,0) [0|1] ""  MDC
 SG_ Point_08_X : 79|12@0+ (1,-2000) [-2000|2000] "cm"  MDC
 SG_ Point_08_Y : 83|12@0+ (1,-2000) [-2000|2000] "cm"  MDC
 SG_ Point_08_ErrorA : 103|8@0+ (1,0) [0|254] "cm"  MDC
 SG_ Point_08_ErrorB : 111|8@0+ (1,0) [0|254] "cm"  MDC
 SG_ Point_08_ErrorTheta : 119|8@0+ (1.412,-180) [-180|180] "°"  MDC
 SG_ Point_08_High : 477|2@0+ (1,0) [0|1] ""  MDC
 SG_ Point_08_ExistProbability : 127|7@0+ (1,0) [0|100] "%"  MDC
 SG_ Point_09_ID : 135|8@0+ (1,0) [0|255] ""  MDC
 SG_ Point_09_Valid : 458|1@0+ (1,0) [0|1] ""  MDC
 SG_ Point_09_X : 143|12@0+ (1,-2000) [-2000|2000] "cm"  MDC
 SG_ Point_09_Y : 147|12@0+ (1,-2000) [-2000|2000] "cm"  MDC
 SG_ Point_09_ErrorA : 167|8@0+ (1,0) [0|254] "cm"  MDC
 SG_ Point_09_ErrorB : 175|8@0+ (1,0) [0|254] "cm"  MDC
 SG_ Point_09_ErrorTheta : 183|8@0+ (1.412,-180) [-180|180] "°"  MDC
 SG_ Point_09_High : 475|2@0+ (1,0) [0|1] ""  MDC
 SG_ Point_09_ExistProbability : 191|7@0+ (1,0) [0|100] "%"  MDC
 SG_ Point_10_ID : 199|8@0+ (1,0) [0|255] ""  MDC
 SG_ Point_10_Valid : 459|1@0+ (1,0) [0|1] ""  MDC
 SG_ Point_10_X : 207|12@0+ (1,-2000) [-2000|2000] "cm"  MDC
 SG_ Point_10_Y : 211|12@0+ (1,-2000) [-2000|2000] "cm"  MDC
 SG_ Point_10_ErrorA : 231|8@0+ (1,0) [0|254] "cm"  MDC
 SG_ Point_10_ErrorB : 239|8@0+ (1,0) [0|254] "cm"  MDC
 SG_ Point_10_ErrorTheta : 247|8@0+ (1.412,-180) [-180|180] "°"  MDC
 SG_ Point_10_High : 473|2@0+ (1,0) [0|1] ""  MDC
 SG_ Point_10_ExistProbability : 255|7@0+ (1,0) [0|100] "%"  MDC
 SG_ Point_11_ID : 263|8@0+ (1,0) [0|255] ""  MDC
 SG_ Point_11_Valid : 469|1@0+ (1,0) [0|1] ""  MDC
 SG_ Point_11_X : 271|12@0+ (1,-2000) [-2000|2000] "cm"  MDC
 SG_ Point_11_Y : 275|12@0+ (1,-2000) [-2000|2000] "cm"  MDC
 SG_ Point_11_ErrorA : 295|8@0+ (1,0) [0|254] "cm"  MDC
 SG_ Point_11_ErrorB : 303|8@0+ (1,0) [0|254] "cm"  MDC
 SG_ Point_11_ErrorTheta : 311|8@0+ (1.412,-180) [-180|180] "°"  MDC
 SG_ Point_11_High : 487|2@0+ (1,0) [0|1] ""  MDC
 SG_ Point_11_ExistProbability : 319|7@0+ (1,0) [0|100] "%"  MDC
 SG_ Point_12_ID : 327|8@0+ (1,0) [0|255] ""  MDC
 SG_ Point_12_Valid : 470|1@0+ (1,0) [0|1] ""  MDC
 SG_ Point_12_X : 335|12@0+ (1,-2000) [-2000|2000] "cm"  MDC
 SG_ Point_12_Y : 339|12@0+ (1,-2000) [-2000|2000] "cm"  MDC
 SG_ Point_12_ErrorA : 359|8@0+ (1,0) [0|254] "cm"  MDC
 SG_ Point_12_ErrorB : 367|8@0+ (1,0) [0|254] "cm"  MDC
 SG_ Point_12_ErrorTheta : 375|8@0+ (1.412,-180) [-180|180] "°"  MDC
 SG_ Point_12_High : 485|2@0+ (1,0) [0|1] ""  MDC
 SG_ Point_12_ExistProbability : 383|7@0+ (1,0) [0|100] "%"  MDC
 SG_ Point_13_ID : 391|8@0+ (1,0) [0|255] ""  MDC
 SG_ Point_13_Valid : 471|1@0+ (1,0) [0|1] ""  MDC
 SG_ Point_13_X : 399|12@0+ (1,-2000) [-2000|2000] "cm"  MDC
 SG_ Point_13_Y : 403|12@0+ (1,-2000) [-2000|2000] "cm"  MDC
 SG_ Point_13_ErrorA : 423|8@0+ (1,0) [0|254] "cm"  MDC
 SG_ Point_13_ErrorB : 431|8@0+ (1,0) [0|254] "cm"  MDC
 SG_ Point_13_ErrorTheta : 439|8@0+ (1.412,-180) [-180|180] "°"  MDC
 SG_ Point_13_High : 483|2@0+ (1,0) [0|1] ""  MDC
 SG_ Point_13_ExistProbability : 447|7@0+ (1,0) [0|100] "%"  MDC

BO_ 658 PDC_Priv_14_20_Point: 64 PAS
 SG_ Point_Priv_14_20_Timestamp : 455|12@0+ (0.5,0) [0|1000] "ms"  MDC
 SG_ Point_14_ID : 7|8@0+ (1,0) [0|255] ""  MDC
 SG_ Point_14_Valid : 456|1@0+ (1,0) [0|1] ""  MDC
 SG_ Point_14_X : 15|12@0+ (1,-2000) [-2000|2000] "cm"  MDC
 SG_ Point_14_Y : 19|12@0+ (1,-2000) [-2000|2000] "cm"  MDC
 SG_ Point_14_ErrorA : 39|8@0+ (1,0) [0|254] "cm"  MDC
 SG_ Point_14_ErrorB : 47|8@0+ (1,0) [0|254] "cm"  MDC
 SG_ Point_14_ErrorTheta : 55|8@0+ (1.412,-180) [-180|180] "°"  MDC
 SG_ Point_14_High : 479|2@0+ (1,0) [0|1] ""  MDC
 SG_ Point_14_ExistProbability : 63|7@0+ (1,0) [0|100] "%"  MDC
 SG_ Point_15_ID : 71|8@0+ (1,0) [0|255] ""  MDC
 SG_ Point_15_Valid : 457|1@0+ (1,0) [0|1] ""  MDC
 SG_ Point_15_X : 79|12@0+ (1,-2000) [-2000|2000] "cm"  MDC
 SG_ Point_15_Y : 83|12@0+ (1,-2000) [-2000|2000] "cm"  MDC
 SG_ Point_15_ErrorA : 103|8@0+ (1,0) [0|254] "cm"  MDC
 SG_ Point_15_ErrorB : 111|8@0+ (1,0) [0|254] "cm"  MDC
 SG_ Point_15_ErrorTheta : 119|8@0+ (1.412,-180) [-180|180] "°"  MDC
 SG_ Point_15_High : 477|2@0+ (1,0) [0|1] ""  MDC
 SG_ Point_15_ExistProbability : 127|7@0+ (1,0) [0|100] "%"  MDC
 SG_ Point_16_ID : 135|8@0+ (1,0) [0|255] ""  MDC
 SG_ Point_16_Valid : 458|1@0+ (1,0) [0|1] ""  MDC
 SG_ Point_16_X : 143|12@0+ (1,-2000) [-2000|2000] "cm"  MDC
 SG_ Point_16_Y : 147|12@0+ (1,-2000) [-2000|2000] "cm"  MDC
 SG_ Point_16_ErrorA : 167|8@0+ (1,0) [0|254] "cm"  MDC
 SG_ Point_16_ErrorB : 175|8@0+ (1,0) [0|254] "cm"  MDC
 SG_ Point_16_ErrorTheta : 183|8@0+ (1.412,-180) [-180|180] "°"  MDC
 SG_ Point_16_High : 475|2@0+ (1,0) [0|1] ""  MDC
 SG_ Point_16_ExistProbability : 191|7@0+ (1,0) [0|100] "%"  MDC
 SG_ Point_17_ID : 199|8@0+ (1,0) [0|255] ""  MDC
 SG_ Point_17_Valid : 459|1@0+ (1,0) [0|1] ""  MDC
 SG_ Point_17_X : 207|12@0+ (1,-2000) [-2000|2000] "cm"  MDC
 SG_ Point_17_Y : 211|12@0+ (1,-2000) [-2000|2000] "cm"  MDC
 SG_ Point_17_ErrorA : 231|8@0+ (1,0) [0|254] "cm"  MDC
 SG_ Point_17_ErrorB : 239|8@0+ (1,0) [0|254] "cm"  MDC
 SG_ Point_17_ErrorTheta : 247|8@0+ (1.412,-180) [-180|180] "°"  MDC
 SG_ Point_17_High : 473|2@0+ (1,0) [0|1] ""  MDC
 SG_ Point_17_ExistProbability : 255|7@0+ (1,0) [0|100] "%"  MDC
 SG_ Point_18_ID : 263|8@0+ (1,0) [0|255] ""  MDC
 SG_ Point_18_Valid : 469|1@0+ (1,0) [0|1] ""  MDC
 SG_ Point_18_X : 271|12@0+ (1,-2000) [-2000|2000] "cm"  MDC
 SG_ Point_18_Y : 275|12@0+ (1,-2000) [-2000|2000] "cm"  MDC
 SG_ Point_18_ErrorA : 295|8@0+ (1,0) [0|254] "cm"  MDC
 SG_ Point_18_ErrorB : 303|8@0+ (1,0) [0|254] "cm"  MDC
 SG_ Point_18_ErrorTheta : 311|8@0+ (1.412,-180) [-180|180] "°"  MDC
 SG_ Point_18_High : 487|2@0+ (1,0) [0|1] ""  MDC
 SG_ Point_18_ExistProbability : 319|7@0+ (1,0) [0|100] "%"  MDC
 SG_ Point_19_ID : 327|8@0+ (1,0) [0|255] ""  MDC
 SG_ Point_19_Valid : 470|1@0+ (1,0) [0|1] ""  MDC
 SG_ Point_19_X : 335|12@0+ (1,-2000) [-2000|2000] "cm"  MDC
 SG_ Point_19_Y : 339|12@0+ (1,-2000) [-2000|2000] "cm"  MDC
 SG_ Point_19_ErrorA : 359|8@0+ (1,0) [0|254] "cm"  MDC
 SG_ Point_19_ErrorB : 367|8@0+ (1,0) [0|254] "cm"  MDC
 SG_ Point_19_ErrorTheta : 375|8@0+ (1.412,-180) [-180|180] "°"  MDC
 SG_ Point_19_High : 485|2@0+ (1,0) [0|1] ""  MDC
 SG_ Point_19_ExistProbability : 383|7@0+ (1,0) [0|100] "%"  MDC
 SG_ Point_20_ID : 391|8@0+ (1,0) [0|255] ""  MDC
 SG_ Point_20_Valid : 471|1@0+ (1,0) [0|1] ""  MDC
 SG_ Point_20_X : 399|12@0+ (1,-2000) [-2000|2000] "cm"  MDC
 SG_ Point_20_Y : 403|12@0+ (1,-2000) [-2000|2000] "cm"  MDC
 SG_ Point_20_ErrorA : 423|8@0+ (1,0) [0|254] "cm"  MDC
 SG_ Point_20_ErrorB : 431|8@0+ (1,0) [0|254] "cm"  MDC
 SG_ Point_20_ErrorTheta : 439|8@0+ (1.412,-180) [-180|180] "°"  MDC
 SG_ Point_20_High : 483|2@0+ (1,0) [0|1] ""  MDC
 SG_ Point_20_ExistProbability : 447|7@0+ (1,0) [0|100] "%"  MDC

CM_ SG_ 773 sensorVersion "sensor version";
CM_ SG_ 513 PAS_sonar1_DISTANCE "距离";
CM_ SG_ 513 PASsonar1DISTANCETime "1号雷达发波时间戳";
CM_ SG_ 513 PAS_sonar1_Blind "盲区";
CM_ SG_ 513 PAS_sonar1_crossDistanceLeft "1号雷达发、0号雷达收的间接回波的距离";
CM_ SG_ 513 PAS_sonar1_crossDistanceRight "1号雷达发、2号雷达收的间接回波的距离";
CM_ SG_ 513 PASsonar1crossDistanceLeftTime "1号雷达发、0号雷达收的间接回波的距离时间戳——发波时间戳";
CM_ SG_ 513 PASsonar1crossDistanceRightTime "1号雷达发、2号雷达收的间接回波的距离时间戳——发波时间戳";
CM_ SG_ 513 PAS_sonar1_confidence "置信度";
CM_ SG_ 513 Msg201_PAS_sonar1_Counter "探头发波计数器";
CM_ SG_ 513 PAS_sonar2_DISTANCE "距离";
CM_ SG_ 513 PASsonar2DISTANCETime "2号雷达收到直接回波的时间戳发波时间戳";
CM_ SG_ 513 PAS_sonar2_Blind "盲区";
CM_ SG_ 513 PAS_sonar2_crossDistanceLeft "2号雷达发、1号雷达收的间接回波的距离";
CM_ SG_ 513 PAS_sonar2_crossDistanceRight "2号雷达发、3号雷达收的间接回波的距离";
CM_ SG_ 513 PASsonar2crossDistanceLeftTime "2号雷达发、1号雷达收的间接回波的距离时间戳——发波时间戳";
CM_ SG_ 513 PASsonar2crossDistanceRightTime "2号雷达发、3号雷达收的间接回波的距离时间戳——发波时间戳";
CM_ SG_ 513 PAS_sonar2_confidence "置信度";
CM_ SG_ 513 Msg201_PAS_sonar2_Counter "探头发波计数器";
CM_ SG_ 513 PAS_sonar3_DISTANCE "距离";
CM_ SG_ 513 PASsonar3DISTANCETime "3号雷达收到直接回波的时间戳——发波时间戳";
CM_ SG_ 513 PAS_sonar3_Blind "盲区";
CM_ SG_ 513 PAS_sonar3_crossDistanceLeft "3号雷达发、2号雷达收的间接回波的距离";
CM_ SG_ 513 PAS_sonar3_crossDistanceRight "3号雷达发、4号雷达收的间接回波的距离";
CM_ SG_ 513 PASsonar3crossDistanceLeftTime "3号雷达发、2号雷达收的间接回波的距离时间戳——发波时间戳";
CM_ SG_ 513 PASsonar3crossDistanceRightTime "3号雷达发、4号雷达收的间接回波的距离时间戳——发波时间戳";
CM_ SG_ 513 PAS_sonar3_confidence "置信度";
CM_ SG_ 513 Msg201_PAS_sonar3_Counter "探头发波计数器";
CM_ SG_ 513 PAS_sonar4_DISTANCE "距离";
CM_ SG_ 513 PASsonar4DISTANCETime "4号雷达收到直接回波的时间戳——发波时间戳";
CM_ SG_ 513 PAS_sonar4_Blind "盲区";
CM_ SG_ 513 PAS_sonar4_crossDistanceLeft "4号雷达发、3号雷达收的间接回波的距离";
CM_ SG_ 513 PAS_sonar4_crossDistanceRight "4号雷达发、5号雷达收的间接回波的距离";
CM_ SG_ 513 PASsonar4crossDistanceLeftTime "4号雷达发、3号雷达收的间接回波的距离时间戳——发波时间戳";
CM_ SG_ 513 PASsonar4crossDistanceRightTime "4号雷达发、5号雷达收的间接回波的距离时间戳——发波时间戳";
CM_ SG_ 513 PAS_sonar4_confidence "置信度";
CM_ SG_ 513 Msg201_PAS_sonar4_Counter "探头发波计数器";
CM_ SG_ 513 PAS_sonar0_DISTANCE "距离";
CM_ SG_ 513 PASsonar0DISTANCETime "0号雷达收到直接回波的时间戳——发波时间戳";
CM_ SG_ 513 PAS_sonar0_Blind "盲区";
CM_ SG_ 513 PAS_sonar0_crossDistanceLeft "左侧交叉距离";
CM_ SG_ 513 PAS_sonar0_crossDistanceRight "0号雷达发、1号雷达收的间接回波的距离——发波时间戳";
CM_ SG_ 513 PASsonar0crossDistanceRightTime "0号雷达发、1号雷达收的间接回波的距离时间戳——发波时间戳";
CM_ SG_ 513 PAS_sonar0_confidence "置信度";
CM_ SG_ 513 Msg201_PAS_sonar0_Counter "探头发波计数器";
CM_ SG_ 513 PAS_sonar5_DISTANCE "距离";
CM_ SG_ 513 PASsonar5DISTANCETime "5号雷达收到直接回波的时间戳——发波时间戳";
CM_ SG_ 513 PAS_sonar5_Blind "盲区";
CM_ SG_ 513 PAS_sonar5_crossDistanceLeft "左侧交叉距离";
CM_ SG_ 513 PAS_sonar5_crossDistanceRight "右侧交叉距离";
CM_ SG_ 513 PASsonar5crossDistanceLeftTime "5号雷达发、4号雷达收的间接回波的距离时间戳——发波时间戳";
CM_ SG_ 513 PAS_sonar5_confidence "置信度";
CM_ SG_ 513 Msg201_PAS_sonar5_Counter "探头发波计数器";
CM_ SG_ 513 PASDistanceFrontRollingCounter "消息计数器";
CM_ SG_ 513 PAS_Distance_Front_Checksum "校验码";
CM_ SG_ 513 MSG201_Fill4bit "填充位";
CM_ SG_ 514 PAS_sonar7_DISTANCE "距离";
CM_ SG_ 514 PASsonar7DISTANCETime "7号雷达收到直接回波的时间戳——发波时间戳";
CM_ SG_ 514 PAS_sonar7_Blind "盲区";
CM_ SG_ 514 PAS_sonar7_crossDistanceLeft "7号雷达发、6号雷达收的间接回波的距离";
CM_ SG_ 514 PAS_sonar7_crossDistanceRight "7号雷达发、8号雷达收的间接回波的距离";
CM_ SG_ 514 PASsonar7crossDistanceLeftTime "7号雷达发、6号雷达收的间接回波的距离时间戳——发波时间戳";
CM_ SG_ 514 PASsonar7crossDistanceRightTime "7号雷达发、8号雷达收的间接回波的距离时间戳——发波时间戳";
CM_ SG_ 514 PAS_sonar7_confidence "置信度";
CM_ SG_ 514 Msg202_PAS_sonar7_Counter "探头发波计数器";
CM_ SG_ 514 PAS_sonar8_DISTANCE "距离";
CM_ SG_ 514 PASsonar8DISTANCETime "8号雷达收到直接回波的时间戳——发波时间戳";
CM_ SG_ 514 PAS_sonar8_Blind "盲区";
CM_ SG_ 514 PAS_sonar8_crossDistanceLeft "8号雷达发、7号雷达收的间接回波的距离";
CM_ SG_ 514 PAS_sonar8_crossDistanceRight "8号雷达发、9号雷达收的间接回波的距离";
CM_ SG_ 514 PASsonar8crossDistanceLeftTime "8号雷达发、7号雷达收的间接回波的距离时间戳——发波时间戳";
CM_ SG_ 514 PASsonar8crossDistanceRightTime "8号雷达发、9号雷达收的间接回波的距离时间戳——发波时间戳";
CM_ SG_ 514 PAS_sonar8_confidence "置信度";
CM_ SG_ 514 Msg202_PAS_sonar8_Counter "探头发波计数器";
CM_ SG_ 514 PAS_sonar9_DISTANCE "距离";
CM_ SG_ 514 PASsonar9DISTANCETime "9号雷达收到直接回波的时间戳——发波时间戳";
CM_ SG_ 514 PAS_sonar9_Blind "盲区";
CM_ SG_ 514 PAS_sonar9_crossDistanceLeft "9号雷达发、8号雷达收的间接回波的距离";
CM_ SG_ 514 PAS_sonar9_crossDistanceRight "9号雷达发、10号雷达收的间接回波的距离";
CM_ SG_ 514 PASsonar9crossDistanceLeftTime "9号雷达发、8号雷达收的间接回波的距离时间戳——发波时间戳";
CM_ SG_ 514 PASsonar9crossDistanceRightTime "9号雷达发、10号雷达收的间接回波的距离时间戳——发波时间戳";
CM_ SG_ 514 PAS_sonar9_confidence "置信度";
CM_ SG_ 514 Msg202_PAS_sonar9_Counter "探头发波计数器";
CM_ SG_ 514 PAS_sonar10_DISTANCE "距离";
CM_ SG_ 514 PASsonar10DISTANCETime "10号雷达收到直接回波的时间戳——发波时间戳";
CM_ SG_ 514 PAS_sonar10_Blind "盲区";
CM_ SG_ 514 PAS_sonar10_crossDistanceLeft "10号雷达发、9号雷达收的间接回波的距离";
CM_ SG_ 514 PAS_sonar10_crossDistanceRight "10号雷达发、11号雷达收的间接回波的距离";
CM_ SG_ 514 PASsonar10crossDistanceLeftTime "10号雷达发、9号雷达收的间接回波的距离时间戳——发波时间戳";
CM_ SG_ 514 PASsonar10crossDistanceRightTime "10号雷达发、11号雷达收的间接回波的距离时间戳——发波时间戳";
CM_ SG_ 514 PAS_sonar10_confidence "置信度";
CM_ SG_ 514 Msg202_PAS_sonar10_Counter "探头发波计数器";
CM_ SG_ 514 PAS_sonar6_DISTANCE "距离";
CM_ SG_ 514 PASsonar6DISTANCETime "6号雷达收到直接回波的时间戳——发波时间戳";
CM_ SG_ 514 PAS_sonar6_Blind "盲区";
CM_ SG_ 514 PAS_sonar6_crossDistanceLeft "左侧交叉距离";
CM_ SG_ 514 PAS_sonar6_crossDistanceRight "6号雷达发、7号雷达收的间接回波的距离——发波时间戳";
CM_ SG_ 514 PASsonar6crossDistanceRightTime "6号雷达发、7号雷达收的间接回波的距离时间戳——发波时间戳";
CM_ SG_ 514 PAS_sonar6_confidence "置信度";
CM_ SG_ 514 Msg202_PAS_sonar6_Counter "探头发波计数器";
CM_ SG_ 514 PAS_sonar11_DISTANCE "距离";
CM_ SG_ 514 PASsonar11DISTANCETime "11号雷达收到直接回波的时间戳——发波时间戳";
CM_ SG_ 514 PAS_sonar11_Blind "盲区";
CM_ SG_ 514 PAS_sonar11_crossDistanceLeft "11号雷达发、10号雷达收的间接回波的距离";
CM_ SG_ 514 PAS_sonar11_crossDistanceRight "右侧交叉距离";
CM_ SG_ 514 PASsonar11crossDistanceLeftTime "11号雷达发、10号雷达收的间接回波的距离时间戳——发波时间戳";
CM_ SG_ 514 PAS_sonar11_confidence "置信度";
CM_ SG_ 514 Msg202_PAS_sonar11_Counter "探头发波计数器";
CM_ SG_ 514 PAS_Distance_Rear_RollingCounter "消息计数器";
CM_ SG_ 514 PAS_Distance_Rear_Checksum "校验码";
CM_ SG_ 514 MSG202_Fill4bit "填充位";
CM_ SG_ 515 PAS_Sonar0_Echo_TOF1 "第一次回波时间";
CM_ SG_ 515 PAS_Sonar0_Echo_Width1 "第一次回波宽度";
CM_ SG_ 515 PAS_Sonar0_Echo_TOF2 "第二次回波时间";
CM_ SG_ 515 PAS_Sonar0_Echo_Width2 "第二次回波宽度";
CM_ SG_ 515 PAS_Sonar0_Echo_Peak1 "第一次回波高度";
CM_ SG_ 515 PAS_Sonar0_Echo_Peak2 "第二次回波高度";
CM_ SG_ 515 PAS_Sonar0_Emit "对应探头是否发波";
CM_ SG_ 515 PAS_Sonar0_RingingTime "余振时间";
CM_ SG_ 515 Msg203_PAS_Sonar0_Counter "探头工作计数器";
CM_ SG_ 515 PAS_Sonar1_Echo_TOF1 "第一次回波时间";
CM_ SG_ 515 PAS_Sonar1_Echo_Width1 "第一次回波宽度";
CM_ SG_ 515 PAS_Sonar1_Echo_TOF2 "第二次回波时间";
CM_ SG_ 515 PAS_Sonar1_Echo_Width2 "第二次回波宽度";
CM_ SG_ 515 PAS_Sonar1_Echo_Peak1 "第一次回波高度";
CM_ SG_ 515 PAS_Sonar1_Echo_Peak2 "第二次回波高度";
CM_ SG_ 515 PAS_Sonar1_Emit "对应探头是否发波";
CM_ SG_ 515 PAS_Sonar1_RingingTime "余振时间";
CM_ SG_ 515 Msg203_PAS_Sonar1_Counter "探头工作计数器";
CM_ SG_ 515 PAS_Sonar2_Echo_TOF1 "第一次回波时间";
CM_ SG_ 515 PAS_Sonar2_Echo_Width1 "第一次回波宽度";
CM_ SG_ 515 PAS_Sonar2_Echo_TOF2 "第二次回波时间";
CM_ SG_ 515 PAS_Sonar2_Echo_Width2 "第二次回波宽度";
CM_ SG_ 515 PAS_Sonar2_Echo_Peak1 "第一次回波高度";
CM_ SG_ 515 PAS_Sonar2_Echo_Peak2 "第二次回波高度";
CM_ SG_ 515 PAS_Sonar2_Emit "对应探头是否发波";
CM_ SG_ 515 PAS_Sonar2_RingingTime "余振时间";
CM_ SG_ 515 Msg203_PAS_Sonar2_Counter "探头工作计数器";
CM_ SG_ 515 PAS_Sonar3_Echo_TOF1 "第一次回波时间";
CM_ SG_ 515 PAS_Sonar3_Echo_Width1 "第一次回波宽度";
CM_ SG_ 515 PAS_Sonar3_Echo_TOF2 "第二次回波时间";
CM_ SG_ 515 PAS_Sonar3_Echo_Width2 "第二次回波宽度";
CM_ SG_ 515 PAS_Sonar3_Echo_Peak1 "第一次回波高度";
CM_ SG_ 515 PAS_Sonar3_Echo_Peak2 "第二次回波高度";
CM_ SG_ 515 PAS_Sonar3_Emit "对应探头是否发波";
CM_ SG_ 515 PAS_Sonar3_RingingTime "余振时间";
CM_ SG_ 515 Msg203_PAS_Sonar3_Counter "探头工作计数器";
CM_ SG_ 515 PAS_Sonar4_Echo_TOF1 "第一次回波时间";
CM_ SG_ 515 PAS_Sonar4_Echo_Width1 "第一次回波宽度";
CM_ SG_ 515 PAS_Sonar4_Echo_TOF2 "第二次回波时间";
CM_ SG_ 515 PAS_Sonar4_Echo_Width2 "第二次回波宽度";
CM_ SG_ 515 PAS_Sonar4_Echo_Peak1 "第一次回波高度";
CM_ SG_ 515 PAS_Sonar4_Echo_Peak2 "第二次回波高度";
CM_ SG_ 515 PAS_Sonar4_Emit "对应探头是否发波";
CM_ SG_ 515 PAS_Sonar4_RingingTime "余振时间";
CM_ SG_ 515 Msg203_PAS_Sonar4_Counter "探头工作计数器";
CM_ SG_ 515 PAS_Sonar5_Echo_TOF1 "第一次回波时间";
CM_ SG_ 515 PAS_Sonar5_Echo_Width1 "第一次回波宽度";
CM_ SG_ 515 PAS_Sonar5_Echo_TOF2 "第二次回波时间";
CM_ SG_ 515 PAS_Sonar5_Echo_Width2 "第二次回波宽度";
CM_ SG_ 515 PAS_Sonar5_Echo_Peak1 "第一次回波高度";
CM_ SG_ 515 PAS_Sonar5_Echo_Peak2 "第二次回波高度";
CM_ SG_ 515 PAS_Sonar5_Emit "对应探头是否发波";
CM_ SG_ 515 PAS_Sonar5_RingingTime "余振时间";
CM_ SG_ 515 Msg203_PAS_Sonar5_Counter "探头工作计数器";
CM_ SG_ 515 PASSonarInfoFrontRollingCounter "消息计数器";
CM_ SG_ 515 PAS_SonarInfo_Front_Checksum "校验码";
CM_ SG_ 515 MSG203_Fill4bit "填充位";
CM_ SG_ 517 PAS_Sonar6_Echo_TOF1 "第一次回波时间";
CM_ SG_ 517 PAS_Sonar6_Echo_Width1 "第一次回波宽度";
CM_ SG_ 517 PAS_Sonar6_Echo_TOF2 "第二次回波时间";
CM_ SG_ 517 PAS_Sonar6_Echo_Width2 "第二次回波宽度";
CM_ SG_ 517 PAS_Sonar6_Echo_Peak1 "第一次回波高度";
CM_ SG_ 517 PAS_Sonar6_Echo_Peak2 "第二次回波高度";
CM_ SG_ 517 PAS_Sonar6_Emit "对应探头是否发波";
CM_ SG_ 517 PAS_Sonar6_RingingTime "余振时间";
CM_ SG_ 517 Msg205_PAS_Sonar6_Counter "探头工作计数器";
CM_ SG_ 517 PAS_Sonar7_Echo_TOF1 "第一次回波时间";
CM_ SG_ 517 PAS_Sonar7_Echo_Width1 "第一次回波宽度";
CM_ SG_ 517 PAS_Sonar7_Echo_TOF2 "第二次回波时间";
CM_ SG_ 517 PAS_Sonar7_Echo_Width2 "第二次回波宽度";
CM_ SG_ 517 PAS_Sonar7_Echo_Peak1 "第一次回波高度";
CM_ SG_ 517 PAS_Sonar7_Echo_Peak2 "第二次回波高度";
CM_ SG_ 517 PAS_Sonar7_Emit "对应探头是否发波";
CM_ SG_ 517 PAS_Sonar7_RingingTime "余振时间";
CM_ SG_ 517 Msg205_PAS_Sonar7_Counter "探头工作计数器";
CM_ SG_ 517 PAS_Sonar8_Echo_TOF1 "第一次回波时间";
CM_ SG_ 517 PAS_Sonar8_Echo_Width1 "第一次回波宽度";
CM_ SG_ 517 PAS_Sonar8_Echo_TOF2 "第二次回波时间";
CM_ SG_ 517 PAS_Sonar8_Echo_Width2 "第二次回波宽度";
CM_ SG_ 517 PAS_Sonar8_Echo_Peak1 "第一次回波高度";
CM_ SG_ 517 PAS_Sonar8_Echo_Peak2 "第二次回波高度";
CM_ SG_ 517 PAS_Sonar8_Emit "对应探头是否发波";
CM_ SG_ 517 PAS_Sonar8_RingingTime "余振时间";
CM_ SG_ 517 Msg205_PAS_Sonar8_Counter "探头工作计数器";
CM_ SG_ 517 PAS_Sonar9_Echo_TOF1 "第一次回波时间";
CM_ SG_ 517 PAS_Sonar9_Echo_Width1 "第一次回波宽度";
CM_ SG_ 517 PAS_Sonar9_Echo_TOF2 "第二次回波时间";
CM_ SG_ 517 PAS_Sonar9_Echo_Width2 "第二次回波宽度";
CM_ SG_ 517 PAS_Sonar9_Echo_Peak1 "第一次回波高度";
CM_ SG_ 517 PAS_Sonar9_Echo_Peak2 "第二次回波高度";
CM_ SG_ 517 PAS_Sonar9_Emit "对应探头是否发波";
CM_ SG_ 517 PAS_Sonar9_RingingTime "余振时间";
CM_ SG_ 517 Msg205_PAS_Sonar9_Counter "探头工作计数器";
CM_ SG_ 517 PAS_Sonar10_Echo_TOF1 "第一次回波时间";
CM_ SG_ 517 PAS_Sonar10_Echo_Width1 "第一次回波宽度";
CM_ SG_ 517 PAS_Sonar10_Echo_TOF2 "第二次回波时间";
CM_ SG_ 517 PAS_Sonar10_Echo_Width2 "第二次回波宽度";
CM_ SG_ 517 PAS_Sonar10_Echo_Peak1 "第一次回波高度";
CM_ SG_ 517 PAS_Sonar10_Echo_Peak2 "第二次回波高度";
CM_ SG_ 517 PAS_Sonar10_Emit "对应探头是否发波";
CM_ SG_ 517 PAS_Sonar10_RingingTime "余振时间";
CM_ SG_ 517 Msg205_PAS_Sonar10_Counter "探头工作计数器";
CM_ SG_ 517 PAS_Sonar11_Echo_TOF1 "第一次回波时间";
CM_ SG_ 517 PAS_Sonar11_Echo_Width1 "第一次回波宽度";
CM_ SG_ 517 PAS_Sonar11_Echo_TOF2 "第二次回波时间";
CM_ SG_ 517 PAS_Sonar11_Echo_Width2 "第二次回波宽度";
CM_ SG_ 517 PAS_Sonar11_Echo_Peak1 "第一次回波高度";
CM_ SG_ 517 PAS_Sonar11_Echo_Peak2 "第二次回波高度";
CM_ SG_ 517 PAS_Sonar11_Emit "对应探头是否发波";
CM_ SG_ 517 PAS_Sonar11_RingingTime "余振时间";
CM_ SG_ 517 MSG205_PAS_Sonar11_Counter "探头工作计数器";
CM_ SG_ 517 PASSonarInfoRearRollingCounter "消息计数器";
CM_ SG_ 517 PAS_SonarInfo_Rear_Checksum "校验码";
CM_ SG_ 517 MSG205_Fill4bit "填充位";
CM_ SG_ 544 PAS_WakeUp_Response "反馈是否收到MDC的唤醒报文（0x300）";
CM_ SG_ 544 PAS_SonarMode_Response "反馈是否收到MDC的探头工作模式指令（0x302）";
CM_ SG_ 544 PAS_Reponse_RollingCounter "消息计数器";
CM_ SG_ 544 PAS_Reponse_Checksum "校验码";
CM_ SG_ 544 MSG220_Fill4bit "填充位";
CM_ SG_ 560 sensorVersion_Status "反馈是否收到传感器版本信息（0x305）";
CM_ SG_ 560 PAS_SensorStsLR_FLS "左前长距离传感器工作状态";
CM_ SG_ 560 PAS_SensorStsLR_FRS "右前长距离传感器工作状态";
CM_ SG_ 560 PAS_SensorStsSR_FL "左前短距离传感器工作状态";
CM_ SG_ 560 PAS_SensorStsSR_FML "左中前短距离传感器工作状态";
CM_ SG_ 560 PAS_SensorStsSR_FMR "右中前短距离传感器工作状态";
CM_ SG_ 560 PAS_SensorStsSR_FR "右前短距离传感器工作状态";
CM_ SG_ 560 PAS_SensorStsLR_RLS "左后长距离传感器工作状态";
CM_ SG_ 560 PAS_SensorStsLR_RRS "右后长距离传感器工作状态";
CM_ SG_ 560 PAS_SensorStsSR_RL "左后短距离传感器工作状态";
CM_ SG_ 560 PAS_SensorStsSR_RML "左中后短距离传感器工作状态";
CM_ SG_ 560 PAS_SensorStsSR_RMR "右中后短距离传感器工作状态";
CM_ SG_ 560 PAS_SensorStsSR_RR "右后短距离传感器工作状态";
CM_ SG_ 560 PAS_ECU_Status "ECU工作状态";
CM_ SG_ 560 PAS_ECU_VehStatus_Reponse "反馈是否接受的车辆状态信息";
CM_ SG_ 560 PAS_SensorStatus_RollingCounter "消息计数器";
CM_ SG_ 560 PAS_SensorStatus_Checksum "校验码";
CM_ SG_ 560 MSG230_Fill4bit "填充位";
CM_ SG_ 576 PAS_ECU_Information_Ver_Hard "ECU 硬件版本";
CM_ SG_ 576 PAS_ECU_Information_Ver_Soft "ECU 软件版本";
CM_ SG_ 576 PAS_ECU_Information_Ver_Boot "ECU Boot版本";
CM_ SG_ 576 PAS_ECU_Information_Date_Year "升级版本年";
CM_ SG_ 576 PAS_ECU_Information_Date_Month "升级版本月";
CM_ SG_ 576 PAS_ECU_Information_Date_Day "升级版本日";
CM_ SG_ 576 PAS_ECU_Version_Checksum "校验码";
CM_ SG_ 576 PAS_ECUInfo_RollingCounter "消息计数器";
CM_ SG_ 576 MSG240_Fill4bit "填充位";
CM_ SG_ 592 Rpt_Alarm_Id "告警Id";
CM_ SG_ 592 Rpt_Alarm_State "告警状态";
CM_ SG_ 592 Rpt_Alarm_Level "告警级别";
CM_ SG_ 592 Rpt_Transaction_Id "告警序列号";
CM_ SG_ 592 Rpt_Alarm_Para1 "告警描述参数1(电压值)";
CM_ SG_ 592 Rpt_Alarm_Para2 "告警描述参数2";
CM_ SG_ 592 Rpt_Alarm_Para3 "告警描述参数3";
CM_ SG_ 592 Rpt_Alarm_Checksum "校验码";
CM_ SG_ 592 Rpt_Alarm_RollingCounter "消息计数器";
CM_ SG_ 592 MSG250_Fill4bit "填充位";
CM_ SG_ 593 USS_Front_ShortToGND " 前部USS系统对地短路";
CM_ SG_ 593 USS_Front_ShortToUbat " 前部USS系统对电源短路";
CM_ SG_ 593 USS_Rear_ShortToGND " 后部USS系统对地短路";
CM_ SG_ 593 USS_Rear_ShortToUbat " 后部USS系统对电源短路";
CM_ SG_ 593 VHM_Error " 车辆模型错误";
CM_ SG_ 593 Sensor_Version_Fail " 配置失败故障";
CM_ SG_ 593 PAS_Sonar0_Internal_failure " Sonar0内部故障";
CM_ SG_ 593 PAS_Sonar1_Internal_failure " Sonar1内部故障";
CM_ SG_ 593 PAS_Sonar2_Internal_failure " Sonar2内部故障";
CM_ SG_ 593 PAS_Sonar3_Internal_failure " Sonar3内部故障";
CM_ SG_ 593 PAS_Sonar4_Internal_failure " Sonar4内部故障";
CM_ SG_ 593 PAS_Sonar5_Internal_failure " Sonar5内部故障";
CM_ SG_ 593 PAS_Sonar6_Internal_failure " Sonar6内部故障";
CM_ SG_ 593 PAS_Sonar7_Internal_failure " Sonar7内部故障";
CM_ SG_ 593 PAS_Sonar8_Internal_failure " Sonar8内部故障";
CM_ SG_ 593 PAS_Sonar9_Internal_failure " Sonar9内部故障";
CM_ SG_ 593 PAS_Sonar10_Internal_failure " Sonar10内部故障";
CM_ SG_ 593 PAS_Sonar11_Internal_failure " Sonar11内部故障";
CM_ SG_ 593 PAS_AUTHEN_ERROR "设备认证异常";
CM_ SG_ 593 PAS_KEYLEARN_ERROR "密钥学习异常";
CM_ SG_ 593 PAS_TIMESYNC_ERROR "时间同步异常";
CM_ SG_ 593 PAS_ECU_INTERNAL_ERROR "USS ECU 内部故障";
CM_ SG_ 593 PAS_MDCSIGNAL_ERROR "MDC信号无效";
CM_ SG_ 593 PAS_Sonar1_ControlBusFailure "控制器通信是否失败";
CM_ SG_ 593 PAS_Sonar1_RingingTimeFailure "余震时间是否正常";
CM_ SG_ 593 PAS_Sonar1_ShortToGND "是否对地短路或信号线断开";
CM_ SG_ 593 PAS_Sonar1_ShortToPositivePole "是否对Ubat短路或GND开路";
CM_ SG_ 593 PAS_Sonar1_TypeMismatch "探头类型不匹配";
CM_ SG_ 593 PAS_Sonar2_ControlBusFailure "控制器通信是否失败";
CM_ SG_ 593 PAS_Sonar2_RingingTimeFailure "余震时间是否正常";
CM_ SG_ 593 PAS_Sonar2_ShortToGND "是否对地短路或信号线断开";
CM_ SG_ 593 PAS_Sonar2_ShortToPositivePole "是否对Ubat短路或GND开路";
CM_ SG_ 593 PAS_Sonar2_TypeMismatch "探头类型不匹配";
CM_ SG_ 593 PAS_Sonar3_ControlBusFailure "控制器通信是否失败";
CM_ SG_ 593 PAS_Sonar3_RingingTimeFailure "余震时间是否正常";
CM_ SG_ 593 PAS_Sonar3_ShortToGND "是否对地短路或信号线断开";
CM_ SG_ 593 PAS_Sonar3_ShortToPositivePole "是否对Ubat短路或GND开路";
CM_ SG_ 593 PAS_Sonar3_TypeMismatch "探头类型不匹配";
CM_ SG_ 593 PAS_Sonar3_PowerVoltage_Low "供电电压过低";
CM_ SG_ 593 PAS_Sonar3_PowerVoltage_High "供电电压过高";
CM_ SG_ 593 PAS_Sonar4_ControlBusFailure "控制器通信是否失败";
CM_ SG_ 593 PAS_Sonar4_RingingTimeFailure "余震时间是否正常";
CM_ SG_ 593 PAS_Sonar4_ShortToGND "是否对地短路或信号线断开";
CM_ SG_ 593 PAS_Sonar4_ShortToPositivePole "是否对Ubat短路或GND开路";
CM_ SG_ 593 PAS_Sonar4_TypeMismatch "探头类型不匹配";
CM_ SG_ 593 PAS_Sonar7_ControlBusFailure "控制器通信是否失败";
CM_ SG_ 593 PAS_Sonar7_RingingTimeFailure "余震时间是否正常";
CM_ SG_ 593 PAS_Sonar7_ShortToGND "是否对地短路或信号线断开";
CM_ SG_ 593 PAS_Sonar7_ShortToPositivePole "是否对Ubat短路或GND开路";
CM_ SG_ 593 PAS_Sonar7_TypeMismatch "探头类型不匹配";
CM_ SG_ 593 PAS_Sonar8_ControlBusFailure "控制器通信是否失败";
CM_ SG_ 593 PAS_Sonar8_RingingTimeFailure "余震时间是否正常";
CM_ SG_ 593 PAS_Sonar8_ShortToGND "是否对地短路或信号线断开";
CM_ SG_ 593 PAS_Sonar8_ShortToPositivePole "是否对Ubat短路或GND开路";
CM_ SG_ 593 PAS_Sonar8_TypeMismatch "探头类型不匹配";
CM_ SG_ 593 PAS_Sonar9_ControlBusFailure "控制器通信是否失败";
CM_ SG_ 593 PAS_Sonar9_RingingTimeFailure "余震时间是否正常";
CM_ SG_ 593 PAS_Sonar9_ShortToGND "是否对地短路或信号线断开";
CM_ SG_ 593 PAS_Sonar9_ShortToPositivePole "是否对Ubat短路或GND开路";
CM_ SG_ 593 PAS_Sonar9_TypeMismatch "探头类型不匹配";
CM_ SG_ 593 PAS_Sonar10_ControlBusFailure "控制器通信是否失败";
CM_ SG_ 593 PAS_Sonar10_RingingTimeFailure "余震时间是否正常";
CM_ SG_ 593 PAS_Sonar10_ShortToGND "是否对地短路或信号线断开";
CM_ SG_ 593 PAS_Sonar10_ShortToPositivePole "是否对Ubat短路或GND开路";
CM_ SG_ 593 PAS_Sonar10_TypeMismatch "探头类型不匹配";
CM_ SG_ 593 PAS_Sonar0_ControlBusFailure "控制器通信是否失败";
CM_ SG_ 593 PAS_Sonar0_RingingTimeFailure "余震时间是否正常";
CM_ SG_ 593 PAS_Sonar0_ShortToGND "是否对地短路或信号线断开";
CM_ SG_ 593 PAS_Sonar0_ShortToPositivePole "是否对Ubat短路或GND开路";
CM_ SG_ 593 PAS_Sonar0_TypeMismatch "探头类型不匹配";
CM_ SG_ 593 PAS_Sonar5_ControlBusFailure "控制器通信是否失败";
CM_ SG_ 593 PAS_Sonar5_RingingTimeFailure "余震时间是否正常";
CM_ SG_ 593 PAS_Sonar5_ShortToGND "是否对地短路或信号线断开";
CM_ SG_ 593 PAS_Sonar5_ShortToPositivePole "是否对Ubat短路或GND开路";
CM_ SG_ 593 PAS_Sonar5_TypeMismatch "探头类型不匹配";
CM_ SG_ 593 PAS_Sonar6_ControlBusFailure "控制器通信是否失败";
CM_ SG_ 593 PAS_Sonar6_RingingTimeFailure "余震时间是否正常";
CM_ SG_ 593 PAS_Sonar6_ShortToGND "是否对地短路或信号线断开";
CM_ SG_ 593 PAS_Sonar6_ShortToPositivePole "是否对Ubat短路或GND开路";
CM_ SG_ 593 PAS_Sonar6_TypeMismatch "探头类型不匹配";
CM_ SG_ 593 PAS_Sonar11_ControlBusFailure "控制器通信是否失败";
CM_ SG_ 593 PAS_Sonar11_RingingTimeFailure "余震时间是否正常";
CM_ SG_ 593 PAS_Sonar11_ShortToGND "是否对地短路或信号线断开";
CM_ SG_ 593 PAS_Sonar11_ShortToPositivePole "是否对Ubat短路或GND开路";
CM_ SG_ 593 PAS_Sonar11_TypeMismatch "探头类型不匹配";
CM_ SG_ 593 PAS_ECU_OverVoltage "系统过压";
CM_ SG_ 593 PAS_ECU_UnderVoltage "系统欠压";
CM_ SG_ 593 PAS_ECU_BusOff_ERROR "ECU CAN Busoff错误";
CM_ SG_ 593 PAS_MDC_COMMU_ERROR "MDC通信丢失";
CM_ SG_ 593 PAS_ECU_EEPROM_ERROR "EEPROM错误";
CM_ SG_ 593 PAS_DiagnosisInfo_RollingCounter "消息计数器";
CM_ SG_ 593 PAS_DiagnosisInfo_Checksum "校验码";
CM_ SG_ 593 MSG251_Fill4bit "填充位";
CM_ SG_ 672 PAS_Device_Vertify_Times "设备认证次数";
CM_ SG_ 672 PAS_Device_Vertify_Status "当前设备认证状态";
CM_ SG_ 673 PAS_RandomByte1 "随机数_传感器";
CM_ SG_ 673 PAS_RandomByte2 "随机数_传感器";
CM_ SG_ 673 PAS_RandomByte3 "随机数_传感器";
CM_ SG_ 673 PAS_RandomByte4 "随机数_传感器";
CM_ SG_ 673 PAS_RandomByte5 "随机数_传感器";
CM_ SG_ 673 PAS_RandomByte6 "随机数_传感器";
CM_ SG_ 673 PAS_RandomByte7 "随机数_传感器";
CM_ SG_ 673 PAS_RandomByte8 "随机数_传感器";
CM_ SG_ 673 PAS_SessionID "当前挑战应答的会话ID";
CM_ SG_ 674 PAS_Verification_Result "传感器校验结果。如果传感器校验会话ID失败，或者校验CMAC值不一致，设置该值为失败，结束本次认证流程";
CM_ SG_ 674 PAS_SessionID "密钥协商会话ID";
CM_ SG_ 674 PAS_CMACByte1 "CMAC（随机数拼接会话ID）后，取结果的高64位";
CM_ SG_ 674 PAS_CMACByte2 "CMAC（随机数拼接会话ID）后，取结果的高64位";
CM_ SG_ 674 PAS_CMACByte3 "CMAC（随机数拼接会话ID）后，取结果的高64位";
CM_ SG_ 674 PAS_CMACByte4 "CMAC（随机数拼接会话ID）后，取结果的高64位";
CM_ SG_ 674 PAS_CMACByte5 "CMAC（随机数拼接会话ID）后，取结果的高64位";
CM_ SG_ 674 PAS_CMACByte6 "CMAC（随机数拼接会话ID）后，取结果的高64位";
CM_ SG_ 674 PAS_CMACByte7 "CMAC（随机数拼接会话ID）后，取结果的高64位";
CM_ SG_ 674 PAS_CMACByte8 "CMAC（随机数拼接会话ID）后，取结果的高64位";
CM_ SG_ 706 PAS_Key_Learn_SubID "传感器_KeyLearnSubID";
CM_ SG_ 706 PAS_Key_Learn_Numbers "反馈的密钥学习状态个数";
CM_ SG_ 706 PAS_SKID1 "密钥ID1";
CM_ SG_ 706 PAS_SK_Learn_Status1 "密钥学习状态1";
CM_ SG_ 706 PAS_SKID2 "密钥ID2";
CM_ SG_ 706 PAS_SK_Learn_Status2 "密钥学习状态2";
CM_ SG_ 706 PAS_SKID3 "密钥ID3";
CM_ SG_ 706 PAS_SK_Learn_Status3 "密钥学习状态3";
CM_ SG_ 706 PAS_SKID4 "密钥ID4";
CM_ SG_ 706 PAS_SK_Learn_Status4 "密钥学习状态4";
CM_ SG_ 706 PAS_SKID5 "密钥ID5";
CM_ SG_ 706 PAS_SK_Learn_Status5 "密钥学习状态5";
CM_ SG_ 706 PAS_SKID6 "密钥ID6";
CM_ SG_ 706 PAS_SK_Learn_Status6 "密钥学习状态6";
CM_ SG_ 706 PAS_SKID7 "密钥ID7";
CM_ SG_ 706 PAS_SK_Learn_Status7 "密钥学习状态7";
CM_ SG_ 706 PAS_SKID8 "密钥ID8";
CM_ SG_ 706 PAS_SK_Learn_Status8 "密钥学习状态8";
CM_ SG_ 706 PAS_SKID9 "密钥ID9";
CM_ SG_ 706 PAS_SK_Learn_Status9 "密钥学习状态9";
CM_ SG_ 706 PAS_SKID10 "密钥ID10";
CM_ SG_ 706 PAS_SK_Learn_Status10 "密钥学习状态10";
CM_ SG_ 706 PAS_SKID11 "密钥ID11";
CM_ SG_ 706 PAS_SK_Learn_Status11 "密钥学习状态11";
CM_ SG_ 706 PAS_SKID12 "密钥ID12";
CM_ SG_ 706 PAS_SK_Learn_Status12 "密钥学习状态12";
CM_ SG_ 708 PASKeyLearnSubIDSettingResponse "传感器_KeyLearnSubID";
CM_ SG_ 708 PAS_SK_Setting_Response "设置学习状态反馈的密钥ID";
CM_ SG_ 708 PAS_SK_Setting_Status "学习状态";
CM_ SG_ 707 PAS_VerifySubID "传感器反馈AES计算结果，此字段携带1";
CM_ SG_ 707 PAS_Verify_SKID "设置学习状态反馈的密钥ID";
CM_ SG_ 707 PAS_Verify_AES_Result "32bit的加密密文，AES128-GCM，none-padding";
CM_ SG_ 707 PAS_Verify_MACbyte1 "GCM计算的MAC，AES128-GCM，none-padding";
CM_ SG_ 707 PAS_Verify_MACbyte2 "GCM计算的MAC，AES128-GCM，none-padding";
CM_ SG_ 707 PAS_Verify_MACbyte3 "GCM计算的MAC，AES128-GCM，none-padding";
CM_ SG_ 707 PAS_Verify_MACbyte4 "GCM计算的MAC，AES128-GCM，none-padding";
CM_ SG_ 707 PAS_Verify_MACbyte5 "GCM计算的MAC，AES128-GCM，none-padding";
CM_ SG_ 707 PAS_Verify_MACbyte6 "GCM计算的MAC，AES128-GCM，none-padding";
CM_ SG_ 707 PAS_Verify_MACbyte7 "GCM计算的MAC，AES128-GCM，none-padding";
CM_ SG_ 707 PAS_Verify_MACbyte8 "GCM计算的MAC，AES128-GCM，none-padding";
CM_ SG_ 707 PAS_Verify_MACbyte9 "GCM计算的MAC，AES128-GCM，none-padding";
CM_ SG_ 707 PAS_Verify_MACbyte10 "GCM计算的MAC，AES128-GCM，none-padding";
CM_ SG_ 707 PAS_Verify_MACbyte11 "GCM计算的MAC，AES128-GCM，none-padding";
CM_ SG_ 707 PAS_Verify_MACbyte12 "GCM计算的MAC，AES128-GCM，none-padding";
CM_ SG_ 707 PAS_Verify_MACbyte13 "GCM计算的MAC，AES128-GCM，none-padding";
CM_ SG_ 707 PAS_Verify_MACbyte14 "GCM计算的MAC，AES128-GCM，none-padding";
CM_ SG_ 707 PAS_Verify_MACbyte15 "GCM计算的MAC，AES128-GCM，none-padding";
CM_ SG_ 707 PAS_Verify_MACbyte16 "GCM计算的MAC，AES128-GCM，none-padding";
CM_ SG_ 707 PAS_Verify_IVByte1 "96bit 的IV";
CM_ SG_ 707 PAS_Verify_IVByte2 "96bit 的IV";
CM_ SG_ 707 PAS_Verify_IVByte3 "96bit 的IV";
CM_ SG_ 707 PAS_Verify_IVByte4 "96bit 的IV";
CM_ SG_ 707 PAS_Verify_IVByte5 "96bit 的IV";
CM_ SG_ 707 PAS_Verify_IVByte6 "96bit 的IV";
CM_ SG_ 707 PAS_Verify_IVByte7 "96bit 的IV";
CM_ SG_ 707 PAS_Verify_IVByte8 "96bit 的IV";
CM_ SG_ 707 PAS_Verify_IVByte9 "96bit 的IV";
CM_ SG_ 707 PAS_Verify_IVByte10 "96bit 的IV";
CM_ SG_ 707 PAS_Verify_IVByte11 "96bit 的IV";
CM_ SG_ 707 PAS_Verify_IVByte12 "96bit 的IV";
CM_ SG_ 640 UPC_VehiclePosition_X "Vehicle position in X Coordinate
车辆的X坐标";
CM_ SG_ 640 UPC_VehiclePosition_Y "Vehicle position in Y Coordinate
车辆的Y坐标";
CM_ SG_ 640 UPCVehiclePositionUpdateTime "Time Stamp for the time when the vehicle position update
车辆坐标更新的时间戳";
CM_ SG_ 640 UPC_VehiclePosition_Curvature "Vehicle curvature
车辆的行驶曲率半径";
CM_ SG_ 640 UPC_VehiclePosition_YawAngle "Vehicle yawangle
车辆的横摆角";
CM_ SG_ 640 UPCVehiclePositionDriveDistance "Vehicle drive distance
车辆的行驶距离";
CM_ SG_ 640 PAS_VehPos_Checksum "Checksum";
CM_ SG_ 640 PAS_VehPos_RollingCounter "Message Rolling counter";
CM_ SG_ 641 PAS_PSL_Checksum "校验码";
CM_ SG_ 641 PAS_PSL_RollingCounter "消息计数器";
CM_ SG_ 642 PAS_EchoMap_Checksum "校验码";
CM_ SG_ 642 PAS_EchoMap_RollingCounter "消息计数器";
CM_ SG_ 768 MDC_PAS_Control "MDC命令PAS的系统状态
0x00:system off (暂时Reserved，网络上有信号，自动维持standby状态，因此可以省略system off指令）
0x01:standby
0x02:Enable
0x03:reserved";
CM_ SG_ 768 MDC_PAS_Control_RollingCounter "消息计数器";
CM_ SG_ 768 MDC_PAS_Control_Checksum "校验码";
CM_ SG_ 768 MSG300_Fill4bit "填充位";
CM_ SG_ 769 MDC_ESC_VehicleSpeed "ABS_ESC信号提示车速";
CM_ SG_ 769 MDC_ESC_VehicleSpeed_Valid "车速有效";
CM_ SG_ 769 MDC_SAS_SteerWheelAngle "实际方向盘转向角";
CM_ SG_ 769 MDC_SAS_SteerWheelAngle_Valid "方向盘转向角有效";
CM_ SG_ 769 MDC_BCM_OutTemp "用于温度补偿";
CM_ SG_ 769 MDC_BCM_OutTemp_Valid "温度有效";
CM_ SG_ 769 MDC_VCU_GearStatus "档位
0x00:P
0x01:N
0x02:D
0x03:R";
CM_ SG_ 769 MDC_VCU_GearStatus_Valid "档位有效";
CM_ SG_ 769 MDC_ESC_FLWheelSpeedRC "ESC信号提示左前轮速脉冲信号";
CM_ SG_ 769 MDC_ESC_FLWheelSpeedRC_Valid "ESC信号提示左前轮速脉冲信号有效";
CM_ SG_ 769 MDC_ESC_FRWheelSpeedRC "ESC信号提示右前轮速脉冲信号";
CM_ SG_ 769 MDC_ESC_FRWheelSpeedRC_Valid "ESC信号提示右前轮速脉冲信号有效";
CM_ SG_ 769 MDC_ESC_RLWheelSpeedRC "ESC 信号提示左后轮速脉冲信号";
CM_ SG_ 769 MDC_ESC_RLWheelSpeedRC_Valid "ESC 信号提示左后轮速脉冲信号有效";
CM_ SG_ 769 MDC_ESC_RRWheelSpeedRC "ESC信号提示右后轮速脉冲信号";
CM_ SG_ 769 MDC_ESC_RRWheelSpeedRC_Valid "ESC信号提示右后轮速脉冲信号有效";
CM_ SG_ 769 MDC_ESC_FLWheelDirection "ESC指示左前轮方向";
CM_ SG_ 769 MDC_ESC_FLWheelDirection_Valid "ESC指示左前轮方向有效";
CM_ SG_ 769 MDC_ESC_FRWheelDirection "ESC指示右前轮方向";
CM_ SG_ 769 MDC_ESC_FRWheelDirection_Valid "ESC指示右前轮方向有效";
CM_ SG_ 769 MDC_ESC_RLWheelDirection "ESC指示左后轮方向";
CM_ SG_ 769 MDC_ESC_RLWheelDirection_Valid "ESC指示左后轮方向有效";
CM_ SG_ 769 MDC_ESC_RRWheelDirection "ESC指示右后轮方向";
CM_ SG_ 769 MDC_ESC_RRWheelDirection_Valid "ESC指示右后轮方向有效";
CM_ SG_ 769 MDC_VehStatus_RollingCounter "消息计数器";
CM_ SG_ 769 MDC_VehStatus_Checksum "校验码";
CM_ SG_ 769 YawRate "Yaw RateWz横摆角速度";
CM_ SG_ 769 YawRateSensor_St "Yaw Rate Sensor State
Wz横摆角速度状态";
CM_ SG_ 769 wheelspeedValid "轮速信息有效性";
CM_ SG_ 769 wheelspeedFl "左前轮轮速";
CM_ SG_ 769 wheelspeedFr "右前轮轮速";
CM_ SG_ 769 wheelspeedRr "右后轮轮速";
CM_ SG_ 769 wheelspeedRl "左后轮轮速";
CM_ SG_ 769 ecasVehiclePositionState "整车位置状态";
CM_ SG_ 769 ecasVehicleUpDownState "整车升降状态";
CM_ SG_ 769 VehiclePositionStateValid "整车位置状态有效位";
CM_ SG_ 769 VehicleUpDownStateValid "整车升降状态有效位";
CM_ SG_ 770 PAS_Sonar1_Req "UPA1号探头工作模式指令";
CM_ SG_ 770 PAS_Sonar1_Req_counter "UPA1号探头工作模式指令计数";
CM_ SG_ 770 PAS_Sonar2_Req "UPA2号探头工作模式指令";
CM_ SG_ 770 PAS_Sonar2_Req_counter "UPA1号探头工作模式指令计数";
CM_ SG_ 770 PAS_Sonar3_Req "UPA3号探头工作模式指令";
CM_ SG_ 770 PAS_Sonar3_Req_counter "UPA1号探头工作模式指令计数";
CM_ SG_ 770 PAS_Sonar4_Req "UPA4号探头工作模式指令";
CM_ SG_ 770 PAS_Sonar4_Req_counter "UPA1号探头工作模式指令计数";
CM_ SG_ 770 PAS_Sonar7_Req "UPA7号探头工作模式指令";
CM_ SG_ 770 PAS_Sonar7_Req_counter "UPA1号探头工作模式指令计数";
CM_ SG_ 770 PAS_Sonar8_Req "UPA8号探头工作模式指令";
CM_ SG_ 770 PAS_Sonar8_Req_counter "UPA1号探头工作模式指令计数";
CM_ SG_ 770 PAS_Sonar9_Req "UPA9号探头工作模式指令";
CM_ SG_ 770 PAS_Sonar9_Req_counter "UPA1号探头工作模式指令计数";
CM_ SG_ 770 PAS_Sonar10_Req "UPA10号探头工作模式指令";
CM_ SG_ 770 PAS_Sonar10_Req_counter "UPA1号探头工作模式指令计数";
CM_ SG_ 770 PAS_Sonar0_Req "UPA0号探头工作模式指令";
CM_ SG_ 770 PAS_Sonar0_Req_counter "UPA1号探头工作模式指令计数";
CM_ SG_ 770 PAS_Sonar5_Req "UPA5号探头工作模式指令";
CM_ SG_ 770 PAS_Sonar5_Req_counter "UPA1号探头工作模式指令计数";
CM_ SG_ 770 PAS_Sonar6_Req "UPA6号探头工作模式指令";
CM_ SG_ 770 PAS_Sonar6_Req_counter "UPA1号探头工作模式指令计数";
CM_ SG_ 770 PAS_Sonar11_Req "UPA11号探头工作模式指令";
CM_ SG_ 770 PAS_Sonar11_Req_counter "UPA1号探头工作模式指令计数";
CM_ SG_ 770 Sonar_Req_RollingCounter "消息计数器";
CM_ SG_ 770 Sonar_Req_Checksum "校验码";
CM_ SG_ 770 MSG302_Fill4bit "填充位";
CM_ SG_ 770 PAS_Function_Req "发波模式控制选择";
CM_ SG_ 771 Ack_Alarm_Id "告警Id";
CM_ SG_ 771 Ack_Alarm_State "告警状态";
CM_ SG_ 771 Ack_Alarm_Level "告警级别";
CM_ SG_ 771 Ack_Transaction_Id "告警序列号";
CM_ SG_ 771 Ack_Alarm_Checksum "校验码";
CM_ SG_ 771 Ack_Alarm_RollingCounter "消息计数器";
CM_ SG_ 771 MSG303_Fill4bit "填充位";
CM_ SG_ 772 Sync_Type "Time synchronization message - type
时间同步报文的类型
(Type=0x20:Tsync,
Type=0x28:TSync FUP)";
CM_ SG_ 772 Sync_CRC "Time synchronization message - CRC (Cyclic Redundancy Check)
循环冗余校验值";
CM_ SG_ 772 Sync_Counter "Time synchronization message - sequence counter指令计数器";
CM_ SG_ 772 Sync_TimeDomain "Time synchronization message - time domain时间同步域";
CM_ SG_ 772 Sync_OVS "Time synchronization message - Overflow of second溢出时间";
CM_ SG_ 772 Sync_SGW "Time synchronization message - Time Gateway synchronization status网关时间同步状态";
CM_ SG_ 772 Sync_Reserved "in FUP PDU,default = 0Reserved for Time Sync function";
CM_ SG_ 772 Sync_SyncTime "Time synchronization message - Synchronization time同步时间";
CM_ SG_ 928 MDC_RandomByte1 "随机数_MDC";
CM_ SG_ 928 MDC_RandomByte2 "随机数_MDC";
CM_ SG_ 928 MDC_RandomByte3 "随机数_MDC";
CM_ SG_ 928 MDC_RandomByte4 "随机数_MDC";
CM_ SG_ 928 MDC_RandomByte5 "随机数_MDC";
CM_ SG_ 928 MDC_RandomByte6 "随机数_MDC";
CM_ SG_ 928 MDC_RandomByte7 "随机数_MDC";
CM_ SG_ 928 MDC_RandomByte8 "随机数_MDC";
CM_ SG_ 928 MDC_SessionID "密钥协商会话ID";
CM_ SG_ 929 MDC_Response_Result "MDC校验结果，如果会话ID不一致，MDC将该值设为失败，同时MDC结束本次认证流程。传感器收到该结果为失败，也结束本次认证流程；如果该结果为成功，则继续后需处理。";
CM_ SG_ 929 MDC_Response_SessionID "密钥协商会话ID";
CM_ SG_ 929 MDC_Response_CMACByte1 "MDC发送给传感器的挑战应答值，CMAC（随机数拼接会话ID）后，取结果的低64位";
CM_ SG_ 929 MDC_Response_CMACByte2 "MDC发送给传感器的挑战应答值，CMAC（随机数拼接会话ID）后，取结果的低64位";
CM_ SG_ 929 MDC_Response_CMACByte3 "MDC发送给传感器的挑战应答值，CMAC（随机数拼接会话ID）后，取结果的低64位";
CM_ SG_ 929 MDC_Response_CMACByte4 "MDC发送给传感器的挑战应答值，CMAC（随机数拼接会话ID）后，取结果的低64位";
CM_ SG_ 929 MDC_Response_CMACByte5 "MDC发送给传感器的挑战应答值，CMAC（随机数拼接会话ID）后，取结果的低64位";
CM_ SG_ 929 MDC_Response_CMACByte6 "MDC发送给传感器的挑战应答值，CMAC（随机数拼接会话ID）后，取结果的低64位";
CM_ SG_ 929 MDC_Response_CMACByte7 "MDC发送给传感器的挑战应答值，CMAC（随机数拼接会话ID）后，取结果的低64位";
CM_ SG_ 929 MDC_Response_CMACByte8 "MDC发送给传感器的挑战应答值，CMAC（随机数拼接会话ID）后，取结果的低64位";
CM_ SG_ 960 Mdc_KeyLearnSubID "获取传感器密钥学习状态，此字段携带1";
CM_ SG_ 960 Mdc_KeyLearn_Numbers "查询密钥学习状态个数，最多12个";
CM_ SG_ 960 Mdc_KeyLearn_SKID1 "根据查询密钥个数读取密钥ID个数，1~12。0为无效值";
CM_ SG_ 962 Mdc_KeyLearnSubID_Send "MDC给传感器发送SKC和SC，此字段携带2";
CM_ SG_ 962 Mdc_KeyLearn_transmit_SKID "传输保护密钥ID";
CM_ SG_ 962 Mdc_KeyLearn_update_SKID "更新密钥ID";
CM_ SG_ 962 Mdc_KeyLearn_SKCByte1 "128bit的SKC密文，AES128-GCM，none-padding";
CM_ SG_ 962 Mdc_KeyLearn_SKCByte2 "128bit的SKC密文，AES128-GCM，none-padding";
CM_ SG_ 962 Mdc_KeyLearn_SKCByte3 "128bit的SKC密文，AES128-GCM，none-padding";
CM_ SG_ 962 Mdc_KeyLearn_SKCByte4 "128bit的SKC密文，AES128-GCM，none-padding";
CM_ SG_ 962 Mdc_KeyLearn_SKCByte5 "128bit的SKC密文，AES128-GCM，none-padding";
CM_ SG_ 962 Mdc_KeyLearn_SKCByte6 "128bit的SKC密文，AES128-GCM，none-padding";
CM_ SG_ 962 Mdc_KeyLearn_SKCByte7 "128bit的SKC密文，AES128-GCM，none-padding";
CM_ SG_ 962 Mdc_KeyLearn_SKCByte8 "128bit的SKC密文，AES128-GCM，none-padding";
CM_ SG_ 962 Mdc_KeyLearn_SKCByte9 "128bit的SKC密文，AES128-GCM，none-padding";
CM_ SG_ 962 Mdc_KeyLearn_SKCByte10 "128bit的SKC密文，AES128-GCM，none-padding";
CM_ SG_ 962 Mdc_KeyLearn_SKCByte11 "128bit的SKC密文，AES128-GCM，none-padding";
CM_ SG_ 962 Mdc_KeyLearn_SKCByte12 "128bit的SKC密文，AES128-GCM，none-padding";
CM_ SG_ 962 Mdc_KeyLearn_SKCByte13 "128bit的SKC密文，AES128-GCM，none-padding";
CM_ SG_ 962 Mdc_KeyLearn_SKCByte14 "128bit的SKC密文，AES128-GCM，none-padding";
CM_ SG_ 962 Mdc_KeyLearn_SKCByte15 "128bit的SKC密文，AES128-GCM，none-padding";
CM_ SG_ 962 Mdc_KeyLearn_SKCByte16 "128bit的SKC密文，AES128-GCM，none-padding";
CM_ SG_ 962 Mdc_KeyLearn_MACByte1 "GCM计算的MAC，AES128-GCM，none-padding";
CM_ SG_ 962 Mdc_KeyLearn_MACByte2 "GCM计算的MAC，AES129-GCM，none-padding";
CM_ SG_ 962 Mdc_KeyLearn_MACByte3 "GCM计算的MAC，AES130-GCM，none-padding";
CM_ SG_ 962 Mdc_KeyLearn_MACByte4 "GCM计算的MAC，AES131-GCM，none-padding";
CM_ SG_ 962 Mdc_KeyLearn_MACByte5 "GCM计算的MAC，AES132-GCM，none-padding";
CM_ SG_ 962 Mdc_KeyLearn_MACByte6 "GCM计算的MAC，AES133-GCM，none-padding";
CM_ SG_ 962 Mdc_KeyLearn_MACByte7 "GCM计算的MAC，AES134-GCM，none-padding";
CM_ SG_ 962 Mdc_KeyLearn_MACByte8 "GCM计算的MAC，AES135-GCM，none-padding";
CM_ SG_ 962 Mdc_KeyLearn_MACByte9 "GCM计算的MAC，AES136-GCM，none-padding";
CM_ SG_ 962 Mdc_KeyLearn_MACByte10 "GCM计算的MAC，AES137-GCM，none-padding";
CM_ SG_ 962 Mdc_KeyLearn_MACByte11 "GCM计算的MAC，AES138-GCM，none-padding";
CM_ SG_ 962 Mdc_KeyLearn_MACByte12 "GCM计算的MAC，AES139-GCM，none-padding";
CM_ SG_ 962 Mdc_KeyLearn_MACByte13 "GCM计算的MAC，AES140-GCM，none-padding";
CM_ SG_ 962 Mdc_KeyLearn_MACByte14 "GCM计算的MAC，AES141-GCM，none-padding";
CM_ SG_ 962 Mdc_KeyLearn_MACByte15 "GCM计算的MAC，AES142-GCM，none-padding";
CM_ SG_ 962 Mdc_KeyLearn_MACByte16 "GCM计算的MAC，AES143-GCM，none-padding";
CM_ SG_ 962 Mdc_KeyLearn_IVByte1 "96bit 的IV";
CM_ SG_ 962 Mdc_KeyLearn_IVByte2 "96bit 的IV";
CM_ SG_ 962 Mdc_KeyLearn_IVByte3 "96bit 的IV";
CM_ SG_ 962 Mdc_KeyLearn_IVByte4 "96bit 的IV";
CM_ SG_ 962 Mdc_KeyLearn_IVByte5 "96bit 的IV";
CM_ SG_ 962 Mdc_KeyLearn_IVByte6 "96bit 的IV";
CM_ SG_ 962 Mdc_KeyLearn_IVByte7 "96bit 的IV";
CM_ SG_ 962 Mdc_KeyLearn_IVByte8 "96bit 的IV";
CM_ SG_ 962 Mdc_KeyLearn_IVByte9 "96bit 的IV";
CM_ SG_ 962 Mdc_KeyLearn_IVByte10 "96bit 的IV";
CM_ SG_ 962 Mdc_KeyLearn_IVByte11 "96bit 的IV";
CM_ SG_ 962 Mdc_KeyLearn_IVByte12 "96bit 的IV";
CM_ SG_ 962 Mdc_KeyLearn_SC "3字节SC";
CM_ SG_ 963 Mdc_KeyLearnSubID_SKSetting "MDC设置传感器学习状态，传感器收到此消息置为已学习。此字段携带5";
CM_ SG_ 963 Mdc_KeyLearn_SKID "需要设置学习状态的密钥ID";
CM_ SG_ 964 Mdc_KeyLearnSubID_CleanID "MDC清除传感器学习状态，此字段携带6";
CM_ SG_ 964 Mdc_KeyLearn_Clean_SKID "清除学习状态的密钥ID。HuaweiPSK不能清除，此处不能携带0";
CM_ SG_ 964 Mdc_KeyLearn_Clean_SCByte1 "密文=AES128-GCM(8bit密钥ID（低位） |24bit SC |96bit 填充0";
CM_ SG_ 964 Mdc_KeyLearn_Clean_SCByte2 "密文=AES128-GCM(8bit密钥ID（低位） |24bit SC |96bit 填充0";
CM_ SG_ 964 Mdc_KeyLearn_Clean_SCByte3 "密文=AES128-GCM(8bit密钥ID（低位） |24bit SC |96bit 填充0";
CM_ SG_ 964 Mdc_KeyLearn_Clean_SCByte4 "密文=AES128-GCM(8bit密钥ID（低位） |24bit SC |96bit 填充0";
CM_ SG_ 964 Mdc_KeyLearn_Clean_SCByte5 "密文=AES128-GCM(8bit密钥ID（低位） |24bit SC |96bit 填充0";
CM_ SG_ 964 Mdc_KeyLearn_Clean_SCByte6 "密文=AES128-GCM(8bit密钥ID（低位） |24bit SC |96bit 填充0";
CM_ SG_ 964 Mdc_KeyLearn_Clean_SCByte7 "密文=AES128-GCM(8bit密钥ID（低位） |24bit SC |96bit 填充0";
CM_ SG_ 964 Mdc_KeyLearn_Clean_SCByte8 "密文=AES128-GCM(8bit密钥ID（低位） |24bit SC |96bit 填充0";
CM_ SG_ 964 Mdc_KeyLearn_Clean_SCByte9 "密文=AES128-GCM(8bit密钥ID（低位） |24bit SC |96bit 填充0";
CM_ SG_ 964 Mdc_KeyLearn_Clean_SCByte10 "密文=AES128-GCM(8bit密钥ID（低位） |24bit SC |96bit 填充0";
CM_ SG_ 964 Mdc_KeyLearn_Clean_SCByte11 "密文=AES128-GCM(8bit密钥ID（低位） |24bit SC |96bit 填充0";
CM_ SG_ 964 Mdc_KeyLearn_Clean_SCByte12 "密文=AES128-GCM(8bit密钥ID（低位） |24bit SC |96bit 填充0";
CM_ SG_ 964 Mdc_KeyLearn_Clean_SCByte13 "密文=AES128-GCM(8bit密钥ID（低位） |24bit SC |96bit 填充0";
CM_ SG_ 964 Mdc_KeyLearn_Clean_SCByte14 "密文=AES128-GCM(8bit密钥ID（低位） |24bit SC |96bit 填充0";
CM_ SG_ 964 Mdc_KeyLearn_Clean_SCByte15 "密文=AES128-GCM(8bit密钥ID（低位） |24bit SC |96bit 填充0";
CM_ SG_ 964 Mdc_KeyLearn_Clean_SCByte16 "密文=AES128-GCM(8bit密钥ID（低位） |24bit SC |96bit 填充0";
CM_ SG_ 964 Mdc_KeyLearn_Clean_MACByte1 "AES-GCM计算的MAC";
CM_ SG_ 964 Mdc_KeyLearn_Clean_MACByte2 "AES-GCM计算的MAC";
CM_ SG_ 964 Mdc_KeyLearn_Clean_MACByte3 "AES-GCM计算的MAC";
CM_ SG_ 964 Mdc_KeyLearn_Clean_MACByte4 "AES-GCM计算的MAC";
CM_ SG_ 964 Mdc_KeyLearn_Clean_MACByte5 "AES-GCM计算的MAC";
CM_ SG_ 964 Mdc_KeyLearn_Clean_MACByte6 "AES-GCM计算的MAC";
CM_ SG_ 964 Mdc_KeyLearn_Clean_MACByte7 "AES-GCM计算的MAC";
CM_ SG_ 964 Mdc_KeyLearn_Clean_MACByte8 "AES-GCM计算的MAC";
CM_ SG_ 964 Mdc_KeyLearn_Clean_MACByte9 "AES-GCM计算的MAC";
CM_ SG_ 964 Mdc_KeyLearn_Clean_MACByte10 "AES-GCM计算的MAC";
CM_ SG_ 964 Mdc_KeyLearn_Clean_MACByte11 "AES-GCM计算的MAC";
CM_ SG_ 964 Mdc_KeyLearn_Clean_MACByte12 "AES-GCM计算的MAC";
CM_ SG_ 964 Mdc_KeyLearn_Clean_MACByte13 "AES-GCM计算的MAC";
CM_ SG_ 964 Mdc_KeyLearn_Clean_MACByte14 "AES-GCM计算的MAC";
CM_ SG_ 964 Mdc_KeyLearn_Clean_MACByte15 "AES-GCM计算的MAC";
CM_ SG_ 964 Mdc_KeyLearn_Clean_MACByte16 "AES-GCM计算的MAC";
CM_ SG_ 964 Mdc_KeyLearn_Clean_IVByte1 "96bit 的IV";
CM_ SG_ 964 Mdc_KeyLearn_Clean_IVByte2 "96bit 的IV";
CM_ SG_ 964 Mdc_KeyLearn_Clean_IVByte3 "96bit 的IV";
CM_ SG_ 964 Mdc_KeyLearn_Clean_IVByte4 "96bit 的IV";
CM_ SG_ 964 Mdc_KeyLearn_Clean_IVByte5 "96bit 的IV";
CM_ SG_ 964 Mdc_KeyLearn_Clean_IVByte6 "96bit 的IV";
CM_ SG_ 964 Mdc_KeyLearn_Clean_IVByte7 "96bit 的IV";
CM_ SG_ 964 Mdc_KeyLearn_Clean_IVByte8 "96bit 的IV";
CM_ SG_ 964 Mdc_KeyLearn_Clean_IVByte9 "96bit 的IV";
CM_ SG_ 964 Mdc_KeyLearn_Clean_IVByte10 "96bit 的IV";
CM_ SG_ 964 Mdc_KeyLearn_Clean_IVByte11 "96bit 的IV";
CM_ SG_ 964 Mdc_KeyLearn_Clean_IVByte12 "96bit 的IV";
CM_ SG_ 961 Mdc_VerifySubID_Random "MDC发送随机数，此字段携带1";
CM_ SG_ 961 Mdc_Verify_SKID "需要校验的密钥ID";
CM_ SG_ 961 Mdc_Verify_Random "4字节的随机数";
CM_ SG_ 965 Mdc_Verify_ResultID "MDC发送认证成功，此字段携带2";
CM_ SG_ 965 Mdc_Verify_Result_SKID "校验的密钥ID";
CM_ SG_ 656 Point_Priv_0_6_Timestamp "点的timestamp";
CM_ SG_ 656 Point_00_ID "点的ID";
CM_ SG_ 656 Point_00_Valid "点的ID是否无效";
CM_ SG_ 656 Point_00_X "点的X坐标";
CM_ SG_ 656 Point_00_Y "点的Y坐标";
CM_ SG_ 656 Point_00_ErrorA "点的偏差（椭圆长轴）";
CM_ SG_ 656 Point_00_ErrorB "点的偏差（椭圆短轴）";
CM_ SG_ 656 Point_00_ErrorTheta "点的偏差（椭圆角度）
-180~+180°";
CM_ SG_ 656 Point_00_High "点的高低";
CM_ SG_ 656 Point_00_ExistProbability "点的存在概率";
CM_ SG_ 656 Point_01_ID "点的ID";
CM_ SG_ 656 Point_01_Valid "点的ID是否无效";
CM_ SG_ 656 Point_01_X "点的X坐标";
CM_ SG_ 656 Point_01_Y "点的Y坐标";
CM_ SG_ 656 Point_01_ErrorA "点的偏差（椭圆长轴）";
CM_ SG_ 656 Point_01_ErrorB "点的偏差（椭圆短轴）";
CM_ SG_ 656 Point_01_ErrorTheta "点的偏差（椭圆角度）
-180~+180°";
CM_ SG_ 656 Point_01_High "点的高低";
CM_ SG_ 656 Point_01_ExistProbability "点的存在概率";
CM_ SG_ 656 Point_02_ID "点的ID";
CM_ SG_ 656 Point_02_Valid "点的ID是否无效";
CM_ SG_ 656 Point_02_X "点的X坐标";
CM_ SG_ 656 Point_02_Y "点的Y坐标";
CM_ SG_ 656 Point_02_ErrorA "点的偏差（椭圆长轴）";
CM_ SG_ 656 Point_02_ErrorB "点的偏差（椭圆短轴）";
CM_ SG_ 656 Point_02_ErrorTheta "点的偏差（椭圆角度）
-180~+180°";
CM_ SG_ 656 Point_02_High "点的高低";
CM_ SG_ 656 Point_02_ExistProbability "点的存在概率";
CM_ SG_ 656 Point_03_ID "点的ID";
CM_ SG_ 656 Point_03_Valid "点的ID是否无效";
CM_ SG_ 656 Point_03_X "点的X坐标";
CM_ SG_ 656 Point_03_Y "点的Y坐标";
CM_ SG_ 656 Point_03_ErrorA "点的偏差（椭圆长轴）";
CM_ SG_ 656 Point_03_ErrorB "点的偏差（椭圆短轴）";
CM_ SG_ 656 Point_03_ErrorTheta "点的偏差（椭圆角度）
-180~+180°";
CM_ SG_ 656 Point_03_High "点的高低";
CM_ SG_ 656 Point_03_ExistProbability "点的存在概率";
CM_ SG_ 656 Point_04_ID "点的ID";
CM_ SG_ 656 Point_04_Valid "点的ID是否无效";
CM_ SG_ 656 Point_04_X "点的X坐标";
CM_ SG_ 656 Point_04_Y "点的Y坐标";
CM_ SG_ 656 Point_04_ErrorA "点的偏差（椭圆长轴）";
CM_ SG_ 656 Point_04_ErrorB "点的偏差（椭圆短轴）";
CM_ SG_ 656 Point_04_ErrorTheta "点的偏差（椭圆角度）
-180~+180°";
CM_ SG_ 656 Point_04_High "点的高低";
CM_ SG_ 656 Point_04_ExistProbability "点的存在概率";
CM_ SG_ 656 Point_05_ID "点的ID";
CM_ SG_ 656 Point_05_Valid "点的ID是否无效";
CM_ SG_ 656 Point_05_X "点的X坐标";
CM_ SG_ 656 Point_05_Y "点的Y坐标";
CM_ SG_ 656 Point_05_ErrorA "点的偏差（椭圆长轴）";
CM_ SG_ 656 Point_05_ErrorB "点的偏差（椭圆短轴）";
CM_ SG_ 656 Point_05_ErrorTheta "点的偏差（椭圆角度）
-180~+180°";
CM_ SG_ 656 Point_05_High "点的高低";
CM_ SG_ 656 Point_05_ExistProbability "点的存在概率";
CM_ SG_ 656 Point_06_ID "点的ID";
CM_ SG_ 656 Point_06_Valid "点的ID是否无效";
CM_ SG_ 656 Point_06_X "点的X坐标";
CM_ SG_ 656 Point_06_Y "点的Y坐标";
CM_ SG_ 656 Point_06_ErrorA "点的偏差（椭圆长轴）";
CM_ SG_ 656 Point_06_ErrorB "点的偏差（椭圆短轴）";
CM_ SG_ 656 Point_06_ErrorTheta "点的偏差（椭圆角度）
-180~+180°";
CM_ SG_ 656 Point_06_High "点的高低";
CM_ SG_ 656 Point_06_ExistProbability "点的存在概率";
CM_ SG_ 657 Point_Priv_7_13_Timestamp "点的timestamp";
CM_ SG_ 657 Point_07_ID "点的ID";
CM_ SG_ 657 Point_07_Valid "点的ID是否无效";
CM_ SG_ 657 Point_07_X "点的X坐标";
CM_ SG_ 657 Point_07_Y "点的Y坐标";
CM_ SG_ 657 Point_07_ErrorA "点的偏差（椭圆长轴）";
CM_ SG_ 657 Point_07_ErrorB "点的偏差（椭圆短轴）";
CM_ SG_ 657 Point_07_ErrorTheta "点的偏差（椭圆角度）
-180~+180°";
CM_ SG_ 657 Point_07_High "点的高低";
CM_ SG_ 657 Point_07_ExistProbability "点的存在概率";
CM_ SG_ 657 Point_08_ID "点的ID";
CM_ SG_ 657 Point_08_Valid "点的ID是否无效";
CM_ SG_ 657 Point_08_X "点的X坐标";
CM_ SG_ 657 Point_08_Y "点的Y坐标";
CM_ SG_ 657 Point_08_ErrorA "点的偏差（椭圆长轴）";
CM_ SG_ 657 Point_08_ErrorB "点的偏差（椭圆短轴）";
CM_ SG_ 657 Point_08_ErrorTheta "点的偏差（椭圆角度）
-180~+180°";
CM_ SG_ 657 Point_08_High "点的高低";
CM_ SG_ 657 Point_08_ExistProbability "点的存在概率";
CM_ SG_ 657 Point_09_ID "点的ID";
CM_ SG_ 657 Point_09_Valid "点的ID是否无效";
CM_ SG_ 657 Point_09_X "点的X坐标";
CM_ SG_ 657 Point_09_Y "点的Y坐标";
CM_ SG_ 657 Point_09_ErrorA "点的偏差（椭圆长轴）";
CM_ SG_ 657 Point_09_ErrorB "点的偏差（椭圆短轴）";
CM_ SG_ 657 Point_09_ErrorTheta "点的偏差（椭圆角度）
-180~+180°";
CM_ SG_ 657 Point_09_High "点的高低";
CM_ SG_ 657 Point_09_ExistProbability "点的存在概率";
CM_ SG_ 657 Point_10_ID "点的ID";
CM_ SG_ 657 Point_10_Valid "点的ID是否无效";
CM_ SG_ 657 Point_10_X "点的X坐标";
CM_ SG_ 657 Point_10_Y "点的Y坐标";
CM_ SG_ 657 Point_10_ErrorA "点的偏差（椭圆长轴）";
CM_ SG_ 657 Point_10_ErrorB "点的偏差（椭圆短轴）";
CM_ SG_ 657 Point_10_ErrorTheta "点的偏差（椭圆角度）
-180~+180°";
CM_ SG_ 657 Point_10_High "点的高低";
CM_ SG_ 657 Point_10_ExistProbability "点的存在概率";
CM_ SG_ 657 Point_11_ID "点的ID";
CM_ SG_ 657 Point_11_Valid "点的ID是否无效";
CM_ SG_ 657 Point_11_X "点的X坐标";
CM_ SG_ 657 Point_11_Y "点的Y坐标";
CM_ SG_ 657 Point_11_ErrorA "点的偏差（椭圆长轴）";
CM_ SG_ 657 Point_11_ErrorB "点的偏差（椭圆短轴）";
CM_ SG_ 657 Point_11_ErrorTheta "点的偏差（椭圆角度）
-180~+180°";
CM_ SG_ 657 Point_11_High "点的高低";
CM_ SG_ 657 Point_11_ExistProbability "点的存在概率";
CM_ SG_ 657 Point_12_ID "点的ID";
CM_ SG_ 657 Point_12_Valid "点的ID是否无效";
CM_ SG_ 657 Point_12_X "点的X坐标";
CM_ SG_ 657 Point_12_Y "点的Y坐标";
CM_ SG_ 657 Point_12_ErrorA "点的偏差（椭圆长轴）";
CM_ SG_ 657 Point_12_ErrorB "点的偏差（椭圆短轴）";
CM_ SG_ 657 Point_12_ErrorTheta "点的偏差（椭圆角度）
-180~+180°";
CM_ SG_ 657 Point_12_High "点的高低";
CM_ SG_ 657 Point_12_ExistProbability "点的存在概率";
CM_ SG_ 657 Point_13_ID "点的ID";
CM_ SG_ 657 Point_13_Valid "点的ID是否无效";
CM_ SG_ 657 Point_13_X "点的X坐标";
CM_ SG_ 657 Point_13_Y "点的Y坐标";
CM_ SG_ 657 Point_13_ErrorA "点的偏差（椭圆长轴）";
CM_ SG_ 657 Point_13_ErrorB "点的偏差（椭圆短轴）";
CM_ SG_ 657 Point_13_ErrorTheta "点的偏差（椭圆角度）
-180~+180°";
CM_ SG_ 657 Point_13_High "点的高低";
CM_ SG_ 657 Point_13_ExistProbability "点的存在概率";
CM_ SG_ 658 Point_Priv_14_20_Timestamp "点的timestamp";
CM_ SG_ 658 Point_14_ID "点的ID";
CM_ SG_ 658 Point_14_Valid "点的ID是否无效";
CM_ SG_ 658 Point_14_X "点的X坐标";
CM_ SG_ 658 Point_14_Y "点的Y坐标";
CM_ SG_ 658 Point_14_ErrorA "点的偏差（椭圆长轴）";
CM_ SG_ 658 Point_14_ErrorB "点的偏差（椭圆短轴）";
CM_ SG_ 658 Point_14_ErrorTheta "点的偏差（椭圆角度）
-180~+180°";
CM_ SG_ 658 Point_14_High "点的高低";
CM_ SG_ 658 Point_14_ExistProbability "点的存在概率";
CM_ SG_ 658 Point_15_ID "点的ID";
CM_ SG_ 658 Point_15_Valid "点的ID是否无效";
CM_ SG_ 658 Point_15_X "点的X坐标";
CM_ SG_ 658 Point_15_Y "点的Y坐标";
CM_ SG_ 658 Point_15_ErrorA "点的偏差（椭圆长轴）";
CM_ SG_ 658 Point_15_ErrorB "点的偏差（椭圆短轴）";
CM_ SG_ 658 Point_15_ErrorTheta "点的偏差（椭圆角度）
-180~+180°";
CM_ SG_ 658 Point_15_High "点的高低";
CM_ SG_ 658 Point_15_ExistProbability "点的存在概率";
CM_ SG_ 658 Point_16_ID "点的ID";
CM_ SG_ 658 Point_16_Valid "点的ID是否无效";
CM_ SG_ 658 Point_16_X "点的X坐标";
CM_ SG_ 658 Point_16_Y "点的Y坐标";
CM_ SG_ 658 Point_16_ErrorA "点的偏差（椭圆长轴）";
CM_ SG_ 658 Point_16_ErrorB "点的偏差（椭圆短轴）";
CM_ SG_ 658 Point_16_ErrorTheta "点的偏差（椭圆角度）
-180~+180°";
CM_ SG_ 658 Point_16_High "点的高低";
CM_ SG_ 658 Point_16_ExistProbability "点的存在概率";
CM_ SG_ 658 Point_17_ID "点的ID";
CM_ SG_ 658 Point_17_Valid "点的ID是否无效";
CM_ SG_ 658 Point_17_X "点的X坐标";
CM_ SG_ 658 Point_17_Y "点的Y坐标";
CM_ SG_ 658 Point_17_ErrorA "点的偏差（椭圆长轴）";
CM_ SG_ 658 Point_17_ErrorB "点的偏差（椭圆短轴）";
CM_ SG_ 658 Point_17_ErrorTheta "点的偏差（椭圆角度）
-180~+180°";
CM_ SG_ 658 Point_17_High "点的高低";
CM_ SG_ 658 Point_17_ExistProbability "点的存在概率";
CM_ SG_ 658 Point_18_ID "点的ID";
CM_ SG_ 658 Point_18_Valid "点的ID是否无效";
CM_ SG_ 658 Point_18_X "点的X坐标";
CM_ SG_ 658 Point_18_Y "点的Y坐标";
CM_ SG_ 658 Point_18_ErrorA "点的偏差（椭圆长轴）";
CM_ SG_ 658 Point_18_ErrorB "点的偏差（椭圆短轴）";
CM_ SG_ 658 Point_18_ErrorTheta "点的偏差（椭圆角度）
-180~+180°";
CM_ SG_ 658 Point_18_High "点的高低";
CM_ SG_ 658 Point_18_ExistProbability "点的存在概率";
CM_ SG_ 658 Point_19_ID "点的ID";
CM_ SG_ 658 Point_19_Valid "点的ID是否无效";
CM_ SG_ 658 Point_19_X "点的X坐标";
CM_ SG_ 658 Point_19_Y "点的Y坐标";
CM_ SG_ 658 Point_19_ErrorA "点的偏差（椭圆长轴）";
CM_ SG_ 658 Point_19_ErrorB "点的偏差（椭圆短轴）";
CM_ SG_ 658 Point_19_ErrorTheta "点的偏差（椭圆角度）
-180~+180°";
CM_ SG_ 658 Point_19_High "点的高低";
CM_ SG_ 658 Point_19_ExistProbability "点的存在概率";
CM_ SG_ 658 Point_20_ID "点的ID";
CM_ SG_ 658 Point_20_Valid "点的ID是否无效";
CM_ SG_ 658 Point_20_X "点的X坐标";
CM_ SG_ 658 Point_20_Y "点的Y坐标";
CM_ SG_ 658 Point_20_ErrorA "点的偏差（椭圆长轴）";
CM_ SG_ 658 Point_20_ErrorB "点的偏差（椭圆短轴）";
CM_ SG_ 658 Point_20_ErrorTheta "点的偏差（椭圆角度）
-180~+180°";
CM_ SG_ 658 Point_20_High "点的高低";
CM_ SG_ 658 Point_20_ExistProbability "点的存在概率";
BA_DEF_  "NmAsrMessageCount" INT 0 255;
BA_DEF_ BU_  "NodeLayerModules" STRING ;
BA_DEF_ BU_  "NmAsrNode" ENUM  "No","Yes";
BA_DEF_ BU_  "ILUsed" ENUM  "No","Yes";
BA_DEF_  "Manufacturer" STRING ;
BA_DEF_ BO_  "GenMsgNrOfRepetition" INT 0 255;
BA_DEF_ BO_  "GenMsgILSupport" ENUM  "No","Yes";
BA_DEF_ BO_  "GenMsgFastOnStart" INT 0 65535;
BA_DEF_ BO_  "DiagState" ENUM  "No","Yes";
BA_DEF_ BO_  "DiagResponse" ENUM  "No","Yes";
BA_DEF_ BO_  "DiagRequest" ENUM  "No","Yes";
BA_DEF_ BO_  "DiagFdOnly" ENUM  "No","Yes";
BA_DEF_ BO_  "CANFD_BRS" ENUM  "0","1";
BA_DEF_ BO_  "GenMsgSendType" ENUM  "Cycle","Event","CE","IfActive","NoMsgSendType";
BA_DEF_ BO_  "GenMsgCycleTime" INT 0 65535;
BA_DEF_ SG_  "GenSigSendType" ENUM  "Cycle","OnChange","OnWrite","IfActive","OnChangeWithRepetition","OnWriteWithRepetition","IfActiveWithRepetition";
BA_DEF_ SG_  "GenSigStartValue" INT 0 2147483647;
BA_DEF_  "BusType" STRING ;
BA_DEF_ BO_  "VFrameFormat" ENUM  "StandardCAN","ExtendedCAN","reserved","reserved","reserved","reserved","reserved","reserved","reserved","reserved","reserved","reserved","reserved","reserved","StandardCAN_FD","ExtendedCAN_FD";
BA_DEF_DEF_  "NmAsrMessageCount" 64;
BA_DEF_DEF_  "NodeLayerModules" "CANoeILNLVector.dll";
BA_DEF_DEF_  "NmAsrNode" "No";
BA_DEF_DEF_  "ILUsed" "Yes";
BA_DEF_DEF_  "Manufacturer" "EH3";
BA_DEF_DEF_  "GenMsgNrOfRepetition" 0;
BA_DEF_DEF_  "GenMsgILSupport" "Yes";
BA_DEF_DEF_  "GenMsgFastOnStart" 0;
BA_DEF_DEF_  "DiagState" "No";
BA_DEF_DEF_  "DiagResponse" "No";
BA_DEF_DEF_  "DiagRequest" "No";
BA_DEF_DEF_  "DiagFdOnly" "No";
BA_DEF_DEF_  "CANFD_BRS" "1";
BA_DEF_DEF_  "GenMsgSendType" "Cycle";
BA_DEF_DEF_  "GenMsgCycleTime" 0;
BA_DEF_DEF_  "GenSigSendType" "Cycle";
BA_DEF_DEF_  "GenSigStartValue" 0;
BA_DEF_DEF_  "BusType" "CAN FD";
BA_DEF_DEF_  "VFrameFormat" "";
BA_ "NmAsrNode" BU_ MDC 1;
BA_ "NmAsrNode" BU_ PAS 1;
BA_ "GenMsgSendType" BO_ 773 4;
BA_ "VFrameFormat" BO_ 773 14;
BA_ "GenMsgFastOnStart" BO_ 1694 20;
BA_ "GenMsgSendType" BO_ 1694 4;
BA_ "VFrameFormat" BO_ 1694 14;
BA_ "GenMsgFastOnStart" BO_ 1693 20;
BA_ "GenMsgSendType" BO_ 1693 4;
BA_ "VFrameFormat" BO_ 1693 14;
BA_ "GenMsgFastOnStart" BO_ 1692 20;
BA_ "GenMsgSendType" BO_ 1692 4;
BA_ "VFrameFormat" BO_ 1692 14;
BA_ "GenMsgFastOnStart" BO_ 1691 20;
BA_ "GenMsgSendType" BO_ 1691 4;
BA_ "VFrameFormat" BO_ 1691 14;
BA_ "GenMsgFastOnStart" BO_ 1690 20;
BA_ "GenMsgSendType" BO_ 1690 4;
BA_ "VFrameFormat" BO_ 1690 14;
BA_ "GenMsgFastOnStart" BO_ 1689 20;
BA_ "GenMsgSendType" BO_ 1689 4;
BA_ "VFrameFormat" BO_ 1689 14;
BA_ "GenMsgFastOnStart" BO_ 1688 20;
BA_ "GenMsgSendType" BO_ 1688 4;
BA_ "VFrameFormat" BO_ 1688 14;
BA_ "GenMsgFastOnStart" BO_ 1687 20;
BA_ "GenMsgSendType" BO_ 1687 4;
BA_ "VFrameFormat" BO_ 1687 14;
BA_ "GenMsgFastOnStart" BO_ 1686 20;
BA_ "GenMsgSendType" BO_ 1686 4;
BA_ "VFrameFormat" BO_ 1686 14;
BA_ "GenMsgFastOnStart" BO_ 1685 20;
BA_ "GenMsgSendType" BO_ 1685 4;
BA_ "VFrameFormat" BO_ 1685 14;
BA_ "GenMsgFastOnStart" BO_ 1684 20;
BA_ "GenMsgSendType" BO_ 1684 4;
BA_ "VFrameFormat" BO_ 1684 14;
BA_ "GenMsgFastOnStart" BO_ 1683 20;
BA_ "GenMsgSendType" BO_ 1683 4;
BA_ "VFrameFormat" BO_ 1683 14;
BA_ "GenMsgFastOnStart" BO_ 1682 20;
BA_ "GenMsgSendType" BO_ 1682 4;
BA_ "VFrameFormat" BO_ 1682 14;
BA_ "GenMsgFastOnStart" BO_ 1681 20;
BA_ "GenMsgSendType" BO_ 1681 4;
BA_ "VFrameFormat" BO_ 1681 14;
BA_ "GenMsgFastOnStart" BO_ 1680 20;
BA_ "GenMsgSendType" BO_ 1680 4;
BA_ "VFrameFormat" BO_ 1680 14;
BA_ "GenMsgSendType" BO_ 2024 4;
BA_ "DiagFdOnly" BO_ 2024 1;
BA_ "DiagResponse" BO_ 2024 1;
BA_ "GenMsgILSupport" BO_ 2024 0;
BA_ "VFrameFormat" BO_ 2024 14;
BA_ "GenMsgSendType" BO_ 2016 4;
BA_ "DiagFdOnly" BO_ 2016 1;
BA_ "DiagRequest" BO_ 2016 1;
BA_ "GenMsgILSupport" BO_ 2016 0;
BA_ "VFrameFormat" BO_ 2016 14;
BA_ "DiagFdOnly" BO_ 2015 1;
BA_ "GenMsgSendType" BO_ 2015 4;
BA_ "DiagState" BO_ 2015 1;
BA_ "GenMsgILSupport" BO_ 2015 0;
BA_ "VFrameFormat" BO_ 2015 14;
BA_ "GenMsgCycleTime" BO_ 513 20;
BA_ "VFrameFormat" BO_ 513 14;
BA_ "GenMsgCycleTime" BO_ 514 20;
BA_ "VFrameFormat" BO_ 514 14;
BA_ "GenMsgCycleTime" BO_ 515 20;
BA_ "VFrameFormat" BO_ 515 14;
BA_ "GenMsgCycleTime" BO_ 517 20;
BA_ "VFrameFormat" BO_ 517 14;
BA_ "GenMsgSendType" BO_ 544 4;
BA_ "VFrameFormat" BO_ 544 14;
BA_ "GenMsgCycleTime" BO_ 560 40;
BA_ "VFrameFormat" BO_ 560 14;
BA_ "GenMsgCycleTime" BO_ 576 1000;
BA_ "VFrameFormat" BO_ 576 14;
BA_ "GenMsgSendType" BO_ 592 1;
BA_ "VFrameFormat" BO_ 592 14;
BA_ "GenMsgCycleTime" BO_ 593 500;
BA_ "VFrameFormat" BO_ 593 14;
BA_ "GenMsgSendType" BO_ 672 1;
BA_ "VFrameFormat" BO_ 672 14;
BA_ "GenMsgSendType" BO_ 673 1;
BA_ "VFrameFormat" BO_ 673 14;
BA_ "GenMsgSendType" BO_ 674 1;
BA_ "VFrameFormat" BO_ 674 14;
BA_ "GenMsgSendType" BO_ 706 1;
BA_ "VFrameFormat" BO_ 706 14;
BA_ "GenMsgSendType" BO_ 708 1;
BA_ "VFrameFormat" BO_ 708 14;
BA_ "GenMsgSendType" BO_ 707 1;
BA_ "VFrameFormat" BO_ 707 14;
BA_ "GenMsgCycleTime" BO_ 640 20;
BA_ "VFrameFormat" BO_ 640 14;
BA_ "GenMsgCycleTime" BO_ 641 40;
BA_ "VFrameFormat" BO_ 641 14;
BA_ "GenMsgCycleTime" BO_ 642 20;
BA_ "VFrameFormat" BO_ 642 14;
BA_ "GenMsgCycleTime" BO_ 768 1000;
BA_ "VFrameFormat" BO_ 768 14;
BA_ "GenMsgCycleTime" BO_ 769 20;
BA_ "VFrameFormat" BO_ 769 14;
BA_ "GenMsgSendType" BO_ 770 1;
BA_ "VFrameFormat" BO_ 770 14;
BA_ "GenMsgSendType" BO_ 771 1;
BA_ "VFrameFormat" BO_ 771 14;
BA_ "GenMsgCycleTime" BO_ 772 500;
BA_ "GenMsgILSupport" BO_ 772 0;
BA_ "VFrameFormat" BO_ 772 14;
BA_ "GenMsgSendType" BO_ 928 1;
BA_ "VFrameFormat" BO_ 928 14;
BA_ "GenMsgSendType" BO_ 929 1;
BA_ "VFrameFormat" BO_ 929 14;
BA_ "GenMsgSendType" BO_ 960 1;
BA_ "VFrameFormat" BO_ 960 14;
BA_ "GenMsgSendType" BO_ 962 1;
BA_ "VFrameFormat" BO_ 962 14;
BA_ "GenMsgSendType" BO_ 963 1;
BA_ "VFrameFormat" BO_ 963 14;
BA_ "GenMsgSendType" BO_ 964 1;
BA_ "VFrameFormat" BO_ 964 14;
BA_ "GenMsgSendType" BO_ 961 1;
BA_ "VFrameFormat" BO_ 961 14;
BA_ "GenMsgSendType" BO_ 965 1;
BA_ "VFrameFormat" BO_ 965 14;
BA_ "GenMsgCycleTime" BO_ 656 40;
BA_ "VFrameFormat" BO_ 656 14;
BA_ "GenMsgCycleTime" BO_ 657 40;
BA_ "VFrameFormat" BO_ 657 14;
BA_ "GenMsgCycleTime" BO_ 658 40;
BA_ "VFrameFormat" BO_ 658 14;
BA_ "GenSigSendType" SG_ 773 sensorVersion 1;
BA_ "GenSigSendType" SG_ 1694 P2_ZPY2_CANFD_14 1;
BA_ "GenSigSendType" SG_ 1693 P2_ZPY2_CANFD_13 1;
BA_ "GenSigSendType" SG_ 1692 P2_ZPY2_CANFD_12 1;
BA_ "GenSigSendType" SG_ 1691 P2_ZPY2_CANFD_11 1;
BA_ "GenSigSendType" SG_ 1690 P2_ZPY2_CANFD_10 1;
BA_ "GenSigSendType" SG_ 1689 P2_ZPY2_CANFD_9 1;
BA_ "GenSigSendType" SG_ 1688 P2_ZPY2_CANFD_8 1;
BA_ "GenSigSendType" SG_ 1687 P2_ZPY2_CANFD_7 1;
BA_ "GenSigSendType" SG_ 1686 P2_ZPY2_CANFD_6 1;
BA_ "GenSigSendType" SG_ 1685 P2_ZPY2_CANFD_5 1;
BA_ "GenSigSendType" SG_ 1684 P2_ZPY2_CANFD_4 1;
BA_ "GenSigSendType" SG_ 1683 P2_ZPY2_CANFD_3 1;
BA_ "GenSigSendType" SG_ 1682 P2_ZPY2_CANFD_2 1;
BA_ "GenSigSendType" SG_ 1681 P2_ZPY2_CANFD_1 1;
BA_ "GenSigSendType" SG_ 1680 P2_ZPY2_CANFD_0 1;
BA_ "GenSigStartValue" SG_ 544 PAS_WakeUp_Response 1;
BA_ "GenSigSendType" SG_ 672 PAS_Device_Vertify_Times 1;
BA_ "GenSigSendType" SG_ 672 PAS_Device_Vertify_Status 1;
BA_ "GenSigSendType" SG_ 673 PAS_RandomByte1 1;
BA_ "GenSigSendType" SG_ 673 PAS_RandomByte2 1;
BA_ "GenSigSendType" SG_ 673 PAS_RandomByte3 1;
BA_ "GenSigSendType" SG_ 673 PAS_RandomByte4 1;
BA_ "GenSigSendType" SG_ 673 PAS_RandomByte5 1;
BA_ "GenSigSendType" SG_ 673 PAS_RandomByte6 1;
BA_ "GenSigSendType" SG_ 673 PAS_RandomByte7 1;
BA_ "GenSigSendType" SG_ 673 PAS_RandomByte8 1;
BA_ "GenSigSendType" SG_ 673 PAS_SessionID 1;
BA_ "GenSigSendType" SG_ 674 PAS_Verification_Result 1;
BA_ "GenSigSendType" SG_ 674 PAS_SessionID 1;
BA_ "GenSigSendType" SG_ 674 PAS_CMACByte1 1;
BA_ "GenSigSendType" SG_ 674 PAS_CMACByte2 1;
BA_ "GenSigSendType" SG_ 674 PAS_CMACByte3 1;
BA_ "GenSigSendType" SG_ 674 PAS_CMACByte4 1;
BA_ "GenSigSendType" SG_ 674 PAS_CMACByte5 1;
BA_ "GenSigSendType" SG_ 674 PAS_CMACByte6 1;
BA_ "GenSigSendType" SG_ 674 PAS_CMACByte7 1;
BA_ "GenSigSendType" SG_ 674 PAS_CMACByte8 1;
BA_ "GenSigSendType" SG_ 706 PAS_Key_Learn_SubID 1;
BA_ "GenSigStartValue" SG_ 706 PAS_Key_Learn_Numbers 1;
BA_ "GenSigSendType" SG_ 706 PAS_Key_Learn_Numbers 1;
BA_ "GenSigStartValue" SG_ 706 PAS_SKID1 1;
BA_ "GenSigSendType" SG_ 706 PAS_SKID1 1;
BA_ "GenSigSendType" SG_ 706 PAS_SK_Learn_Status1 1;
BA_ "GenSigStartValue" SG_ 706 PAS_SKID2 1;
BA_ "GenSigSendType" SG_ 706 PAS_SKID2 1;
BA_ "GenSigSendType" SG_ 706 PAS_SK_Learn_Status2 1;
BA_ "GenSigStartValue" SG_ 706 PAS_SKID3 1;
BA_ "GenSigSendType" SG_ 706 PAS_SKID3 1;
BA_ "GenSigSendType" SG_ 706 PAS_SK_Learn_Status3 1;
BA_ "GenSigStartValue" SG_ 706 PAS_SKID4 1;
BA_ "GenSigSendType" SG_ 706 PAS_SKID4 1;
BA_ "GenSigSendType" SG_ 706 PAS_SK_Learn_Status4 1;
BA_ "GenSigStartValue" SG_ 706 PAS_SKID5 1;
BA_ "GenSigSendType" SG_ 706 PAS_SKID5 1;
BA_ "GenSigSendType" SG_ 706 PAS_SK_Learn_Status5 1;
BA_ "GenSigStartValue" SG_ 706 PAS_SKID6 1;
BA_ "GenSigSendType" SG_ 706 PAS_SKID6 1;
BA_ "GenSigSendType" SG_ 706 PAS_SK_Learn_Status6 1;
BA_ "GenSigStartValue" SG_ 706 PAS_SKID7 1;
BA_ "GenSigSendType" SG_ 706 PAS_SKID7 1;
BA_ "GenSigSendType" SG_ 706 PAS_SK_Learn_Status7 1;
BA_ "GenSigStartValue" SG_ 706 PAS_SKID8 1;
BA_ "GenSigSendType" SG_ 706 PAS_SKID8 1;
BA_ "GenSigSendType" SG_ 706 PAS_SK_Learn_Status8 1;
BA_ "GenSigStartValue" SG_ 706 PAS_SKID9 1;
BA_ "GenSigSendType" SG_ 706 PAS_SKID9 1;
BA_ "GenSigSendType" SG_ 706 PAS_SK_Learn_Status9 1;
BA_ "GenSigStartValue" SG_ 706 PAS_SKID10 1;
BA_ "GenSigSendType" SG_ 706 PAS_SKID10 1;
BA_ "GenSigSendType" SG_ 706 PAS_SK_Learn_Status10 1;
BA_ "GenSigStartValue" SG_ 706 PAS_SKID11 1;
BA_ "GenSigSendType" SG_ 706 PAS_SKID11 1;
BA_ "GenSigSendType" SG_ 706 PAS_SK_Learn_Status11 1;
BA_ "GenSigStartValue" SG_ 706 PAS_SKID12 1;
BA_ "GenSigSendType" SG_ 706 PAS_SKID12 1;
BA_ "GenSigSendType" SG_ 706 PAS_SK_Learn_Status12 1;
BA_ "GenSigSendType" SG_ 708 PASKeyLearnSubIDSettingResponse 1;
BA_ "GenSigStartValue" SG_ 708 PAS_SK_Setting_Response 1;
BA_ "GenSigSendType" SG_ 708 PAS_SK_Setting_Response 1;
BA_ "GenSigSendType" SG_ 708 PAS_SK_Setting_Status 1;
BA_ "GenSigSendType" SG_ 707 PAS_VerifySubID 1;
BA_ "GenSigStartValue" SG_ 707 PAS_Verify_SKID 1;
BA_ "GenSigSendType" SG_ 707 PAS_Verify_SKID 1;
BA_ "GenSigSendType" SG_ 707 PAS_Verify_AES_Result 1;
BA_ "GenSigSendType" SG_ 707 PAS_Verify_MACbyte1 1;
BA_ "GenSigSendType" SG_ 707 PAS_Verify_MACbyte2 1;
BA_ "GenSigSendType" SG_ 707 PAS_Verify_MACbyte3 1;
BA_ "GenSigSendType" SG_ 707 PAS_Verify_MACbyte4 1;
BA_ "GenSigSendType" SG_ 707 PAS_Verify_MACbyte5 1;
BA_ "GenSigSendType" SG_ 707 PAS_Verify_MACbyte6 1;
BA_ "GenSigSendType" SG_ 707 PAS_Verify_MACbyte7 1;
BA_ "GenSigSendType" SG_ 707 PAS_Verify_MACbyte8 1;
BA_ "GenSigSendType" SG_ 707 PAS_Verify_MACbyte9 1;
BA_ "GenSigSendType" SG_ 707 PAS_Verify_MACbyte10 1;
BA_ "GenSigSendType" SG_ 707 PAS_Verify_MACbyte11 1;
BA_ "GenSigSendType" SG_ 707 PAS_Verify_MACbyte12 1;
BA_ "GenSigSendType" SG_ 707 PAS_Verify_MACbyte13 1;
BA_ "GenSigSendType" SG_ 707 PAS_Verify_MACbyte14 1;
BA_ "GenSigSendType" SG_ 707 PAS_Verify_MACbyte15 1;
BA_ "GenSigSendType" SG_ 707 PAS_Verify_MACbyte16 1;
BA_ "GenSigSendType" SG_ 707 PAS_Verify_IVByte1 1;
BA_ "GenSigSendType" SG_ 707 PAS_Verify_IVByte2 1;
BA_ "GenSigSendType" SG_ 707 PAS_Verify_IVByte3 1;
BA_ "GenSigSendType" SG_ 707 PAS_Verify_IVByte4 1;
BA_ "GenSigSendType" SG_ 707 PAS_Verify_IVByte5 1;
BA_ "GenSigSendType" SG_ 707 PAS_Verify_IVByte6 1;
BA_ "GenSigSendType" SG_ 707 PAS_Verify_IVByte7 1;
BA_ "GenSigSendType" SG_ 707 PAS_Verify_IVByte8 1;
BA_ "GenSigSendType" SG_ 707 PAS_Verify_IVByte9 1;
BA_ "GenSigSendType" SG_ 707 PAS_Verify_IVByte10 1;
BA_ "GenSigSendType" SG_ 707 PAS_Verify_IVByte11 1;
BA_ "GenSigSendType" SG_ 707 PAS_Verify_IVByte12 1;
BA_ "GenSigStartValue" SG_ 769 YawRate 30000;
BA_ "GenSigSendType" SG_ 770 PAS_Sonar1_Req 1;
BA_ "GenSigSendType" SG_ 770 PAS_Sonar1_Req_counter 1;
BA_ "GenSigSendType" SG_ 770 PAS_Sonar2_Req 1;
BA_ "GenSigSendType" SG_ 770 PAS_Sonar2_Req_counter 1;
BA_ "GenSigSendType" SG_ 770 PAS_Sonar3_Req 1;
BA_ "GenSigSendType" SG_ 770 PAS_Sonar3_Req_counter 1;
BA_ "GenSigSendType" SG_ 770 PAS_Sonar4_Req 1;
BA_ "GenSigSendType" SG_ 770 PAS_Sonar4_Req_counter 1;
BA_ "GenSigSendType" SG_ 770 PAS_Sonar7_Req 1;
BA_ "GenSigSendType" SG_ 770 PAS_Sonar7_Req_counter 1;
BA_ "GenSigSendType" SG_ 770 PAS_Sonar8_Req 1;
BA_ "GenSigSendType" SG_ 770 PAS_Sonar8_Req_counter 1;
BA_ "GenSigSendType" SG_ 770 PAS_Sonar9_Req 1;
BA_ "GenSigSendType" SG_ 770 PAS_Sonar9_Req_counter 1;
BA_ "GenSigSendType" SG_ 770 PAS_Sonar10_Req 1;
BA_ "GenSigSendType" SG_ 770 PAS_Sonar10_Req_counter 1;
BA_ "GenSigSendType" SG_ 770 PAS_Sonar0_Req 1;
BA_ "GenSigSendType" SG_ 770 PAS_Sonar0_Req_counter 1;
BA_ "GenSigSendType" SG_ 770 PAS_Sonar5_Req 1;
BA_ "GenSigSendType" SG_ 770 PAS_Sonar5_Req_counter 1;
BA_ "GenSigSendType" SG_ 770 PAS_Sonar6_Req 1;
BA_ "GenSigSendType" SG_ 770 PAS_Sonar6_Req_counter 1;
BA_ "GenSigSendType" SG_ 770 PAS_Sonar11_Req 1;
BA_ "GenSigSendType" SG_ 770 PAS_Sonar11_Req_counter 1;
BA_ "GenSigSendType" SG_ 770 Sonar_Req_RollingCounter 1;
BA_ "GenSigSendType" SG_ 770 Sonar_Req_Checksum 1;
BA_ "GenSigSendType" SG_ 770 MSG302_Fill4bit 1;
BA_ "GenSigSendType" SG_ 770 PAS_Function_Req 1;
BA_ "GenSigSendType" SG_ 771 Ack_Alarm_Id 1;
BA_ "GenSigSendType" SG_ 771 Ack_Alarm_State 1;
BA_ "GenSigSendType" SG_ 771 Ack_Alarm_Level 1;
BA_ "GenSigSendType" SG_ 771 Ack_Transaction_Id 1;
BA_ "GenSigSendType" SG_ 771 Ack_Alarm_Checksum 1;
BA_ "GenSigSendType" SG_ 771 Ack_Alarm_RollingCounter 1;
BA_ "GenSigSendType" SG_ 771 MSG303_Fill4bit 1;
BA_ "GenSigSendType" SG_ 928 MDC_RandomByte1 1;
BA_ "GenSigSendType" SG_ 928 MDC_RandomByte2 1;
BA_ "GenSigSendType" SG_ 928 MDC_RandomByte3 1;
BA_ "GenSigSendType" SG_ 928 MDC_RandomByte4 1;
BA_ "GenSigSendType" SG_ 928 MDC_RandomByte5 1;
BA_ "GenSigSendType" SG_ 928 MDC_RandomByte6 1;
BA_ "GenSigSendType" SG_ 928 MDC_RandomByte7 1;
BA_ "GenSigSendType" SG_ 928 MDC_RandomByte8 1;
BA_ "GenSigSendType" SG_ 928 MDC_SessionID 1;
BA_ "GenSigSendType" SG_ 929 MDC_Response_Result 1;
BA_ "GenSigSendType" SG_ 929 MDC_Response_SessionID 1;
BA_ "GenSigSendType" SG_ 929 MDC_Response_CMACByte1 1;
BA_ "GenSigSendType" SG_ 929 MDC_Response_CMACByte2 1;
BA_ "GenSigSendType" SG_ 929 MDC_Response_CMACByte3 1;
BA_ "GenSigSendType" SG_ 929 MDC_Response_CMACByte4 1;
BA_ "GenSigSendType" SG_ 929 MDC_Response_CMACByte5 1;
BA_ "GenSigSendType" SG_ 929 MDC_Response_CMACByte6 1;
BA_ "GenSigSendType" SG_ 929 MDC_Response_CMACByte7 1;
BA_ "GenSigSendType" SG_ 929 MDC_Response_CMACByte8 1;
BA_ "GenSigSendType" SG_ 960 Mdc_KeyLearnSubID 1;
BA_ "GenSigStartValue" SG_ 960 Mdc_KeyLearn_Numbers 1;
BA_ "GenSigSendType" SG_ 960 Mdc_KeyLearn_Numbers 1;
BA_ "GenSigStartValue" SG_ 960 Mdc_KeyLearn_SKID1 1;
BA_ "GenSigSendType" SG_ 960 Mdc_KeyLearn_SKID1 1;
BA_ "GenSigStartValue" SG_ 960 Mdc_KeyLearn_SKID2 1;
BA_ "GenSigSendType" SG_ 960 Mdc_KeyLearn_SKID2 1;
BA_ "GenSigStartValue" SG_ 960 Mdc_KeyLearn_SKID3 1;
BA_ "GenSigSendType" SG_ 960 Mdc_KeyLearn_SKID3 1;
BA_ "GenSigStartValue" SG_ 960 Mdc_KeyLearn_SKID4 1;
BA_ "GenSigSendType" SG_ 960 Mdc_KeyLearn_SKID4 1;
BA_ "GenSigStartValue" SG_ 960 Mdc_KeyLearn_SKID5 1;
BA_ "GenSigSendType" SG_ 960 Mdc_KeyLearn_SKID5 1;
BA_ "GenSigStartValue" SG_ 960 Mdc_KeyLearn_SKID6 1;
BA_ "GenSigSendType" SG_ 960 Mdc_KeyLearn_SKID6 1;
BA_ "GenSigStartValue" SG_ 960 Mdc_KeyLearn_SKID7 1;
BA_ "GenSigSendType" SG_ 960 Mdc_KeyLearn_SKID7 1;
BA_ "GenSigStartValue" SG_ 960 Mdc_KeyLearn_SKID8 1;
BA_ "GenSigSendType" SG_ 960 Mdc_KeyLearn_SKID8 1;
BA_ "GenSigStartValue" SG_ 960 Mdc_KeyLearn_SKID9 1;
BA_ "GenSigSendType" SG_ 960 Mdc_KeyLearn_SKID9 1;
BA_ "GenSigStartValue" SG_ 960 Mdc_KeyLearn_SKID10 1;
BA_ "GenSigSendType" SG_ 960 Mdc_KeyLearn_SKID10 1;
BA_ "GenSigStartValue" SG_ 960 Mdc_KeyLearn_SKID11 1;
BA_ "GenSigSendType" SG_ 960 Mdc_KeyLearn_SKID11 1;
BA_ "GenSigStartValue" SG_ 960 Mdc_KeyLearn_SKID12 1;
BA_ "GenSigSendType" SG_ 960 Mdc_KeyLearn_SKID12 1;
BA_ "GenSigSendType" SG_ 962 Mdc_KeyLearnSubID_Send 1;
BA_ "GenSigStartValue" SG_ 962 Mdc_KeyLearn_transmit_SKID 1;
BA_ "GenSigSendType" SG_ 962 Mdc_KeyLearn_transmit_SKID 1;
BA_ "GenSigStartValue" SG_ 962 Mdc_KeyLearn_update_SKID 1;
BA_ "GenSigSendType" SG_ 962 Mdc_KeyLearn_update_SKID 1;
BA_ "GenSigSendType" SG_ 962 Mdc_KeyLearn_SKCByte1 1;
BA_ "GenSigSendType" SG_ 962 Mdc_KeyLearn_SKCByte2 1;
BA_ "GenSigSendType" SG_ 962 Mdc_KeyLearn_SKCByte3 1;
BA_ "GenSigSendType" SG_ 962 Mdc_KeyLearn_SKCByte4 1;
BA_ "GenSigSendType" SG_ 962 Mdc_KeyLearn_SKCByte5 1;
BA_ "GenSigSendType" SG_ 962 Mdc_KeyLearn_SKCByte6 1;
BA_ "GenSigSendType" SG_ 962 Mdc_KeyLearn_SKCByte7 1;
BA_ "GenSigSendType" SG_ 962 Mdc_KeyLearn_SKCByte8 1;
BA_ "GenSigSendType" SG_ 962 Mdc_KeyLearn_SKCByte9 1;
BA_ "GenSigSendType" SG_ 962 Mdc_KeyLearn_SKCByte10 1;
BA_ "GenSigSendType" SG_ 962 Mdc_KeyLearn_SKCByte11 1;
BA_ "GenSigSendType" SG_ 962 Mdc_KeyLearn_SKCByte12 1;
BA_ "GenSigSendType" SG_ 962 Mdc_KeyLearn_SKCByte13 1;
BA_ "GenSigSendType" SG_ 962 Mdc_KeyLearn_SKCByte14 1;
BA_ "GenSigSendType" SG_ 962 Mdc_KeyLearn_SKCByte15 1;
BA_ "GenSigSendType" SG_ 962 Mdc_KeyLearn_SKCByte16 1;
BA_ "GenSigSendType" SG_ 962 Mdc_KeyLearn_MACByte1 1;
BA_ "GenSigSendType" SG_ 962 Mdc_KeyLearn_MACByte2 1;
BA_ "GenSigSendType" SG_ 962 Mdc_KeyLearn_MACByte3 1;
BA_ "GenSigSendType" SG_ 962 Mdc_KeyLearn_MACByte4 1;
BA_ "GenSigSendType" SG_ 962 Mdc_KeyLearn_MACByte5 1;
BA_ "GenSigSendType" SG_ 962 Mdc_KeyLearn_MACByte6 1;
BA_ "GenSigSendType" SG_ 962 Mdc_KeyLearn_MACByte7 1;
BA_ "GenSigSendType" SG_ 962 Mdc_KeyLearn_MACByte8 1;
BA_ "GenSigSendType" SG_ 962 Mdc_KeyLearn_MACByte9 1;
BA_ "GenSigSendType" SG_ 962 Mdc_KeyLearn_MACByte10 1;
BA_ "GenSigSendType" SG_ 962 Mdc_KeyLearn_MACByte11 1;
BA_ "GenSigSendType" SG_ 962 Mdc_KeyLearn_MACByte12 1;
BA_ "GenSigSendType" SG_ 962 Mdc_KeyLearn_MACByte13 1;
BA_ "GenSigSendType" SG_ 962 Mdc_KeyLearn_MACByte14 1;
BA_ "GenSigSendType" SG_ 962 Mdc_KeyLearn_MACByte15 1;
BA_ "GenSigSendType" SG_ 962 Mdc_KeyLearn_MACByte16 1;
BA_ "GenSigSendType" SG_ 962 Mdc_KeyLearn_IVByte1 1;
BA_ "GenSigSendType" SG_ 962 Mdc_KeyLearn_IVByte2 1;
BA_ "GenSigSendType" SG_ 962 Mdc_KeyLearn_IVByte3 1;
BA_ "GenSigSendType" SG_ 962 Mdc_KeyLearn_IVByte4 1;
BA_ "GenSigSendType" SG_ 962 Mdc_KeyLearn_IVByte5 1;
BA_ "GenSigSendType" SG_ 962 Mdc_KeyLearn_IVByte6 1;
BA_ "GenSigSendType" SG_ 962 Mdc_KeyLearn_IVByte7 1;
BA_ "GenSigSendType" SG_ 962 Mdc_KeyLearn_IVByte8 1;
BA_ "GenSigSendType" SG_ 962 Mdc_KeyLearn_IVByte9 1;
BA_ "GenSigSendType" SG_ 962 Mdc_KeyLearn_IVByte10 1;
BA_ "GenSigSendType" SG_ 962 Mdc_KeyLearn_IVByte11 1;
BA_ "GenSigSendType" SG_ 962 Mdc_KeyLearn_IVByte12 1;
BA_ "GenSigSendType" SG_ 962 Mdc_KeyLearn_SC 1;
BA_ "GenSigSendType" SG_ 963 Mdc_KeyLearnSubID_SKSetting 1;
BA_ "GenSigStartValue" SG_ 963 Mdc_KeyLearn_SKID 1;
BA_ "GenSigSendType" SG_ 963 Mdc_KeyLearn_SKID 1;
BA_ "GenSigSendType" SG_ 964 Mdc_KeyLearnSubID_CleanID 1;
BA_ "GenSigStartValue" SG_ 964 Mdc_KeyLearn_Clean_SKID 1;
BA_ "GenSigSendType" SG_ 964 Mdc_KeyLearn_Clean_SKID 1;
BA_ "GenSigSendType" SG_ 964 Mdc_KeyLearn_Clean_SCByte1 1;
BA_ "GenSigSendType" SG_ 964 Mdc_KeyLearn_Clean_SCByte2 1;
BA_ "GenSigSendType" SG_ 964 Mdc_KeyLearn_Clean_SCByte3 1;
BA_ "GenSigSendType" SG_ 964 Mdc_KeyLearn_Clean_SCByte4 1;
BA_ "GenSigSendType" SG_ 964 Mdc_KeyLearn_Clean_SCByte5 1;
BA_ "GenSigSendType" SG_ 964 Mdc_KeyLearn_Clean_SCByte6 1;
BA_ "GenSigSendType" SG_ 964 Mdc_KeyLearn_Clean_SCByte7 1;
BA_ "GenSigSendType" SG_ 964 Mdc_KeyLearn_Clean_SCByte8 1;
BA_ "GenSigSendType" SG_ 964 Mdc_KeyLearn_Clean_SCByte9 1;
BA_ "GenSigSendType" SG_ 964 Mdc_KeyLearn_Clean_SCByte10 1;
BA_ "GenSigSendType" SG_ 964 Mdc_KeyLearn_Clean_SCByte11 1;
BA_ "GenSigSendType" SG_ 964 Mdc_KeyLearn_Clean_SCByte12 1;
BA_ "GenSigSendType" SG_ 964 Mdc_KeyLearn_Clean_SCByte13 1;
BA_ "GenSigSendType" SG_ 964 Mdc_KeyLearn_Clean_SCByte14 1;
BA_ "GenSigSendType" SG_ 964 Mdc_KeyLearn_Clean_SCByte15 1;
BA_ "GenSigSendType" SG_ 964 Mdc_KeyLearn_Clean_SCByte16 1;
BA_ "GenSigSendType" SG_ 964 Mdc_KeyLearn_Clean_MACByte1 1;
BA_ "GenSigSendType" SG_ 964 Mdc_KeyLearn_Clean_MACByte2 1;
BA_ "GenSigSendType" SG_ 964 Mdc_KeyLearn_Clean_MACByte3 1;
BA_ "GenSigSendType" SG_ 964 Mdc_KeyLearn_Clean_MACByte4 1;
BA_ "GenSigSendType" SG_ 964 Mdc_KeyLearn_Clean_MACByte5 1;
BA_ "GenSigSendType" SG_ 964 Mdc_KeyLearn_Clean_MACByte6 1;
BA_ "GenSigSendType" SG_ 964 Mdc_KeyLearn_Clean_MACByte7 1;
BA_ "GenSigSendType" SG_ 964 Mdc_KeyLearn_Clean_MACByte8 1;
BA_ "GenSigSendType" SG_ 964 Mdc_KeyLearn_Clean_MACByte9 1;
BA_ "GenSigSendType" SG_ 964 Mdc_KeyLearn_Clean_MACByte10 1;
BA_ "GenSigSendType" SG_ 964 Mdc_KeyLearn_Clean_MACByte11 1;
BA_ "GenSigSendType" SG_ 964 Mdc_KeyLearn_Clean_MACByte12 1;
BA_ "GenSigSendType" SG_ 964 Mdc_KeyLearn_Clean_MACByte13 1;
BA_ "GenSigSendType" SG_ 964 Mdc_KeyLearn_Clean_MACByte14 1;
BA_ "GenSigSendType" SG_ 964 Mdc_KeyLearn_Clean_MACByte15 1;
BA_ "GenSigSendType" SG_ 964 Mdc_KeyLearn_Clean_MACByte16 1;
BA_ "GenSigSendType" SG_ 964 Mdc_KeyLearn_Clean_IVByte1 1;
BA_ "GenSigSendType" SG_ 964 Mdc_KeyLearn_Clean_IVByte2 1;
BA_ "GenSigSendType" SG_ 964 Mdc_KeyLearn_Clean_IVByte3 1;
BA_ "GenSigSendType" SG_ 964 Mdc_KeyLearn_Clean_IVByte4 1;
BA_ "GenSigSendType" SG_ 964 Mdc_KeyLearn_Clean_IVByte5 1;
BA_ "GenSigSendType" SG_ 964 Mdc_KeyLearn_Clean_IVByte6 1;
BA_ "GenSigSendType" SG_ 964 Mdc_KeyLearn_Clean_IVByte7 1;
BA_ "GenSigSendType" SG_ 964 Mdc_KeyLearn_Clean_IVByte8 1;
BA_ "GenSigSendType" SG_ 964 Mdc_KeyLearn_Clean_IVByte9 1;
BA_ "GenSigSendType" SG_ 964 Mdc_KeyLearn_Clean_IVByte10 1;
BA_ "GenSigSendType" SG_ 964 Mdc_KeyLearn_Clean_IVByte11 1;
BA_ "GenSigSendType" SG_ 964 Mdc_KeyLearn_Clean_IVByte12 1;
BA_ "GenSigSendType" SG_ 961 Mdc_VerifySubID_Random 1;
BA_ "GenSigStartValue" SG_ 961 Mdc_Verify_SKID 1;
BA_ "GenSigSendType" SG_ 961 Mdc_Verify_SKID 1;
BA_ "GenSigSendType" SG_ 961 Mdc_Verify_Random 1;
BA_ "GenSigSendType" SG_ 965 Mdc_Verify_ResultID 1;
BA_ "GenSigStartValue" SG_ 965 Mdc_Verify_Result_SKID 1;
BA_ "GenSigSendType" SG_ 965 Mdc_Verify_Result_SKID 1;
BA_ "GenSigSendType" SG_ 965 Mdc_Verify_Result_Status 1;
VAL_ 773 sensorVersion 4 "X2 EHY 中配" 3 "X2 EH3 高配" ;
VAL_ 513 PAS_sonar1_Blind 0 "False" 1 "Ture" ;
VAL_ 513 PAS_sonar2_Blind 0 "False" 1 "Ture" ;
VAL_ 513 PAS_sonar3_Blind 0 "False" 1 "Ture" ;
VAL_ 513 PAS_sonar4_Blind 0 "False" 1 "Ture" ;
VAL_ 513 PAS_sonar0_Blind 0 "False" 1 "Ture" ;
VAL_ 513 PAS_sonar5_Blind 0 "False" 1 "Ture" ;
VAL_ 513 PASDistanceFrontRollingCounter 15 "Invalid" ;
VAL_ 513 MSG201_Fill4bit 15 "填充位" ;
VAL_ 514 PAS_sonar7_Blind 0 "False" 1 "Ture" ;
VAL_ 514 PAS_sonar8_Blind 0 "False" 1 "Ture" ;
VAL_ 514 PAS_sonar9_Blind 0 "False" 1 "Ture" ;
VAL_ 514 PAS_sonar10_Blind 0 "False" 1 "Ture" ;
VAL_ 514 PAS_sonar6_Blind 0 "False" 1 "Ture" ;
VAL_ 514 PAS_sonar11_Blind 0 "False" 1 "Ture" ;
VAL_ 514 PAS_Distance_Rear_RollingCounter 15 "Invalid" ;
VAL_ 514 MSG202_Fill4bit 15 "填充位" ;
VAL_ 515 PAS_Sonar0_Emit 0 "off" 1 "receive only" 2 "emit and receive" ;
VAL_ 515 PAS_Sonar1_Emit 0 "off" 1 "receive only" 2 "emit and receive" ;
VAL_ 515 PAS_Sonar2_Emit 0 "off" 1 "receive only" 2 "emit and receive" ;
VAL_ 515 PAS_Sonar3_Emit 0 "off" 1 "receive only" 2 "emit and receive" ;
VAL_ 515 PAS_Sonar4_Emit 0 "off" 1 "receive only" 2 "emit and receive" ;
VAL_ 515 PAS_Sonar5_Emit 0 "off" 1 "receive only" 2 "emit and receive" ;
VAL_ 515 PASSonarInfoFrontRollingCounter 15 "Invalid" ;
VAL_ 515 MSG203_Fill4bit 15 "填充位" ;
VAL_ 517 PAS_Sonar6_Emit 0 "off" 1 "receive only" 2 "emit and receive" ;
VAL_ 517 PAS_Sonar7_Emit 0 "off" 1 "receive only" 2 "emit and receive" ;
VAL_ 517 PAS_Sonar8_Emit 0 "off" 1 "receive only" 2 "emit and receive" ;
VAL_ 517 PAS_Sonar9_Emit 0 "off" 1 "receive only" 2 "emit and receive" ;
VAL_ 517 PAS_Sonar10_Emit 0 "off" 1 "receive only" 2 "emit and receive" ;
VAL_ 517 PAS_Sonar11_Emit 0 "off" 1 "receive only" 2 "emit and receive" ;
VAL_ 517 PASSonarInfoRearRollingCounter 15 "Invalid" ;
VAL_ 517 MSG205_Fill4bit 15 "填充位" ;
VAL_ 544 PAS_WakeUp_Response 0 "未收到唤醒报文" 1 "收到唤醒报文" ;
VAL_ 544 PAS_SonarMode_Response 0 "未收探头工作模式指令报文" 1 "收到工作模式指令报文" ;
VAL_ 544 PAS_Reponse_RollingCounter 15 "Invalid" ;
VAL_ 544 MSG220_Fill4bit 15 "填充位" ;
VAL_ 560 sensorVersion_Status 0 "未收到版本信息（沿用上次配置）" 1 "收到传感器版本信息" ;
VAL_ 560 PAS_SensorStsLR_FLS 1 "Fail" 0 "normal   " ;
VAL_ 560 PAS_SensorStsLR_FRS 1 "Fail" 0 "normal    " ;
VAL_ 560 PAS_SensorStsSR_FL 1 "Fail" 0 "normal  " ;
VAL_ 560 PAS_SensorStsSR_FML 1 "Fail" 0 "normal    " ;
VAL_ 560 PAS_SensorStsSR_FMR 1 "Fail" 0 "normal   " ;
VAL_ 560 PAS_SensorStsSR_FR 1 "Fail" 0 "normal    " ;
VAL_ 560 PAS_SensorStsLR_RLS 1 "Fail" 0 "normal  " ;
VAL_ 560 PAS_SensorStsLR_RRS 1 "Fail" 0 "normal " ;
VAL_ 560 PAS_SensorStsSR_RL 1 "Fail" 0 "normal  " ;
VAL_ 560 PAS_SensorStsSR_RML 1 "Fail" 0 "normal   " ;
VAL_ 560 PAS_SensorStsSR_RMR 1 "Fail" 0 "normal   " ;
VAL_ 560 PAS_SensorStsSR_RR 1 "Fail" 0 "normal   " ;
VAL_ 560 PAS_ECU_Status 1 "Fail" 0 "normal    " ;
VAL_ 560 PAS_ECU_VehStatus_Reponse 0 "接收到车辆状态信息" 1 " 未接收到车辆状态信息" ;
VAL_ 560 PAS_SensorStatus_RollingCounter 15 "Invalid" ;
VAL_ 560 MSG230_Fill4bit 15 "填充位" ;
VAL_ 576 PAS_ECUInfo_RollingCounter 15 "Invalid" ;
VAL_ 576 MSG240_Fill4bit 15 "填充位" ;
VAL_ 592 Rpt_Alarm_State 0 "告警恢复" 1 " 告警产生" ;
VAL_ 592 Rpt_Alarm_Level 0 "提示" 1 "一般" 2 " 严重" ;
VAL_ 592 Rpt_Alarm_RollingCounter 15 "Invalid" ;
VAL_ 592 MSG250_Fill4bit 15 "填充位" ;
VAL_ 593 USS_Front_ShortToGND 0 "normal" 1 "Fail" ;
VAL_ 593 USS_Front_ShortToUbat 0 "normal" 1 "Fail" ;
VAL_ 593 USS_Rear_ShortToGND 0 "normal" 1 "Fail" ;
VAL_ 593 USS_Rear_ShortToUbat 0 "normal" 1 "Fail" ;
VAL_ 593 VHM_Error 0 "normal" 1 "Fail" ;
VAL_ 593 Sensor_Version_Fail 0 "normal" 1 "Fail" ;
VAL_ 593 PAS_Sonar0_Internal_failure 0 "normal" 1 "Fail" ;
VAL_ 593 PAS_Sonar1_Internal_failure 0 "normal" 1 "Fail" ;
VAL_ 593 PAS_Sonar2_Internal_failure 0 "normal" 1 "Fail" ;
VAL_ 593 PAS_Sonar3_Internal_failure 0 "normal" 1 "Fail" ;
VAL_ 593 PAS_Sonar4_Internal_failure 0 "normal" 1 "Fail" ;
VAL_ 593 PAS_Sonar5_Internal_failure 0 "normal" 1 "Fail" ;
VAL_ 593 PAS_Sonar6_Internal_failure 0 "normal" 1 "Fail" ;
VAL_ 593 PAS_Sonar7_Internal_failure 0 "normal" 1 "Fail" ;
VAL_ 593 PAS_Sonar8_Internal_failure 0 "normal" 1 "Fail" ;
VAL_ 593 PAS_Sonar9_Internal_failure 0 "normal" 1 "Fail" ;
VAL_ 593 PAS_Sonar10_Internal_failure 0 "normal" 1 "Fail" ;
VAL_ 593 PAS_Sonar11_Internal_failure 0 "normal" 1 "Fail" ;
VAL_ 593 PAS_AUTHEN_ERROR 0 "normal" 1 "设备认证异常" ;
VAL_ 593 PAS_KEYLEARN_ERROR 0 "normal" 1 "密钥学习异常" ;
VAL_ 593 PAS_TIMESYNC_ERROR 0 "normal" 1 "时间同步异常" ;
VAL_ 593 PAS_ECU_INTERNAL_ERROR 0 "normal" 1 "USS ECU内部故障" ;
VAL_ 593 PAS_MDCSIGNAL_ERROR 0 "normal" 1 "MDC发出无效信号" ;
VAL_ 593 PAS_Sonar1_ControlBusFailure 0 "探头正常" 1 "探头不正常" ;
VAL_ 593 PAS_Sonar1_RingingTimeFailure 0 "探头正常" 1 "探头不正常" ;
VAL_ 593 PAS_Sonar1_ShortToGND 0 "探头正常" 1 "探头不正常" ;
VAL_ 593 PAS_Sonar1_ShortToPositivePole 0 "探头正常" 1 "探头不正常" ;
VAL_ 593 PAS_Sonar1_TypeMismatch 0 "探头正常" 1 "探头不正常" ;
VAL_ 593 PAS_Sonar2_ControlBusFailure 0 "探头正常" 1 "探头不正常" ;
VAL_ 593 PAS_Sonar2_RingingTimeFailure 0 "探头正常" 1 "探头不正常" ;
VAL_ 593 PAS_Sonar2_ShortToGND 0 "探头正常" 1 "探头不正常" ;
VAL_ 593 PAS_Sonar2_ShortToPositivePole 0 "探头正常" 1 "探头不正常" ;
VAL_ 593 PAS_Sonar2_TypeMismatch 0 "探头正常" 1 "探头不正常" ;
VAL_ 593 PAS_Sonar3_ControlBusFailure 0 "探头正常" 1 "探头不正常" ;
VAL_ 593 PAS_Sonar3_RingingTimeFailure 0 "探头正常" 1 "探头不正常" ;
VAL_ 593 PAS_Sonar3_ShortToGND 0 "探头正常" 1 "探头不正常" ;
VAL_ 593 PAS_Sonar3_ShortToPositivePole 0 "探头正常" 1 "探头不正常" ;
VAL_ 593 PAS_Sonar3_TypeMismatch 0 "探头正常" 1 "探头不正常" ;
VAL_ 593 PAS_Sonar3_PowerVoltage_Low 0 "探头正常" 1 "探头不正常" ;
VAL_ 593 PAS_Sonar3_PowerVoltage_High 0 "探头正常" 1 "探头不正常" ;
VAL_ 593 PAS_Sonar4_ControlBusFailure 0 "探头正常" 1 "探头不正常" ;
VAL_ 593 PAS_Sonar4_RingingTimeFailure 0 "探头正常" 1 "探头不正常" ;
VAL_ 593 PAS_Sonar4_ShortToGND 0 "探头正常" 1 "探头不正常" ;
VAL_ 593 PAS_Sonar4_ShortToPositivePole 0 "探头正常" 1 "探头不正常" ;
VAL_ 593 PAS_Sonar4_TypeMismatch 0 "探头正常" 1 "探头不正常" ;
VAL_ 593 PAS_Sonar7_ControlBusFailure 0 "探头正常" 1 "探头不正常" ;
VAL_ 593 PAS_Sonar7_RingingTimeFailure 0 "探头正常" 1 "探头不正常" ;
VAL_ 593 PAS_Sonar7_ShortToGND 0 "探头正常" 1 "探头不正常" ;
VAL_ 593 PAS_Sonar7_ShortToPositivePole 0 "探头正常" 1 "探头不正常" ;
VAL_ 593 PAS_Sonar7_TypeMismatch 0 "探头正常" 1 "探头不正常" ;
VAL_ 593 PAS_Sonar8_ControlBusFailure 0 "探头正常" 1 "探头不正常" ;
VAL_ 593 PAS_Sonar8_RingingTimeFailure 0 "探头正常" 1 "探头不正常" ;
VAL_ 593 PAS_Sonar8_ShortToGND 0 "探头正常" 1 "探头不正常" ;
VAL_ 593 PAS_Sonar8_ShortToPositivePole 0 "探头正常" 1 "探头不正常" ;
VAL_ 593 PAS_Sonar8_TypeMismatch 0 "探头正常" 1 "探头不正常" ;
VAL_ 593 PAS_Sonar9_ControlBusFailure 0 "探头正常" 1 "探头不正常" ;
VAL_ 593 PAS_Sonar9_RingingTimeFailure 0 "探头正常" 1 "探头不正常" ;
VAL_ 593 PAS_Sonar9_ShortToGND 0 "探头正常" 1 "探头不正常" ;
VAL_ 593 PAS_Sonar9_ShortToPositivePole 0 "探头正常" 1 "探头不正常" ;
VAL_ 593 PAS_Sonar9_TypeMismatch 0 "探头正常" 1 "探头不正常" ;
VAL_ 593 PAS_Sonar10_ControlBusFailure 0 "探头正常" 1 "探头不正常" ;
VAL_ 593 PAS_Sonar10_RingingTimeFailure 0 "探头正常" 1 "探头不正常" ;
VAL_ 593 PAS_Sonar10_ShortToGND 0 "探头正常" 1 "探头不正常" ;
VAL_ 593 PAS_Sonar10_ShortToPositivePole 0 "探头正常" 1 "探头不正常" ;
VAL_ 593 PAS_Sonar10_TypeMismatch 0 "探头正常" 1 "探头不正常" ;
VAL_ 593 PAS_Sonar0_ControlBusFailure 0 "探头正常" 1 "探头不正常" ;
VAL_ 593 PAS_Sonar0_RingingTimeFailure 0 "探头正常" 1 "探头不正常" ;
VAL_ 593 PAS_Sonar0_ShortToGND 0 "探头正常" 1 "探头不正常" ;
VAL_ 593 PAS_Sonar0_ShortToPositivePole 0 "探头正常" 1 "探头不正常" ;
VAL_ 593 PAS_Sonar0_TypeMismatch 0 "探头正常" 1 "探头不正常" ;
VAL_ 593 PAS_Sonar5_ControlBusFailure 0 "探头正常" 1 "探头不正常" ;
VAL_ 593 PAS_Sonar5_RingingTimeFailure 0 "探头正常" 1 "探头不正常" ;
VAL_ 593 PAS_Sonar5_ShortToGND 0 "探头正常" 1 "探头不正常" ;
VAL_ 593 PAS_Sonar5_ShortToPositivePole 0 "探头正常" 1 "探头不正常" ;
VAL_ 593 PAS_Sonar5_TypeMismatch 0 "探头正常" 1 "探头不正常" ;
VAL_ 593 PAS_Sonar6_ControlBusFailure 0 "探头正常" 1 "探头不正常" ;
VAL_ 593 PAS_Sonar6_RingingTimeFailure 0 "探头正常" 1 "探头不正常" ;
VAL_ 593 PAS_Sonar6_ShortToGND 0 "探头正常" 1 "探头不正常" ;
VAL_ 593 PAS_Sonar6_ShortToPositivePole 0 "探头正常" 1 "探头不正常" ;
VAL_ 593 PAS_Sonar6_TypeMismatch 0 "探头正常" 1 "探头不正常" ;
VAL_ 593 PAS_Sonar11_ControlBusFailure 0 "探头正常" 1 "探头不正常" ;
VAL_ 593 PAS_Sonar11_RingingTimeFailure 0 "探头正常" 1 "探头不正常" ;
VAL_ 593 PAS_Sonar11_ShortToGND 0 "探头正常" 1 "探头不正常" ;
VAL_ 593 PAS_Sonar11_ShortToPositivePole 0 "探头正常" 1 "探头不正常" ;
VAL_ 593 PAS_Sonar11_TypeMismatch 0 "探头正常" 1 "探头不正常" ;
VAL_ 593 PAS_ECU_OverVoltage 0 "normal" 1 "Fail" ;
VAL_ 593 PAS_ECU_UnderVoltage 0 "normal" 1 "Fail" ;
VAL_ 593 PAS_ECU_BusOff_ERROR 0 "No CAN Busoff error" 1 " CAN Busoff error" ;
VAL_ 593 PAS_MDC_COMMU_ERROR 0 "normal" 1 "Fail" ;
VAL_ 593 PAS_ECU_EEPROM_ERROR 0 "normal" 1 "Fail" ;
VAL_ 593 PAS_DiagnosisInfo_RollingCounter 15 "Invalid" ;
VAL_ 593 MSG251_Fill4bit 15 "填充位" ;
VAL_ 672 PAS_Device_Vertify_Status 0 "未认证" 1 " 已认证" ;
VAL_ 674 PAS_Verification_Result 6 "其他认证错误" 5 "未认证" 4 "认证报文超时" 3 "MAC校验失败" 2 "FV校验失败（挑战应答不使用）" 0 "认证成功" 1 "密钥未学习" ;
VAL_ 706 PAS_SK_Learn_Status1 0 "未学习" 1 "已学习" ;
VAL_ 706 PAS_SK_Learn_Status2 0 "未学习" 1 "已学习" ;
VAL_ 706 PAS_SK_Learn_Status3 0 "未学习" 1 "已学习" ;
VAL_ 706 PAS_SK_Learn_Status4 0 "未学习" 1 "已学习" ;
VAL_ 706 PAS_SK_Learn_Status5 0 "未学习" 1 "已学习" ;
VAL_ 706 PAS_SK_Learn_Status6 0 "未学习" 1 "已学习" ;
VAL_ 706 PAS_SK_Learn_Status7 0 "未学习" 1 "已学习" ;
VAL_ 706 PAS_SK_Learn_Status8 0 "未学习" 1 "已学习" ;
VAL_ 706 PAS_SK_Learn_Status9 0 "未学习" 1 "已学习" ;
VAL_ 706 PAS_SK_Learn_Status10 0 "未学习" 1 "已学习" ;
VAL_ 706 PAS_SK_Learn_Status11 0 "未学习" 1 "已学习" ;
VAL_ 706 PAS_SK_Learn_Status12 0 "未学习" 1 "已学习" ;
VAL_ 708 PAS_SK_Setting_Status 0 "未学习" 1 "已学习" ;
VAL_ 640 UPCVehiclePositionUpdateTime 4095 " Invalid" ;
VAL_ 640 PAS_VehPos_RollingCounter 15 "Invalid" ;
VAL_ 641 PAS_PSL_Status 0 "Off" 1 "Standby" 2 "Searching" 3 "Guidance" 4 "Failure" 5 " Reserved" ;
VAL_ 641 PAS_PSL_RollingCounter 15 "Invalid" ;
VAL_ 642 PAS_Echo_WorkMode 15 "Reserved" 14 "Reserved" 13 "Reserved" 12 "Reserved" 11 "Reserved" 10 "Reserved" 9 "Reserved" 8 "Reserved" 7 "resetting" 0 "Off" 1 "Standby" 2 "FrontRearActive" 3 "FrontActiveAndRearFailure" 4 "RearActiveAndFrontFailure" 5 "SystemFailure" 6 "suspension Adjust" ;
VAL_ 642 PAS_MapObject_OuputStatus 15 "Reserved" 14 "Reserved" 13 "Reserved" 12 "Reserved" 11 "Reserved" 10 "Reserved" 9 "Reserved" 8 "Reserved" 7 "Reserved" 0 "Off" 1 "Standby" 2 "FrontRearActive" 3 "FrontActiveAndRearFailure" 4 "RearActiveAndFrontFailure" 5 "SystemFailure" 6 "Reserved" ;
VAL_ 642 PAS_EchoMap_RollingCounter 15 "Invalid" ;
VAL_ 768 MDC_PAS_Control 0 "system off" 1 "standby" 2 "Enable" 3 "reserved" ;
VAL_ 768 MSG300_Fill4bit 255 "填充位" ;
VAL_ 769 MDC_ESC_VehicleSpeed_Valid 0 "Invalid" 1 " Valid" ;
VAL_ 769 MDC_SAS_SteerWheelAngle_Valid 0 "Invalid" 1 " Valid" ;
VAL_ 769 MDC_BCM_OutTemp_Valid 0 "Invalid" 1 " Valid" ;
VAL_ 769 MDC_VCU_GearStatus 0 "P" 1 "N" 2 "D" 3 "R" ;
VAL_ 769 MDC_VCU_GearStatus_Valid 0 "Invalid" 1 " Valid" ;
VAL_ 769 MDC_ESC_FLWheelSpeedRC_Valid 0 "Invalid" 1 " Valid" ;
VAL_ 769 MDC_ESC_FRWheelSpeedRC_Valid 0 "Invalid" 1 " Valid" ;
VAL_ 769 MDC_ESC_RLWheelSpeedRC_Valid 0 "Invalid" 1 " Valid" ;
VAL_ 769 MDC_ESC_RRWheelSpeedRC_Valid 0 "Invalid" 1 " Valid" ;
VAL_ 769 MDC_ESC_FLWheelDirection 0 "FORWARD" 1 "BACKWARD" 2 "STANDSTILL" 3 " INVALID" ;
VAL_ 769 MDC_ESC_FLWheelDirection_Valid 0 "Invalid" 1 " Valid" ;
VAL_ 769 MDC_ESC_FRWheelDirection 0 "FORWARD" 1 "BACKWARD" 2 "STANDSTILL" 3 " INVALID" ;
VAL_ 769 MDC_ESC_FRWheelDirection_Valid 0 "Invalid" 1 " Valid" ;
VAL_ 769 MDC_ESC_RLWheelDirection 0 "FORWARD" 1 "BACKWARD" 2 "STANDSTILL" 3 " INVALID" ;
VAL_ 769 MDC_ESC_RLWheelDirection_Valid 0 "Invalid" 1 " Valid" ;
VAL_ 769 MDC_ESC_RRWheelDirection 0 "FORWARD" 1 "BACKWARD" 2 "STANDSTILL" 3 " INVALID" ;
VAL_ 769 MDC_ESC_RRWheelDirection_Valid 0 "Invalid" 1 " Valid" ;
VAL_ 769 YawRateSensor_St 0 "Invalid" 1 " Valid" ;
VAL_ 769 wheelspeedValid 1 "valid" 0 "invalid" ;
VAL_ 769 ecasVehiclePositionState 0 "Initializing" 1 "Very High" 2 "High" 3 "Standard" 4 "Low" 5 "Very Low" 6 "Invalid" 7 "noAirSuspension" ;
VAL_ 769 ecasVehicleUpDownState 0 "Standby" 1 "Up" 2 "Down" 3 "reserve" 4 "reserve" 5 "reserve" 6 "reserve" 7 "Invalid" ;
VAL_ 769 VehiclePositionStateValid 0 "invalid" 1 "valid" ;
VAL_ 769 VehicleUpDownStateValid 0 "invalid" 1 "valid" ;
VAL_ 770 PAS_Sonar1_Req 0 "off" 1 "receive only" 2 "emit and receive" ;
VAL_ 770 PAS_Sonar2_Req 0 "off" 1 "receive only" 2 "emit and receive" ;
VAL_ 770 PAS_Sonar3_Req 0 "off" 1 "receive only" 2 "emit and receive" ;
VAL_ 770 PAS_Sonar4_Req 0 "off" 1 "receive only" 2 "emit and receive" ;
VAL_ 770 PAS_Sonar7_Req 0 "off" 1 "receive only" 2 "emit and receive" ;
VAL_ 770 PAS_Sonar8_Req 0 "off" 1 "receive only" 2 "emit and receive" ;
VAL_ 770 PAS_Sonar9_Req 0 "off" 1 "receive only" 2 "emit and receive" ;
VAL_ 770 PAS_Sonar10_Req 0 "off" 1 "receive only" 2 "emit and receive" ;
VAL_ 770 PAS_Sonar0_Req 0 "off" 1 "receive only" 2 "emit and receive" ;
VAL_ 770 PAS_Sonar5_Req 0 "off" 1 "receive only" 2 "emit and receive" ;
VAL_ 770 PAS_Sonar6_Req 0 "off" 1 "receive only" 2 "emit and receive" ;
VAL_ 770 PAS_Sonar11_Req 0 "off" 1 "receive only" 2 "emit and receive" ;
VAL_ 770 MSG302_Fill4bit 255 "填充位" ;
VAL_ 770 PAS_Function_Req 1 "低速模式" 0 "高速模式（默认模式）" ;
VAL_ 771 Ack_Alarm_State 0 "告警恢复" 1 " 告警产生" ;
VAL_ 771 Ack_Alarm_Level 0 "提示" 1 "一般" 2 " 严重" ;
VAL_ 771 MSG303_Fill4bit 255 "填充位" ;
VAL_ 929 MDC_Response_Result 0 "处理成功" 1 "处理失败" ;
VAL_ 965 Mdc_Verify_Result_Status 0 "失败" 1 "成功" ;
VAL_ 656 Point_00_Valid 0 "invalid" 1 " valid" ;
VAL_ 656 Point_00_High 2 "Unknown" 0 "Low" 1 "High" ;
VAL_ 656 Point_01_Valid 0 "invalid" 1 " valid" ;
VAL_ 656 Point_01_High 2 "Unknown" 0 "Low" 1 "High" ;
VAL_ 656 Point_02_Valid 0 "invalid" 1 " valid" ;
VAL_ 656 Point_02_High 2 "Unknown" 0 "Low" 1 "High" ;
VAL_ 656 Point_03_Valid 0 "invalid" 1 " valid" ;
VAL_ 656 Point_03_High 2 "Unknown" 0 "Low" 1 "High" ;
VAL_ 656 Point_04_Valid 0 "invalid" 1 " valid" ;
VAL_ 656 Point_04_High 2 "Unknown" 0 "Low" 1 "High" ;
VAL_ 656 Point_05_Valid 0 "invalid" 1 " valid" ;
VAL_ 656 Point_05_High 2 "Unknown" 0 "Low" 1 "High" ;
VAL_ 656 Point_06_Valid 0 "invalid" 1 " valid" ;
VAL_ 656 Point_06_High 2 "Unknown" 0 "Low" 1 "High" ;
VAL_ 657 Point_07_Valid 0 "invalid" 1 " valid" ;
VAL_ 657 Point_07_High 2 "Unknown" 0 "Low" 1 "High" ;
VAL_ 657 Point_08_Valid 0 "invalid" 1 " valid" ;
VAL_ 657 Point_08_High 2 "Unknown" 0 "Low" 1 "High" ;
VAL_ 657 Point_09_Valid 0 "invalid" 1 " valid" ;
VAL_ 657 Point_09_High 2 "Unknown" 0 "Low" 1 "High" ;
VAL_ 657 Point_10_Valid 0 "invalid" 1 " valid" ;
VAL_ 657 Point_10_High 2 "Unknown" 0 "Low" 1 "High" ;
VAL_ 657 Point_11_Valid 0 "invalid" 1 " valid" ;
VAL_ 657 Point_11_High 2 "Unknown" 0 "Low" 1 "High" ;
VAL_ 657 Point_12_Valid 0 "invalid" 1 " valid" ;
VAL_ 657 Point_12_High 2 "Unknown" 0 "Low" 1 "High" ;
VAL_ 657 Point_13_Valid 0 "invalid" 1 " valid" ;
VAL_ 657 Point_13_High 2 "Unknown" 0 "Low" 1 "High" ;
VAL_ 658 Point_14_Valid 0 "invalid" 1 " valid" ;
VAL_ 658 Point_14_High 2 "Unknown" 0 "Low" 1 "High" ;
VAL_ 658 Point_15_Valid 0 "invalid" 1 " valid" ;
VAL_ 658 Point_15_High 2 "Unknown" 0 "Low" 1 "High" ;
VAL_ 658 Point_16_Valid 0 "invalid" 1 " valid" ;
VAL_ 658 Point_16_High 2 "Unknown" 0 "Low" 1 "High" ;
VAL_ 658 Point_17_Valid 0 "invalid" 1 " valid" ;
VAL_ 658 Point_17_High 2 "Unknown" 0 "Low" 1 "High" ;
VAL_ 658 Point_18_Valid 0 "invalid" 1 " valid" ;
VAL_ 658 Point_18_High 2 "Unknown" 0 "Low" 1 "High" ;
VAL_ 658 Point_19_Valid 0 "invalid" 1 " valid" ;
VAL_ 658 Point_19_High 2 "Unknown" 0 "Low" 1 "High" ;
VAL_ 658 Point_20_Valid 0 "invalid" 1 " valid" ;
VAL_ 658 Point_20_High 2 "Unknown" 0 "Low" 1 "High" ;
SIG_GROUP_ 773 SG_Mdc_0x305 1 : sensorVersion;
SIG_GROUP_ 2024 SG_Diag_0x788 1 : Diag_PDC_RES;
SIG_GROUP_ 2016 SG_Diag_0X708 1 : Diag_PDC_REQ;
SIG_GROUP_ 2015 SG_DIAG_0X7DF 1 : Diag_Functional_REQ;
SIG_GROUP_ 513 SG_PAS_0X201 1 : MSG201_Fill4bit PAS_Distance_Front_Checksum PASDistanceFrontRollingCounter Msg201_PAS_sonar5_Counter PAS_sonar5_confidence PASsonar5crossDistanceLeftTime PAS_sonar5_crossDistanceRight PAS_sonar5_crossDistanceLeft PAS_sonar5_Blind PASsonar5DISTANCETime PAS_sonar5_DISTANCE Msg201_PAS_sonar0_Counter PAS_sonar0_confidence PASsonar0crossDistanceRightTime PAS_sonar0_crossDistanceRight PAS_sonar0_crossDistanceLeft PAS_sonar0_Blind PASsonar0DISTANCETime PAS_sonar0_DISTANCE Msg201_PAS_sonar4_Counter PAS_sonar4_confidence PASsonar4crossDistanceRightTime PASsonar4crossDistanceLeftTime PAS_sonar4_crossDistanceRight PAS_sonar4_crossDistanceLeft PAS_sonar4_Blind PASsonar4DISTANCETime PAS_sonar4_DISTANCE Msg201_PAS_sonar3_Counter PAS_sonar3_confidence PASsonar3crossDistanceRightTime PASsonar3crossDistanceLeftTime PAS_sonar3_crossDistanceRight PAS_sonar3_crossDistanceLeft PAS_sonar3_Blind PASsonar3DISTANCETime PAS_sonar3_DISTANCE Msg201_PAS_sonar2_Counter PAS_sonar2_confidence PASsonar2crossDistanceRightTime PASsonar2crossDistanceLeftTime PAS_sonar2_crossDistanceRight PAS_sonar2_crossDistanceLeft PAS_sonar2_Blind PASsonar2DISTANCETime PAS_sonar2_DISTANCE Msg201_PAS_sonar1_Counter PAS_sonar1_confidence PASsonar1crossDistanceRightTime PASsonar1crossDistanceLeftTime PAS_sonar1_crossDistanceRight PAS_sonar1_crossDistanceLeft PAS_sonar1_Blind PASsonar1DISTANCETime PAS_sonar1_DISTANCE;
SIG_GROUP_ 514 SG_PAS_0X202 1 : PAS_sonar8_Blind MSG202_Fill4bit PAS_Distance_Rear_Checksum PAS_Distance_Rear_RollingCounter Msg202_PAS_sonar11_Counter PAS_sonar11_confidence PASsonar11crossDistanceLeftTime PAS_sonar11_crossDistanceRight PAS_sonar11_crossDistanceLeft PAS_sonar11_Blind PASsonar11DISTANCETime PAS_sonar11_DISTANCE Msg202_PAS_sonar6_Counter PAS_sonar6_confidence PASsonar6crossDistanceRightTime PAS_sonar6_Blind PAS_sonar6_crossDistanceRight PAS_sonar6_crossDistanceLeft PASsonar6DISTANCETime PAS_sonar6_DISTANCE Msg202_PAS_sonar10_Counter PAS_sonar10_confidence PASsonar10crossDistanceRightTime PASsonar10crossDistanceLeftTime PAS_sonar10_crossDistanceRight PAS_sonar10_crossDistanceLeft PAS_sonar10_Blind PASsonar10DISTANCETime PAS_sonar10_DISTANCE Msg202_PAS_sonar9_Counter PAS_sonar9_confidence PASsonar9crossDistanceRightTime PASsonar9crossDistanceLeftTime PAS_sonar9_crossDistanceRight PAS_sonar9_crossDistanceLeft PAS_sonar9_Blind PASsonar9DISTANCETime PAS_sonar9_DISTANCE Msg202_PAS_sonar8_Counter PAS_sonar8_confidence PASsonar8crossDistanceRightTime PASsonar8crossDistanceLeftTime PAS_sonar8_crossDistanceRight PAS_sonar8_crossDistanceLeft PASsonar8DISTANCETime PAS_sonar8_DISTANCE Msg202_PAS_sonar7_Counter PAS_sonar7_confidence PASsonar7crossDistanceRightTime PASsonar7crossDistanceLeftTime PAS_sonar7_crossDistanceRight PAS_sonar7_crossDistanceLeft PAS_sonar7_Blind PASsonar7DISTANCETime PAS_sonar7_DISTANCE;
SIG_GROUP_ 515 SG_PAS_0X203 1 : MSG203_Fill4bit PAS_SonarInfo_Front_Checksum PASSonarInfoFrontRollingCounter Msg203_PAS_Sonar5_Counter PAS_Sonar5_RingingTime PAS_Sonar5_Emit PAS_Sonar5_Echo_Peak2 PAS_Sonar5_Echo_Peak1 PAS_Sonar5_Echo_Width2 PAS_Sonar5_Echo_TOF2 PAS_Sonar5_Echo_Width1 PAS_Sonar5_Echo_TOF1 Msg203_PAS_Sonar4_Counter PAS_Sonar4_RingingTime PAS_Sonar4_Emit PAS_Sonar4_Echo_Peak2 PAS_Sonar4_Echo_Peak1 PAS_Sonar4_Echo_Width2 PAS_Sonar4_Echo_TOF2 PAS_Sonar4_Echo_Width1 PAS_Sonar4_Echo_TOF1 Msg203_PAS_Sonar3_Counter PAS_Sonar3_RingingTime PAS_Sonar3_Emit PAS_Sonar3_Echo_Peak2 PAS_Sonar3_Echo_Peak1 PAS_Sonar3_Echo_Width2 PAS_Sonar3_Echo_TOF2 PAS_Sonar3_Echo_Width1 PAS_Sonar3_Echo_TOF1 Msg203_PAS_Sonar2_Counter PAS_Sonar2_RingingTime PAS_Sonar2_Emit PAS_Sonar2_Echo_Peak2 PAS_Sonar2_Echo_Peak1 PAS_Sonar2_Echo_Width2 PAS_Sonar2_Echo_TOF2 PAS_Sonar2_Echo_Width1 PAS_Sonar2_Echo_TOF1 Msg203_PAS_Sonar1_Counter PAS_Sonar1_RingingTime PAS_Sonar1_Emit PAS_Sonar1_Echo_Peak2 PAS_Sonar1_Echo_Peak1 PAS_Sonar1_Echo_Width2 PAS_Sonar1_Echo_TOF2 PAS_Sonar1_Echo_Width1 PAS_Sonar1_Echo_TOF1 Msg203_PAS_Sonar0_Counter PAS_Sonar0_RingingTime PAS_Sonar0_Emit PAS_Sonar0_Echo_Peak2 PAS_Sonar0_Echo_Peak1 PAS_Sonar0_Echo_Width2 PAS_Sonar0_Echo_TOF2 PAS_Sonar0_Echo_Width1 PAS_Sonar0_Echo_TOF1;
SIG_GROUP_ 517 SG_PAS_0X205 1 : MSG205_Fill4bit PAS_SonarInfo_Rear_Checksum PASSonarInfoRearRollingCounter MSG205_PAS_Sonar11_Counter PAS_Sonar11_RingingTime PAS_Sonar11_Emit PAS_Sonar11_Echo_Peak2 PAS_Sonar11_Echo_Peak1 PAS_Sonar11_Echo_Width2 PAS_Sonar11_Echo_TOF2 PAS_Sonar11_Echo_Width1 PAS_Sonar11_Echo_TOF1 Msg205_PAS_Sonar10_Counter PAS_Sonar10_RingingTime PAS_Sonar10_Emit PAS_Sonar10_Echo_Peak2 PAS_Sonar10_Echo_Peak1 PAS_Sonar10_Echo_Width2 PAS_Sonar10_Echo_TOF2 PAS_Sonar10_Echo_Width1 PAS_Sonar10_Echo_TOF1 Msg205_PAS_Sonar9_Counter PAS_Sonar9_RingingTime PAS_Sonar9_Emit PAS_Sonar9_Echo_Peak2 PAS_Sonar9_Echo_Peak1 PAS_Sonar9_Echo_Width2 PAS_Sonar9_Echo_TOF2 PAS_Sonar9_Echo_Width1 PAS_Sonar9_Echo_TOF1 Msg205_PAS_Sonar8_Counter PAS_Sonar8_RingingTime PAS_Sonar8_Emit PAS_Sonar8_Echo_Peak2 PAS_Sonar8_Echo_Peak1 PAS_Sonar8_Echo_TOF2 PAS_Sonar8_Echo_Width2 PAS_Sonar8_Echo_Width1 PAS_Sonar8_Echo_TOF1 Msg205_PAS_Sonar7_Counter PAS_Sonar7_RingingTime PAS_Sonar7_Emit PAS_Sonar7_Echo_Peak2 PAS_Sonar7_Echo_Peak1 PAS_Sonar7_Echo_Width2 PAS_Sonar7_Echo_TOF2 PAS_Sonar7_Echo_Width1 PAS_Sonar7_Echo_TOF1 Msg205_PAS_Sonar6_Counter PAS_Sonar6_RingingTime PAS_Sonar6_Emit PAS_Sonar6_Echo_Peak2 PAS_Sonar6_Echo_Peak1 PAS_Sonar6_Echo_Width2 PAS_Sonar6_Echo_TOF2 PAS_Sonar6_Echo_Width1 PAS_Sonar6_Echo_TOF1;
SIG_GROUP_ 544 SG_PAS_0X220 1 : MSG220_Fill4bit PAS_Reponse_Checksum PAS_Reponse_RollingCounter PAS_SonarMode_Response PAS_WakeUp_Response;
SIG_GROUP_ 560 SG_PAS_0X230 1 : sensorVersion_Status MSG230_Fill4bit PAS_SensorStatus_Checksum PAS_SensorStatus_RollingCounter PAS_ECU_VehStatus_Reponse PAS_ECU_Status PAS_SensorStsSR_RR PAS_SensorStsSR_RML PAS_SensorStsSR_RMR PAS_SensorStsSR_RL PAS_SensorStsLR_RRS PAS_SensorStsLR_RLS PAS_SensorStsSR_FR PAS_SensorStsSR_FMR PAS_SensorStsSR_FML PAS_SensorStsSR_FL PAS_SensorStsLR_FRS PAS_SensorStsLR_FLS;
SIG_GROUP_ 576 SG_PAS_0X240 1 : MSG240_Fill4bit PAS_ECUInfo_RollingCounter PAS_ECU_Version_Checksum PAS_ECU_Information_Date_Day PAS_ECU_Information_Date_Month PAS_ECU_Information_Date_Year PAS_ECU_Information_Ver_Boot PAS_ECU_Information_Ver_Soft PAS_ECU_Information_Ver_Hard;
SIG_GROUP_ 592 SG_PAS_0X250 1 : MSG250_Fill4bit Rpt_Alarm_RollingCounter Rpt_Alarm_Checksum Rpt_Alarm_Para3 Rpt_Alarm_Para2 Rpt_Alarm_Para1 Rpt_Transaction_Id Rpt_Alarm_Level Rpt_Alarm_State Rpt_Alarm_Id;
SIG_GROUP_ 593 SG_PAS_0X251 1 : Sensor_Version_Fail VHM_Error USS_Rear_ShortToUbat USS_Rear_ShortToGND USS_Front_ShortToUbat USS_Front_ShortToGND PAS_Sonar11_Internal_failure PAS_Sonar10_Internal_failure PAS_Sonar9_Internal_failure PAS_Sonar8_Internal_failure PAS_Sonar7_Internal_failure PAS_Sonar6_Internal_failure PAS_Sonar5_Internal_failure PAS_Sonar4_Internal_failure PAS_Sonar3_Internal_failure PAS_Sonar2_Internal_failure PAS_Sonar1_Internal_failure PAS_Sonar0_Internal_failure PAS_AUTHEN_ERROR PAS_KEYLEARN_ERROR PAS_TIMESYNC_ERROR PAS_ECU_INTERNAL_ERROR PAS_MDCSIGNAL_ERROR MSG251_Fill4bit PAS_DiagnosisInfo_Checksum PAS_ECU_EEPROM_ERROR PAS_DiagnosisInfo_RollingCounter PAS_MDC_COMMU_ERROR PAS_ECU_BusOff_ERROR PAS_ECU_UnderVoltage PAS_ECU_OverVoltage PAS_Sonar11_TypeMismatch PAS_Sonar11_RingingTimeFailure PAS_Sonar11_ShortToPositivePole PAS_Sonar11_ShortToGND PAS_Sonar11_ControlBusFailure PAS_Sonar6_ShortToPositivePole PAS_Sonar6_TypeMismatch PAS_Sonar6_ShortToGND PAS_Sonar6_RingingTimeFailure PAS_Sonar6_ControlBusFailure PAS_Sonar5_TypeMismatch PAS_Sonar5_ShortToPositivePole PAS_Sonar5_ShortToGND PAS_Sonar5_RingingTimeFailure PAS_Sonar5_ControlBusFailure PAS_Sonar0_TypeMismatch PAS_Sonar0_ShortToPositivePole PAS_Sonar0_ShortToGND PAS_Sonar0_RingingTimeFailure PAS_Sonar0_ControlBusFailure PAS_Sonar10_TypeMismatch PAS_Sonar10_ShortToPositivePole PAS_Sonar10_ShortToGND PAS_Sonar10_RingingTimeFailure PAS_Sonar10_ControlBusFailure PAS_Sonar9_TypeMismatch PAS_Sonar9_ShortToPositivePole PAS_Sonar9_ShortToGND PAS_Sonar9_RingingTimeFailure PAS_Sonar9_ControlBusFailure PAS_Sonar8_TypeMismatch PAS_Sonar8_ShortToPositivePole PAS_Sonar8_ShortToGND PAS_Sonar8_RingingTimeFailure PAS_Sonar8_ControlBusFailure PAS_Sonar7_TypeMismatch PAS_Sonar7_ShortToGND PAS_Sonar7_ShortToPositivePole PAS_Sonar7_RingingTimeFailure PAS_Sonar7_ControlBusFailure PAS_Sonar4_TypeMismatch PAS_Sonar4_ShortToPositivePole PAS_Sonar4_ShortToGND PAS_Sonar4_RingingTimeFailure PAS_Sonar4_ControlBusFailure PAS_Sonar3_PowerVoltage_High PAS_Sonar3_PowerVoltage_Low PAS_Sonar3_TypeMismatch PAS_Sonar3_ShortToPositivePole PAS_Sonar3_ShortToGND PAS_Sonar3_RingingTimeFailure PAS_Sonar3_ControlBusFailure PAS_Sonar2_TypeMismatch PAS_Sonar2_ShortToPositivePole PAS_Sonar2_ShortToGND PAS_Sonar2_RingingTimeFailure PAS_Sonar2_ControlBusFailure PAS_Sonar1_TypeMismatch PAS_Sonar1_ShortToPositivePole PAS_Sonar1_ShortToGND PAS_Sonar1_RingingTimeFailure PAS_Sonar1_ControlBusFailure;
SIG_GROUP_ 672 SG_PAS_0X2A0 1 : PAS_Device_Vertify_Status PAS_Device_Vertify_Times;
SIG_GROUP_ 673 SG_PAS_0X2A1 1 : PAS_SessionID PAS_RandomByte8 PAS_RandomByte7 PAS_RandomByte6 PAS_RandomByte5 PAS_RandomByte4 PAS_RandomByte3 PAS_RandomByte2 PAS_RandomByte1;
SIG_GROUP_ 674 SG_PAS_0X2A2 1 : PAS_CMACByte8 PAS_CMACByte7 PAS_CMACByte6 PAS_CMACByte5 PAS_CMACByte4 PAS_CMACByte3 PAS_CMACByte2 PAS_CMACByte1 PAS_SessionID PAS_Verification_Result;
SIG_GROUP_ 706 SG_PAS_0X2C2 1 : PAS_SK_Learn_Status12 PAS_SKID12 PAS_SK_Learn_Status11 PAS_SKID11 PAS_SK_Learn_Status10 PAS_SKID10 PAS_SK_Learn_Status9 PAS_SKID9 PAS_SK_Learn_Status8 PAS_SKID8 PAS_SKID7 PAS_SK_Learn_Status7 PAS_SK_Learn_Status6 PAS_SKID6 PAS_SK_Learn_Status5 PAS_SKID5 PAS_SK_Learn_Status4 PAS_SKID4 PAS_SK_Learn_Status3 PAS_SKID3 PAS_SK_Learn_Status2 PAS_SKID2 PAS_SK_Learn_Status1 PAS_SKID1 PAS_Key_Learn_Numbers PAS_Key_Learn_SubID;
SIG_GROUP_ 708 SG_PAS_0X2C4 1 : PAS_SK_Setting_Status PAS_SK_Setting_Response PASKeyLearnSubIDSettingResponse;
SIG_GROUP_ 707 SG_PAS_0X2C3 1 : PAS_Verify_IVByte12 PAS_Verify_IVByte11 PAS_Verify_IVByte10 PAS_Verify_IVByte9 PAS_Verify_IVByte8 PAS_Verify_IVByte7 PAS_Verify_IVByte6 PAS_Verify_IVByte5 PAS_Verify_IVByte4 PAS_Verify_IVByte3 PAS_Verify_IVByte2 PAS_Verify_IVByte1 PAS_Verify_MACbyte16 PAS_Verify_MACbyte15 PAS_Verify_MACbyte14 PAS_Verify_MACbyte13 PAS_Verify_MACbyte12 PAS_Verify_MACbyte11 PAS_Verify_MACbyte10 PAS_Verify_MACbyte9 PAS_Verify_MACbyte8 PAS_Verify_MACbyte7 PAS_Verify_MACbyte6 PAS_Verify_MACbyte5 PAS_Verify_MACbyte4 PAS_Verify_MACbyte3 PAS_Verify_MACbyte2 PAS_Verify_MACbyte1 PAS_Verify_AES_Result PAS_Verify_SKID PAS_VerifySubID;
SIG_GROUP_ 640 SG_UPC_0X280 1 : PAS_VehPos_RollingCounter PAS_VehPos_Checksum UPCVehiclePositionDriveDistance UPC_VehiclePosition_YawAngle UPC_VehiclePosition_Curvature UPCVehiclePositionUpdateTime UPC_VehiclePosition_Y UPC_VehiclePosition_X;
SIG_GROUP_ 641 SG_PAS_0X281 1 : PAS_PSL_RollingCounter PAS_PSL_Checksum PAS_PSL_Status;
SIG_GROUP_ 642 SG_PAS_0X282 1 : PAS_EchoMap_RollingCounter PAS_EchoMap_Checksum PAS_MapObject_OuputStatus PAS_Echo_WorkMode;
SIG_GROUP_ 768 SG_MDC_0X300 1 : MSG300_Fill4bit MDC_PAS_Control_Checksum MDC_PAS_Control_RollingCounter MDC_PAS_Control;
SIG_GROUP_ 769 SG_MDC_0X301 1 : ecasVehiclePositionState ecasVehicleUpDownState VehiclePositionStateValid VehicleUpDownStateValid wheelspeedRl wheelspeedRr wheelspeedFr wheelspeedFl wheelspeedValid YawRateSensor_St YawRate MDC_VehStatus_Checksum MDC_VehStatus_RollingCounter MDC_ESC_RRWheelDirection_Valid MDC_ESC_RRWheelDirection MDC_ESC_RLWheelDirection_Valid MDC_ESC_RLWheelDirection MDC_ESC_FRWheelDirection_Valid MDC_ESC_FRWheelDirection MDC_ESC_FLWheelDirection_Valid MDC_ESC_FLWheelDirection MDC_ESC_RRWheelSpeedRC_Valid MDC_ESC_RRWheelSpeedRC MDC_ESC_RLWheelSpeedRC_Valid MDC_ESC_RLWheelSpeedRC MDC_ESC_FRWheelSpeedRC_Valid MDC_ESC_FRWheelSpeedRC MDC_ESC_FLWheelSpeedRC_Valid MDC_ESC_FLWheelSpeedRC MDC_VCU_GearStatus_Valid MDC_VCU_GearStatus MDC_BCM_OutTemp_Valid MDC_BCM_OutTemp MDC_SAS_SteerWheelAngle_Valid MDC_SAS_SteerWheelAngle MDC_ESC_VehicleSpeed_Valid MDC_ESC_VehicleSpeed;
SIG_GROUP_ 770 SG_PAS_0X302 1 : MSG302_Fill4bit PAS_Function_Req Sonar_Req_Checksum Sonar_Req_RollingCounter PAS_Sonar11_Req_counter PAS_Sonar11_Req PAS_Sonar6_Req_counter PAS_Sonar6_Req PAS_Sonar5_Req_counter PAS_Sonar5_Req PAS_Sonar0_Req_counter PAS_Sonar0_Req PAS_Sonar10_Req_counter PAS_Sonar10_Req PAS_Sonar9_Req_counter PAS_Sonar9_Req PAS_Sonar8_Req_counter PAS_Sonar8_Req PAS_Sonar7_Req_counter PAS_Sonar7_Req PAS_Sonar4_Req_counter PAS_Sonar4_Req PAS_Sonar3_Req_counter PAS_Sonar3_Req PAS_Sonar2_Req_counter PAS_Sonar2_Req PAS_Sonar1_Req_counter PAS_Sonar1_Req;
SIG_GROUP_ 771 SG_PAS_0X303 1 : MSG303_Fill4bit Ack_Alarm_RollingCounter Ack_Alarm_Checksum Ack_Transaction_Id Ack_Alarm_Level Ack_Alarm_State Ack_Alarm_Id;
SIG_GROUP_ 772 SG_Time_0X304 1 : Sync_SyncTime Sync_Reserved Sync_OVS Sync_SGW Sync_TimeDomain Sync_Counter Sync_CRC Sync_Type;
SIG_GROUP_ 928 SG_MDC_0X3A0 1 : MDC_SessionID MDC_RandomByte8 MDC_RandomByte7 MDC_RandomByte6 MDC_RandomByte5 MDC_RandomByte4 MDC_RandomByte3 MDC_RandomByte2 MDC_RandomByte1;
SIG_GROUP_ 929 SG_MDC_0X3A1 1 : MDC_Response_CMACByte8 MDC_Response_CMACByte7 MDC_Response_CMACByte6 MDC_Response_CMACByte5 MDC_Response_CMACByte4 MDC_Response_CMACByte3 MDC_Response_CMACByte2 MDC_Response_CMACByte1 MDC_Response_SessionID MDC_Response_Result;
SIG_GROUP_ 960 SG_Mdc_0X3C0 1 : Mdc_KeyLearn_SKID12 Mdc_KeyLearn_SKID11 Mdc_KeyLearn_SKID10 Mdc_KeyLearn_SKID9 Mdc_KeyLearn_SKID8 Mdc_KeyLearn_SKID7 Mdc_KeyLearn_SKID6 Mdc_KeyLearn_SKID5 Mdc_KeyLearn_SKID4 Mdc_KeyLearn_SKID3 Mdc_KeyLearn_SKID2 Mdc_KeyLearn_SKID1 Mdc_KeyLearn_Numbers Mdc_KeyLearnSubID;
SIG_GROUP_ 962 SG_Mdc_0X3C2 1 : Mdc_KeyLearn_IVByte12 Mdc_KeyLearn_SC Mdc_KeyLearn_IVByte11 Mdc_KeyLearn_IVByte10 Mdc_KeyLearn_IVByte9 Mdc_KeyLearn_IVByte8 Mdc_KeyLearn_IVByte7 Mdc_KeyLearn_IVByte6 Mdc_KeyLearn_IVByte5 Mdc_KeyLearn_IVByte4 Mdc_KeyLearn_IVByte3 Mdc_KeyLearn_IVByte2 Mdc_KeyLearn_IVByte1 Mdc_KeyLearn_MACByte16 Mdc_KeyLearn_MACByte15 Mdc_KeyLearn_MACByte14 Mdc_KeyLearn_MACByte13 Mdc_KeyLearn_MACByte12 Mdc_KeyLearn_MACByte11 Mdc_KeyLearn_MACByte10 Mdc_KeyLearn_MACByte9 Mdc_KeyLearn_MACByte8 Mdc_KeyLearn_MACByte7 Mdc_KeyLearn_MACByte6 Mdc_KeyLearn_MACByte5 Mdc_KeyLearn_MACByte4 Mdc_KeyLearn_MACByte2 Mdc_KeyLearn_MACByte3 Mdc_KeyLearn_MACByte1 Mdc_KeyLearn_SKCByte16 Mdc_KeyLearn_SKCByte15 Mdc_KeyLearn_SKCByte14 Mdc_KeyLearn_SKCByte13 Mdc_KeyLearn_SKCByte12 Mdc_KeyLearn_SKCByte11 Mdc_KeyLearn_SKCByte10 Mdc_KeyLearn_SKCByte9 Mdc_KeyLearn_SKCByte8 Mdc_KeyLearn_SKCByte7 Mdc_KeyLearn_SKCByte6 Mdc_KeyLearn_SKCByte5 Mdc_KeyLearn_SKCByte4 Mdc_KeyLearn_SKCByte3 Mdc_KeyLearn_SKCByte2 Mdc_KeyLearn_SKCByte1 Mdc_KeyLearn_update_SKID Mdc_KeyLearn_transmit_SKID Mdc_KeyLearnSubID_Send;
SIG_GROUP_ 963 SG_Mdc_0X3C3 1 : Mdc_KeyLearn_SKID Mdc_KeyLearnSubID_SKSetting;
SIG_GROUP_ 964 SG_Mdc_0X3C4 1 : Mdc_KeyLearn_Clean_IVByte12 Mdc_KeyLearn_Clean_IVByte11 Mdc_KeyLearn_Clean_IVByte10 Mdc_KeyLearn_Clean_IVByte9 Mdc_KeyLearn_Clean_IVByte7 Mdc_KeyLearn_Clean_IVByte8 Mdc_KeyLearn_Clean_IVByte6 Mdc_KeyLearn_Clean_IVByte5 Mdc_KeyLearn_Clean_IVByte4 Mdc_KeyLearn_Clean_IVByte3 Mdc_KeyLearn_Clean_IVByte2 Mdc_KeyLearn_Clean_IVByte1 Mdc_KeyLearn_Clean_MACByte16 Mdc_KeyLearn_Clean_MACByte15 Mdc_KeyLearn_Clean_MACByte14 Mdc_KeyLearn_Clean_MACByte13 Mdc_KeyLearn_Clean_MACByte12 Mdc_KeyLearn_Clean_MACByte11 Mdc_KeyLearn_Clean_MACByte10 Mdc_KeyLearn_Clean_MACByte9 Mdc_KeyLearn_Clean_MACByte8 Mdc_KeyLearn_Clean_MACByte7 Mdc_KeyLearn_Clean_MACByte6 Mdc_KeyLearn_Clean_MACByte5 Mdc_KeyLearn_Clean_MACByte4 Mdc_KeyLearn_Clean_MACByte3 Mdc_KeyLearn_Clean_MACByte2 Mdc_KeyLearn_Clean_MACByte1 Mdc_KeyLearn_Clean_SCByte16 Mdc_KeyLearn_Clean_SCByte15 Mdc_KeyLearn_Clean_SCByte14 Mdc_KeyLearn_Clean_SCByte13 Mdc_KeyLearn_Clean_SCByte12 Mdc_KeyLearn_Clean_SCByte11 Mdc_KeyLearn_Clean_SCByte10 Mdc_KeyLearn_Clean_SCByte9 Mdc_KeyLearn_Clean_SCByte8 Mdc_KeyLearn_Clean_SCByte7 Mdc_KeyLearn_Clean_SCByte6 Mdc_KeyLearn_Clean_SCByte5 Mdc_KeyLearn_Clean_SCByte4 Mdc_KeyLearn_Clean_SCByte3 Mdc_KeyLearn_Clean_SCByte2 Mdc_KeyLearn_Clean_SCByte1 Mdc_KeyLearn_Clean_SKID Mdc_KeyLearnSubID_CleanID;
SIG_GROUP_ 961 SG_Mdc_0X3C1 1 : Mdc_Verify_Random Mdc_Verify_SKID Mdc_VerifySubID_Random;
SIG_GROUP_ 965 SG_Mdc_0X3C5 1 : Mdc_Verify_Result_Status Mdc_Verify_Result_SKID Mdc_Verify_ResultID;
SIG_GROUP_ 656 SG_PDC_0X290 1 : Point_06_ExistProbability Point_06_High Point_06_ErrorTheta Point_06_ErrorB Point_06_ErrorA Point_06_Y Point_06_X Point_06_ID Point_06_Valid Point_05_ExistProbability Point_05_ErrorA Point_05_High Point_05_ErrorTheta Point_05_ErrorB Point_05_Y Point_05_X Point_05_Valid Point_05_ID Point_04_ExistProbability Point_04_High Point_04_ErrorTheta Point_04_ErrorB Point_04_ErrorA Point_04_Y Point_04_X Point_04_Valid Point_04_ID Point_03_ExistProbability Point_03_High Point_03_ErrorTheta Point_03_ErrorB Point_03_ErrorA Point_03_Y Point_03_X Point_03_Valid Point_03_ID Point_02_ExistProbability Point_02_High Point_02_ErrorTheta Point_02_ErrorB Point_02_ErrorA Point_02_Y Point_02_X Point_02_Valid Point_02_ID Point_01_ExistProbability Point_01_High Point_01_ErrorTheta Point_01_ErrorB Point_01_ErrorA Point_01_Y Point_01_X Point_01_Valid Point_01_ID Point_00_ExistProbability Point_00_High Point_00_ErrorTheta Point_00_ErrorB Point_00_ErrorA Point_00_Y Point_00_X Point_00_Valid Point_00_ID Point_Priv_0_6_Timestamp;
SIG_GROUP_ 657 SG_PDC_0X291 1 : Point_13_ExistProbability Point_13_High Point_13_ErrorTheta Point_13_ErrorB Point_13_Y Point_13_ErrorA Point_13_X Point_13_Valid Point_13_ID Point_12_ExistProbability Point_12_High Point_12_ErrorTheta Point_12_ErrorB Point_12_ErrorA Point_12_Y Point_12_X Point_12_Valid Point_12_ID Point_11_ExistProbability Point_11_High Point_11_ErrorTheta Point_11_ErrorB Point_11_ErrorA Point_11_Y Point_11_X Point_11_Valid Point_11_ID Point_10_ExistProbability Point_10_High Point_10_ErrorTheta Point_10_ErrorB Point_10_Y Point_10_ErrorA Point_10_X Point_10_ID Point_10_Valid Point_09_ExistProbability Point_09_High Point_09_ErrorTheta Point_09_ErrorB Point_09_ErrorA Point_09_Y Point_09_X Point_09_Valid Point_09_ID Point_08_ExistProbability Point_08_ErrorB Point_08_High Point_08_ErrorTheta Point_08_ErrorA Point_08_Y Point_08_X Point_08_Valid Point_08_ID Point_07_ExistProbability Point_07_High Point_07_ErrorTheta Point_07_ErrorB Point_07_ErrorA Point_07_Y Point_07_X Point_07_Valid Point_07_ID Point_Priv_7_13_Timestamp;
SIG_GROUP_ 658 SG_PDC_0X292 1 : Point_20_High Point_20_ExistProbability Point_20_ErrorA Point_20_ErrorTheta Point_20_ErrorB Point_20_Y Point_20_Valid Point_20_X Point_20_ID Point_19_High Point_19_ExistProbability Point_19_ErrorTheta Point_19_ErrorA Point_19_ErrorB Point_19_Y Point_19_X Point_19_Valid Point_19_ID Point_18_ExistProbability Point_18_High Point_18_ErrorTheta Point_18_ErrorB Point_18_ErrorA Point_18_Y Point_18_X Point_18_Valid Point_18_ID Point_17_ExistProbability Point_17_High Point_17_ErrorTheta Point_17_ErrorB Point_17_ErrorA Point_17_Y Point_17_X Point_17_Valid Point_17_ID Point_16_ExistProbability Point_16_High Point_16_ErrorTheta Point_16_ErrorB Point_16_ErrorA Point_16_Y Point_16_X Point_16_Valid Point_16_ID Point_15_ExistProbability Point_15_High Point_15_ErrorTheta Point_15_ErrorB Point_15_ErrorA Point_15_Y Point_15_X Point_15_Valid Point_15_ID Point_14_ExistProbability Point_14_High Point_14_ErrorTheta Point_14_ErrorB Point_14_ErrorA Point_14_Y Point_14_X Point_14_Valid Point_14_ID Point_Priv_14_20_Timestamp;
